VERSION ""

NS_ :

BS_:

BU_: VCM TBIOM RCIOM FCIOM CCIOM BPMU

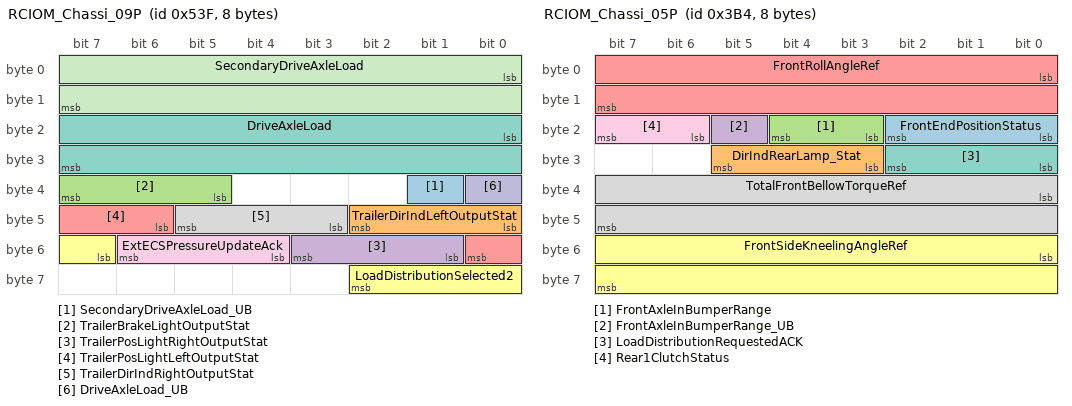
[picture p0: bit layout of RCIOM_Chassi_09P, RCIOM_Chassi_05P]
BO_ 1343 RCIOM_Chassi_09P: 8 RCIOM
 SG_ SecondaryDriveAxleLoad_UB : 33|1@1+ (1,0) [0|0] ""  VCM
 SG_ TrailerDirIndLeftOutputStat : 40|3@1+ (1,0) [0|0] ""  VCM
 SG_ TrailerBrakeLightOutputStat : 37|3@1+ (1,0) [0|0] ""  VCM
 SG_ TrailerPosLightRightOutputStat : 49|3@1+ (1,0) [0|0] ""  VCM
 SG_ TrailerPosLightLeftOutputStat : 46|3@1+ (1,0) [0|0] ""  VCM
 SG_ LoadDistributionSelected2 : 55|4@1+ (1,0) [0|0] ""  VCM
 SG_ DriveAxleLoad : 16|16@1+ (0.5,0) [0|32767.5] "kg"  VCM
 SG_ TrailerDirIndRightOutputStat : 43|3@1+ (1,0) [0|0] ""  VCM
 SG_ ExtECSPressureUpdateAck : 52|3@1+ (1,0) [0|0] ""  VCM
 SG_ DriveAxleLoad_UB : 32|1@1+ (1,0) [0|0] ""  VCM
 SG_ SecondaryDriveAxleLoad : 0|16@1+ (0.5,0) [0|32767.5] "kg"  VCM

BO_ 825 RCIOM_Chassi_08P: 8 RCIOM
 SG_ RevLightLamp_stat : 43|3@1+ (1,0) [0|0] ""  VCM
 SG_ BrakeLightConvoy_rqst_UB : 62|1@1+ (1,0) [0|0] ""  VCM
 SG_ FirstAxleLowerPrioSelected : 27|3@1+ (1,0) [0|0] ""  VCM
 SG_ FrontParkBrakeOverrideInd : 46|2@1+ (1,0) [0|0] ""  VCM
 SG_ ECSLimpHomeNotification : 19|3@1+ (1,0) [0|0] ""  VCM
 SG_ ECSValveActivationAllowed : 30|2@1+ (1,0) [0|0] ""  VCM,CCIOM
 SG_ UnevenLoadWarning : 38|2@1+ (1,0) [0|0] ""  VCM
 SG_ RampLevelRequestACK : 4|2@1+ (1,0) [0|0] ""  VCM
 SG_ LoadDistributionSelected : 12|4@1+ (1,0) [0|0] ""  VCM
 SG_ TrailerABSStatus : 2|2@1+ (1,0) [0|0] ""  VCM
 SG_ RevLight_cmd : 6|2@1+ (1,0) [0|0] ""  VCM,CCIOM
 SG_ LoadDistributionALDChangeACK : 32|3@1+ (1,0) [0|0] ""  VCM
 SG_ FogLightRearLamp_stat : 48|3@1+ (1,0) [0|0] ""  VCM
 SG_ PositionLightRearLamp_stat : 40|3@1+ (1,0) [0|0] ""  VCM
 SG_ FerryFunctionSwitchChangeACK : 0|2@1+ (1,0) [0|0] ""  VCM
 SG_ BrakeLight_rqst : 16|3@1+ (1,0) [0|0] ""  VCM
 SG_ BrakeLight_rqst_UB : 55|1@1+ (1,0) [0|0] ""  VCM
 SG_ BrakeLightConvoy_rqst : 22|2@1+ (1,0) [0|0] ""  VCM
 SG_ LiftAxle1AutoLiftSelected : 8|2@1+ (1,0) [0|0] ""  VCM
 SG_ BrakeLightLamp_stat : 35|3@1+ (1,0) [0|0] ""  VCM
 SG_ LiftAxle2AutoLiftSelected : 10|2@1+ (1,0) [0|0] ""  VCM
 SG_ StartupProhibitStatus : 53|2@1+ (1,0) [0|0] ""  VCM
 SG_ LiftAxle1LowerACK : 24|3@1+ (1,0) [0|0] ""  VCM
 SG_ TrailerDirInd_status : 56|3@1+ (1,0) [0|0] ""  VCM
 SG_ DriveLevelPosUserInteraction : 59|3@1+ (1,0) [0|0] ""  VCM

BO_ 948 RCIOM_Chassi_05P: 8 RCIOM
 SG_ FrontEndPositionStatus : 16|3@1+ (1,0) [0|0] ""  VCM
 SG_ DirIndRearLamp_Stat : 27|3@1+ (1,0) [0|0] ""  VCM
 SG_ FrontAxleInBumperRange : 19|2@1+ (1,0) [0|0] ""  VCM
 SG_ FrontAxleInBumperRange_UB : 21|1@1+ (1,0) [0|0] ""  VCM
 SG_ FrontRollAngleRef : 0|16@1+ (0.001,-30) [-30|35.535] "deg"  VCM,CCIOM
 SG_ FrontSideKneelingAngleRef : 48|16@1+ (0.001,-30) [-30|35.535] "deg"  CCIOM,VCM
 SG_ LoadDistributionRequestedACK : 24|3@1+ (1,0) [0|0] ""  VCM
 SG_ TotalFrontBellowTorqueRef : 32|16@1+ (1000,-10000000) [-10000000|55535000] "Nm"  VCM,CCIOM
 SG_ Rear1ClutchStatus : 22|2@1+ (1,0) [0|0] ""  VCM

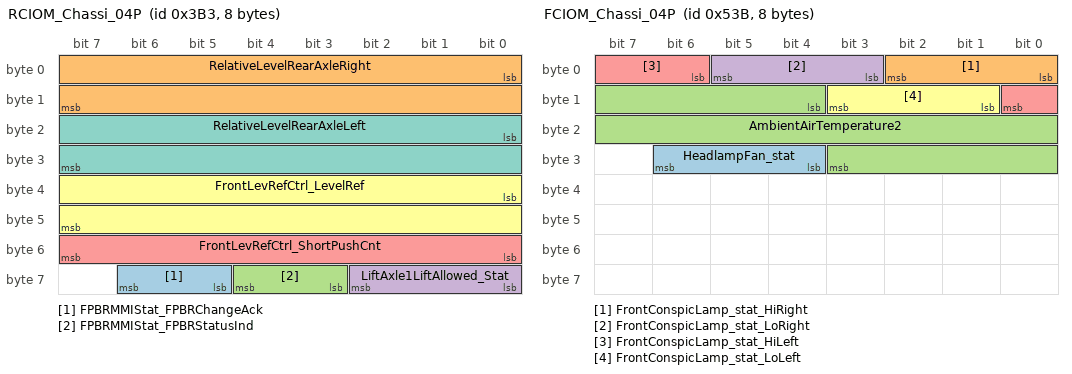
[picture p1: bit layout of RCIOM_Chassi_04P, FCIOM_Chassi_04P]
BO_ 947 RCIOM_Chassi_04P: 8 RCIOM
 SG_ FPBRMMIStat_FPBRChangeAck : 61|2@1+ (1,0) [0|0] ""  VCM
 SG_ RelativeLevelRearAxleRight : 0|16@1+ (0.1,-3200) [-3200|3353.5] "mm"  VCM
 SG_ FPBRMMIStat_FPBRStatusInd : 59|2@1+ (1,0) [0|0] ""  VCM
 SG_ LiftAxle1LiftAllowed_Stat : 56|3@1+ (1,0) [0|0] ""  VCM
 SG_ FrontLevRefCtrl_ShortPushCnt : 48|8@1+ (1,0) [0|255] "Count"  VCM,CCIOM
 SG_ FrontLevRefCtrl_LevelRef : 32|16@1+ (0.1,-3200) [-3200|3353.5] "mm"  CCIOM,VCM
 SG_ RelativeLevelRearAxleLeft : 16|16@1+ (0.1,-3200) [-3200|3353.5] "mm"  VCM

BO_ 530 RCIOM_Chassi_03P: 8 RCIOM
 SG_ AirDumpStatus : 60|3@1+ (1,0) [0|0] ""  VCM
 SG_ RearAxle2DiffLock_stat : 46|2@1+ (1,0) [0|0] ""  VCM
 SG_ SWBrakeSwitch_UB : 51|1@1+ (1,0) [0|0] ""  VCM
 SG_ SWBrakeSwitch : 49|2@1+ (1,0) [0|0] ""  VCM
 SG_ RearAxle1DiffLock_stat : 43|2@1+ (1,0) [0|0] ""  VCM
 SG_ SupplyPressure : 0|8@1+ (8,0) [0|2040] "kPa"  VCM,CCIOM
 SG_ RearAxle2DiffLock_stat_UB : 48|1@1+ (1,0) [0|0] ""  VCM
 SG_ BackToDriveReqACK : 58|2@1+ (1,0) [0|0] ""  VCM
 SG_ PitchAngleRef : 24|16@1+ (0.001,-30) [-30|35.535] "deg"  VCM,CCIOM
 SG_ TrailerConnected_UB : 54|1@1+ (1,0) [0|0] ""  VCM,CCIOM
 SG_ CentralRearDiffLock_stat_UB : 42|1@1+ (1,0) [0|0] ""  VCM
 SG_ PitchAngle : 8|16@1+ (0.001,-30) [-30|35.535] "deg"  VCM,CCIOM
 SG_ TrailerWithoutABS : 56|2@1+ (1,0) [0|0] ""  VCM
 SG_ TrailerWithoutABS_UB : 55|1@1+ (1,0) [0|0] ""  VCM
 SG_ TrailerConnected : 52|2@1+ (1,0) [0|0] ""  VCM,CCIOM
 SG_ CentralRearDiffLock_stat : 40|2@1+ (1,0) [0|0] ""  VCM
 SG_ RearAxle1DiffLock_stat_UB : 45|1@1+ (1,0) [0|0] ""  VCM

BO_ 528 RCIOM_Chassi_02P: 8 RCIOM
 SG_ RollEndPositionStatus : 3|3@1+ (1,0) [0|0] ""  VCM
 SG_ FrontFerryFunctionCmd : 59|3@1+ (1,0) [0|0] ""  VCM,CCIOM
 SG_ RideHeightFunctionStatus : 36|4@1+ (1,0) [0|0] ""  VCM
 SG_ HeightControlMode : 32|4@1+ (1,0) [0|0] ""  CCIOM,VCM
 SG_ ECSShutdownCmd : 43|2@1+ (1,0) [0|0] ""  VCM,CCIOM
 SG_ FerryFunctionStatus : 56|3@1+ (1,0) [0|0] ""  VCM
 SG_ LevelControlInformation : 16|4@1+ (1,0) [0|0] ""  VCM
 SG_ ChangeKneelACK : 45|2@1+ (1,0) [0|0] ""  VCM
 SG_ RearEndPositionStatus : 48|3@1+ (1,0) [0|0] ""  VCM
 SG_ RampHeightOutsideTargetRange : 51|3@1+ (1,0) [0|0] ""  VCM
 SG_ LoadDistributionFuncSelected : 28|4@1+ (1,0) [0|0] ""  VCM
 SG_ HeightAdjustmentAllowed : 54|2@1+ (1,0) [0|0] ""  VCM
 SG_ LevelControlInformation_UB : 40|1@1+ (1,0) [0|0] ""  VCM
 SG_ KneelingInformation : 24|4@1+ (1,0) [0|0] ""  VCM
 SG_ KneelingStatusHMI : 41|2@1+ (1,0) [0|0] ""  VCM
 SG_ LiftAxle1PositionStatus : 8|3@1+ (1,0) [0|0] ""  CCIOM,VCM
 SG_ VehicleDynamicSuspProhibitStat : 62|2@1+ (1,0) [0|0] ""  CCIOM,VCM
 SG_ LiftAxle2PositionStatus : 11|3@1+ (1,0) [0|0] ""  VCM
 SG_ RideHeightStatus : 20|4@1+ (1,0) [0|0] ""  VCM
 SG_ DirInd_Rear_Status : 0|3@1+ (1,0) [0|0] ""  VCM

BO_ 517 RCIOM_Chassi_01P: 8 RCIOM
 SG_ FrontProhibitControlRequest : 4|2@1+ (1,0) [0|0] ""  CCIOM,VCM
 SG_ RampLevelStorageAck : 24|2@1+ (1,0) [0|0] ""  VCM
 SG_ BrakePressureSensorDemand_UB : 1|1@1+ (1,0) [0|0] ""  VCM
 SG_ FrontLimpHomeCmd : 50|3@1+ (1,0) [0|0] ""  VCM,CCIOM
 SG_ LiftingControlModeRearAxle : 18|2@1+ (1,0) [0|0] ""  VCM
 SG_ LoadDistributionChangeACK : 56|3@1+ (1,0) [0|0] ""  VCM
 SG_ ECSStandbyAllowed : 32|2@1+ (1,0) [0|0] ""  VCM
 SG_ LiftAxle2LiftFuncSelected : 59|3@1+ (1,0) [0|0] ""  VCM
 SG_ LiftAxle2UpRequestACK : 34|3@1+ (1,0) [0|0] ""  VCM
 SG_ ProhibitControlStatus : 62|2@1+ (1,0) [0|0] ""  VCM
 SG_ RampLevelStatus : 46|4@1+ (1,0) [0|0] ""  VCM
 SG_ StopLevelChangeAck : 16|2@1+ (1,0) [0|0] ""  VCM
 SG_ LiftAxle2LowerACK : 37|3@1+ (1,0) [0|0] ""  VCM
 SG_ RideHeightStorageAck : 6|2@1+ (1,0) [0|0] ""  VCM
 SG_ FrontParkBrakeOverrideCommand : 22|2@1+ (1,0) [0|0] ""  VCM
 SG_ RideHeightOutsideTargetRange : 43|3@1+ (1,0) [0|0] ""  VCM
 SG_ DisableMechFaultDctnFr_rqst : 26|2@1+ (1,0) [0|0] ""  VCM,CCIOM
 SG_ RearAxleInBumperRange_UB : 0|1@1+ (1,0) [0|0] ""  VCM
 SG_ BrakePressureSensorDemand : 8|8@1+ (1,0) [0|255] "Percent"  VCM
 SG_ FogLamp_Rear_Status : 20|2@1+ (1,0) [0|0] ""  VCM
 SG_ LiftingControlModeFrontAxle : 2|2@1+ (1,0) [0|0] ""  VCM
 SG_ LiftAxle1UpRequestACK : 40|3@1+ (1,0) [0|0] ""  VCM
 SG_ LiftAxle1LiftFuncSelected : 53|3@1+ (1,0) [0|0] ""  VCM
 SG_ RearAxleInBumperRange : 30|2@1+ (1,0) [0|0] ""  VCM

BO_ 2671833639 PhysDiagRespMsg_F2_27_C04: 8 TBIOM
 SG_ PhysDiagRespSig_F2_27 : 0|64@1+ (1,0) [0|0] ""  VCM

BO_ 2671833634 PhysDiagRespMsg_F2_22_C04: 8 RCIOM
 SG_ PhysDiagRespSig_F2_22 : 0|64@1+ (1,0) [0|0] ""  VCM

BO_ 2671833633 PhysDiagRespMsg_F2_21_C04: 8 FCIOM
 SG_ PhysDiagRespSig_F2_21 : 0|64@1+ (1,0) [0|0] ""  VCM

BO_ 2671833632 PhysDiagRespMsg_F2_20_C04: 8 CCIOM
 SG_ PhysDiagRespSig_F2_20 : 0|64@1+ (1,0) [0|0] ""  VCM

BO_ 2671833626 PhysDiagRespMsg_F2_1A_C04: 8 BPMU
 SG_ PhysDiagRespSig_F2_1A : 0|64@1+ (1,0) [0|0] ""  VCM

BO_ 2671781874 PhysDiagReqMsg_27_F2_C04: 8 VCM
 SG_ PhysDiagReqSig_27_F2 : 0|64@1+ (1,0) [0|0] ""  TBIOM

BO_ 2671780594 PhysDiagReqMsg_22_F2_C04: 8 VCM
 SG_ PhysDiagReqSig_22_F2 : 0|64@1+ (1,0) [0|0] ""  RCIOM

BO_ 2671780338 PhysDiagReqMsg_21_F2_C04: 8 VCM
 SG_ PhysDiagReqSig_21_F2 : 0|64@1+ (1,0) [0|0] ""  FCIOM

BO_ 2671780082 PhysDiagReqMsg_20_F2_C04: 8 VCM
 SG_ PhysDiagReqSig_20_F2 : 0|64@1+ (1,0) [0|0] ""  CCIOM

BO_ 2671778546 PhysDiagReqMsg_1A_F2_C04: 8 VCM
 SG_ PhysDiagReqSig_1A_F2 : 0|64@1+ (1,0) [0|0] ""  BPMU

BO_ 2633990180 NmAsr_VCM_C04: 1 VCM

BO_ 2633990183 NmAsr_TBIOM_C04: 1 TBIOM

BO_ 2633990178 NmAsr_RCIOM_C04: 1 RCIOM

BO_ 2633990177 NmAsr_FCIOM_C04: 1 FCIOM

BO_ 2633990176 NmAsr_CCIOM_C04: 1 CCIOM

BO_ 2633990170 NmAsr_BPMU_C04: 1 BPMU

BO_ 1339 FCIOM_Chassi_04P: 8 FCIOM
 SG_ HeadlampFan_stat : 28|3@1+ (1,0) [0|0] ""  VCM
 SG_ FrontConspicLamp_stat_HiRight : 0|3@1+ (1,0) [0|0] ""  VCM
 SG_ AmbientAirTemperature2 : 12|16@1+ (0.03125,-273) [-273|1774.96875] "DegreeC"  VCM
 SG_ FrontConspicLamp_stat_LoRight : 3|3@1+ (1,0) [0|0] ""  VCM
 SG_ FrontConspicLamp_stat_HiLeft : 6|3@1+ (1,0) [0|0] ""  VCM
 SG_ FrontConspicLamp_stat_LoLeft : 9|3@1+ (1,0) [0|0] ""  VCM

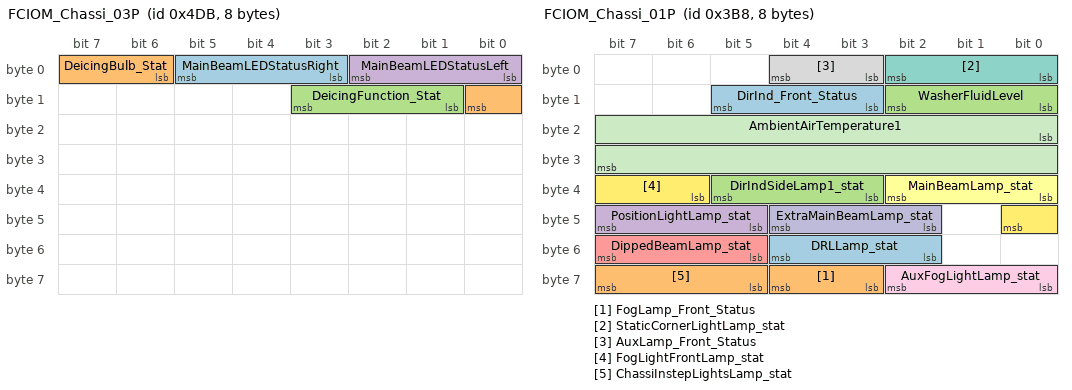
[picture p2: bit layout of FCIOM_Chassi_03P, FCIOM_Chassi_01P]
BO_ 1243 FCIOM_Chassi_03P: 8 FCIOM
 SG_ MainBeamLEDStatusRight : 3|3@1+ (1,0) [0|0] ""  VCM
 SG_ DeicingBulb_Stat : 6|3@1+ (1,0) [0|0] ""  VCM
 SG_ DeicingFunction_Stat : 9|3@1+ (1,0) [0|0] ""  VCM
 SG_ MainBeamLEDStatusLeft : 0|3@1+ (1,0) [0|0] ""  VCM

BO_ 952 FCIOM_Chassi_01P: 8 FCIOM
 SG_ DRLLamp_stat : 50|3@1+ (1,0) [0|0] ""  VCM
 SG_ FogLamp_Front_Status : 59|2@1+ (1,0) [0|0] ""  VCM
 SG_ DirIndSideLamp1_stat : 35|3@1+ (1,0) [0|0] ""  VCM
 SG_ PositionLightLamp_stat : 45|3@1+ (1,0) [0|0] ""  VCM
 SG_ DippedBeamLamp_stat : 53|3@1+ (1,0) [0|0] ""  VCM
 SG_ MainBeamLamp_stat : 32|3@1+ (1,0) [0|0] ""  VCM
 SG_ StaticCornerLightLamp_stat : 0|3@1+ (1,0) [0|0] ""  VCM
 SG_ AuxLamp_Front_Status : 3|2@1+ (1,0) [0|0] ""  VCM
 SG_ AuxFogLightLamp_stat : 56|3@1+ (1,0) [0|0] ""  VCM
 SG_ ExtraMainBeamLamp_stat : 42|3@1+ (1,0) [0|0] ""  VCM
 SG_ AmbientAirTemperature1 : 16|16@1+ (0.03125,-273) [-273|1774.96875] "DegreeC"  VCM
 SG_ FogLightFrontLamp_stat : 38|3@1+ (1,0) [0|0] ""  VCM
 SG_ DirInd_Front_Status : 11|3@1+ (1,0) [0|0] ""  VCM
 SG_ ChassiInstepLightsLamp_stat : 61|3@1+ (1,0) [0|0] ""  VCM
 SG_ WasherFluidLevel : 8|3@1+ (1,0) [0|0] ""  VCM

BO_ 1232 EBS_Chassi_13P: 8 VCM
 SG_ TrailerCommunicationType : 26|3@1+ (1,0) [0|0] ""  RCIOM

BO_ 396 EBS_Chassi_08P: 8 VCM
 SG_ ThrdRrDriveAxLeftWheelSpeed : 32|16@1+ (0.00390625,0) [0|255.99609375] "Km_per_h"  RCIOM
 SG_ ThrdRrDriveAxRightWheelSpeed : 48|16@1+ (0.00390625,0) [0|255.99609375] "Km_per_h"  RCIOM

BO_ 395 EBS_Chassi_07P: 8 VCM
 SG_ SteeringWheelAngle : 0|16@1+ (0.0009765625,-31.374) [-31.374|32.6250234375] "rad"  RCIOM
 SG_ SteeringWheelAngle_UB : 48|1@1+ (1,0) [0|0] ""  RCIOM

BO_ 394 EBS_Chassi_06P: 8 VCM
 SG_ ScndRrDriveAxleLeftWheelSpeed : 48|16@1+ (0.00390625,0) [0|255.99609375] "Km_per_h"  CCIOM,RCIOM
 SG_ ScndRrDriveAxleRightWheelSpeed : 0|16@1+ (0.00390625,0) [0|255.99609375] "Km_per_h"  RCIOM,CCIOM

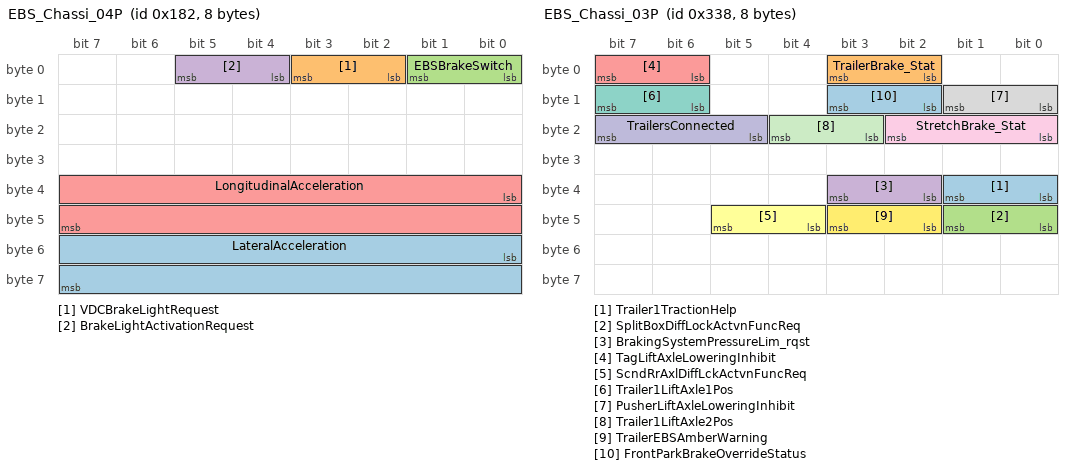
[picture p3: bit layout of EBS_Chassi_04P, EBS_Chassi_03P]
BO_ 386 EBS_Chassi_04P: 8 VCM
 SG_ LateralAcceleration : 48|16@1+ (0.00048828125,-15.687) [-15.687|16.31251171875] "m_per_s_squared"  RCIOM
 SG_ VDCBrakeLightRequest : 2|2@1+ (1,0) [0|0] ""  RCIOM
 SG_ EBSBrakeSwitch : 0|2@1+ (1,0) [0|0] ""  RCIOM
 SG_ BrakeLightActivationRequest : 4|2@1+ (1,0) [0|0] ""  RCIOM
 SG_ LongitudinalAcceleration : 32|16@1+ (0.00048828125,-15.687) [-15.687|16.31251171875] "m_per_s_squared"  RCIOM

BO_ 824 EBS_Chassi_03P: 8 VCM
 SG_ Trailer1TractionHelp : 32|2@1+ (1,0) [0|0] ""  RCIOM
 SG_ TrailerBrake_Stat : 2|2@1+ (1,0) [0|0] ""  RCIOM
 SG_ SplitBoxDiffLockActvnFuncReq : 40|2@1+ (1,0) [0|0] ""  CCIOM
 SG_ BrakingSystemPressureLim_rqst : 34|2@1+ (1,0) [0|0] ""  CCIOM
 SG_ TagLiftAxleLoweringInhibit : 6|2@1+ (1,0) [0|0] ""  RCIOM
 SG_ ScndRrAxlDiffLckActvnFuncReq : 44|2@1+ (1,0) [0|0] ""  RCIOM
 SG_ Trailer1LiftAxle1Pos : 14|2@1+ (1,0) [0|0] ""  RCIOM
 SG_ PusherLiftAxleLoweringInhibit : 8|2@1+ (1,0) [0|0] ""  RCIOM
 SG_ StretchBrake_Stat : 16|3@1+ (1,0) [0|0] ""  RCIOM
 SG_ TrailersConnected : 21|3@1+ (1,0) [0|7] "Count"  RCIOM
 SG_ Trailer1LiftAxle2Pos : 19|2@1+ (1,0) [0|0] ""  RCIOM
 SG_ TrailerEBSAmberWarning : 42|2@1+ (1,0) [0|0] ""  RCIOM
 SG_ FrontParkBrakeOverrideStatus : 10|2@1+ (1,0) [0|0] ""  RCIOM

BO_ 516 EAS_Chassi_01P: 8 VCM
 SG_ EASPusherLiftAxleLoweringInhib : 32|2@1+ (1,0) [0|0] ""  RCIOM

BO_ 1110 DummyFrame_VCM_C_C04: 8 VCM
 SG_ DummyApplicationSignal : 0|8@1+ (1,0) [0|255] ""  CCIOM,BPMU,FCIOM,RCIOM,TBIOM

BO_ 2671964711 DiagUUDTRespMsg1_F2_27_C04: 8 TBIOM
 SG_ DiagUUDTRespSig_F2_27 : 0|64@1+ (1,0) [0|0] ""  VCM

BO_ 2671964706 DiagUUDTRespMsg1_F2_22_C04: 8 RCIOM
 SG_ DiagUUDTRespSig_F2_22 : 0|64@1+ (1,0) [0|0] ""  VCM

BO_ 2671964705 DiagUUDTRespMsg1_F2_21_C04: 8 FCIOM
 SG_ DiagUUDTRespSig_F2_21 : 0|64@1+ (1,0) [0|0] ""  VCM

BO_ 2671964704 DiagUUDTRespMsg1_F2_20_C04: 8 CCIOM
 SG_ DiagUUDTRespSig_F2_20 : 0|64@1+ (1,0) [0|0] ""  VCM

BO_ 2671964698 DiagUUDTRespMsg1_F2_1A_C04: 8 BPMU
 SG_ DiagUUDTRespSig_F2_1A : 0|64@1+ (1,0) [0|0] ""  VCM

BO_ 2671834151 DiagRespMsgForIntTest_F4_27_C04: 8 TBIOM
 SG_ InternalTesterDiagSig_F4_27 : 0|64@1+ (1,0) [0|0] ""  VCM

BO_ 2671834146 DiagRespMsgForIntTest_F4_22_C04: 8 RCIOM
 SG_ InternalTesterDiagSig_F4_22 : 0|64@1+ (1,0) [0|0] ""  VCM

BO_ 2671834145 DiagRespMsgForIntTest_F4_21_C04: 8 FCIOM
 SG_ InternalTesterDiagSig_F4_21 : 0|64@1+ (1,0) [0|0] ""  VCM

BO_ 2671834144 DiagRespMsgForIntTest_F4_20_C04: 8 CCIOM
 SG_ InternalTesterDiagSig_F4_20 : 0|64@1+ (1,0) [0|0] ""  VCM

BO_ 2671834138 DiagRespMsgForIntTest_F4_1A_C04: 8 BPMU
 SG_ InternalTesterDiagSig_F4_1A : 0|64@1+ (1,0) [0|0] ""  VCM

BO_ 2671781876 DiagReqMsgOfIntTest_27_F4_C04: 8 VCM
 SG_ InternalTesterDiagSig_27_F4 : 0|64@1+ (1,0) [0|0] ""  TBIOM

BO_ 2671780596 DiagReqMsgOfIntTest_22_F4_C04: 8 VCM
 SG_ InternalTesterDiagSig_22_F4 : 0|64@1+ (1,0) [0|0] ""  RCIOM

BO_ 2671780340 DiagReqMsgOfIntTest_21_F4_C04: 8 VCM
 SG_ InternalTesterDiagSig_21_F4 : 0|64@1+ (1,0) [0|0] ""  FCIOM

BO_ 2671780084 DiagReqMsgOfIntTest_20_F4_C04: 8 VCM
 SG_ InternalTesterDiagSig_20_F4 : 0|64@1+ (1,0) [0|0] ""  CCIOM

BO_ 2671778548 DiagReqMsgOfIntTest_1A_F4_C04: 8 VCM
 SG_ InternalTesterDiagSig_1A_F4 : 0|64@1+ (1,0) [0|0] ""  BPMU

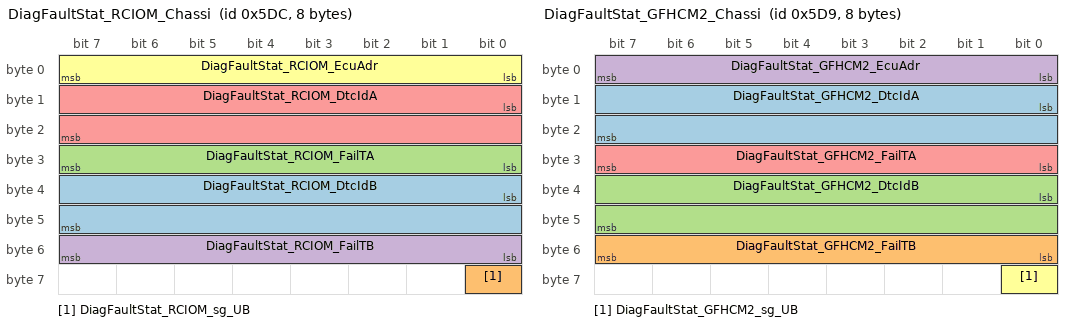
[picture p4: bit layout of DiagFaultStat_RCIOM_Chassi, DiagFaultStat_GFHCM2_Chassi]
BO_ 1500 DiagFaultStat_RCIOM_Chassi: 8 RCIOM
 SG_ DiagFaultStat_RCIOM_DtcIdB : 32|16@1+ (1,0) [0|65535] ""  VCM
 SG_ DiagFaultStat_RCIOM_sg_UB : 56|1@1+ (1,0) [0|0] ""  VCM
 SG_ DiagFaultStat_RCIOM_FailTA : 24|8@1+ (1,0) [0|255] ""  VCM
 SG_ DiagFaultStat_RCIOM_FailTB : 48|8@1+ (1,0) [0|255] ""  VCM
 SG_ DiagFaultStat_RCIOM_DtcIdA : 8|16@1+ (1,0) [0|65535] ""  VCM
 SG_ DiagFaultStat_RCIOM_EcuAdr : 0|8@1+ (1,0) [0|255] ""  VCM

BO_ 1497 DiagFaultStat_GFHCM2_Chassi: 8 FCIOM
 SG_ DiagFaultStat_GFHCM2_DtcIdA : 8|16@1+ (1,0) [0|65535] ""  VCM
 SG_ DiagFaultStat_GFHCM2_FailTB : 48|8@1+ (1,0) [0|255] ""  VCM
 SG_ DiagFaultStat_GFHCM2_DtcIdB : 32|16@1+ (1,0) [0|65535] ""  VCM
 SG_ DiagFaultStat_GFHCM2_EcuAdr : 0|8@1+ (1,0) [0|255] ""  VCM
 SG_ DiagFaultStat_GFHCM2_FailTA : 24|8@1+ (1,0) [0|255] ""  VCM
 SG_ DiagFaultStat_GFHCM2_sg_UB : 56|1@1+ (1,0) [0|0] ""  VCM

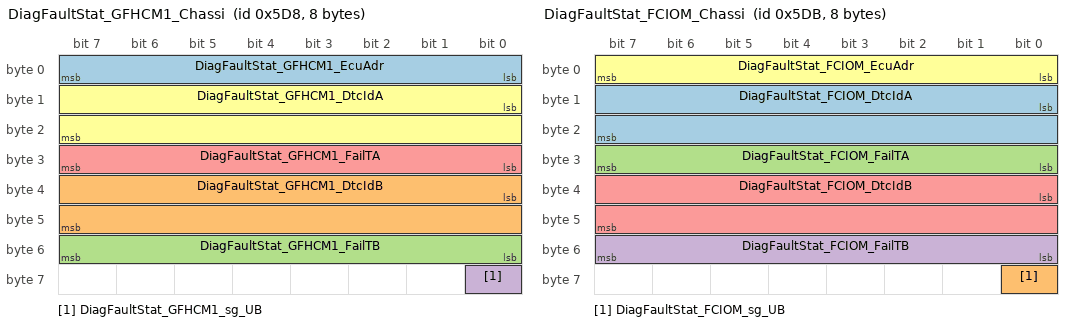
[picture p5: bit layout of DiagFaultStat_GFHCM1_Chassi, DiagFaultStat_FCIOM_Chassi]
BO_ 1496 DiagFaultStat_GFHCM1_Chassi: 8 FCIOM
 SG_ DiagFaultStat_GFHCM1_EcuAdr : 0|8@1+ (1,0) [0|255] ""  VCM
 SG_ DiagFaultStat_GFHCM1_DtcIdB : 32|16@1+ (1,0) [0|65535] ""  VCM
 SG_ DiagFaultStat_GFHCM1_FailTB : 48|8@1+ (1,0) [0|255] ""  VCM
 SG_ DiagFaultStat_GFHCM1_sg_UB : 56|1@1+ (1,0) [0|0] ""  VCM
 SG_ DiagFaultStat_GFHCM1_FailTA : 24|8@1+ (1,0) [0|255] ""  VCM
 SG_ DiagFaultStat_GFHCM1_DtcIdA : 8|16@1+ (1,0) [0|65535] ""  VCM

BO_ 1499 DiagFaultStat_FCIOM_Chassi: 8 FCIOM
 SG_ DiagFaultStat_FCIOM_DtcIdA : 8|16@1+ (1,0) [0|65535] ""  VCM
 SG_ DiagFaultStat_FCIOM_sg_UB : 56|1@1+ (1,0) [0|0] ""  VCM
 SG_ DiagFaultStat_FCIOM_FailTA : 24|8@1+ (1,0) [0|255] ""  VCM
 SG_ DiagFaultStat_FCIOM_FailTB : 48|8@1+ (1,0) [0|255] ""  VCM
 SG_ DiagFaultStat_FCIOM_DtcIdB : 32|16@1+ (1,0) [0|65535] ""  VCM
 SG_ DiagFaultStat_FCIOM_EcuAdr : 0|8@1+ (1,0) [0|255] ""  VCM

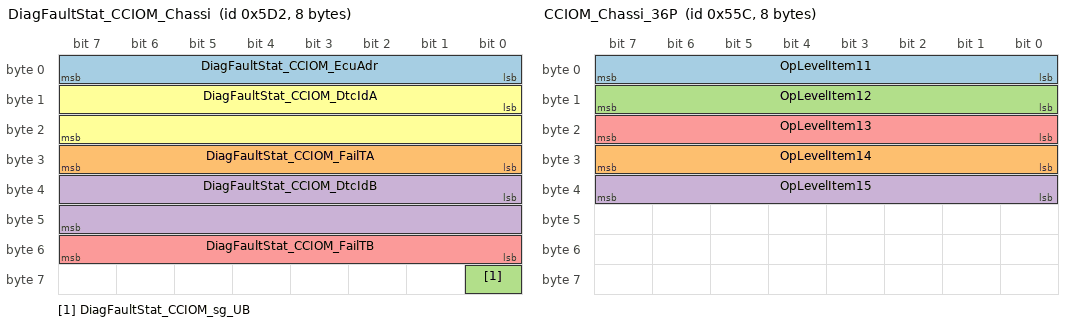
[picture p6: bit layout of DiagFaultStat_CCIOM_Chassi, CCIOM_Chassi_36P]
BO_ 1490 DiagFaultStat_CCIOM_Chassi: 8 CCIOM
 SG_ DiagFaultStat_CCIOM_EcuAdr : 0|8@1+ (1,0) [0|255] ""  VCM
 SG_ DiagFaultStat_CCIOM_FailTA : 24|8@1+ (1,0) [0|255] ""  VCM
 SG_ DiagFaultStat_CCIOM_sg_UB : 56|1@1+ (1,0) [0|0] ""  VCM
 SG_ DiagFaultStat_CCIOM_DtcIdB : 32|16@1+ (1,0) [0|65535] ""  VCM
 SG_ DiagFaultStat_CCIOM_FailTB : 48|8@1+ (1,0) [0|255] ""  VCM
 SG_ DiagFaultStat_CCIOM_DtcIdA : 8|16@1+ (1,0) [0|65535] ""  VCM

BO_ 1372 CCIOM_Chassi_36P: 8 CCIOM
 SG_ OpLevelItem11 : 0|8@1+ (0.5,0) [0|127.5] "Percent"  VCM
 SG_ OpLevelItem14 : 24|8@1+ (0.5,0) [0|127.5] "Percent"  VCM
 SG_ OpLevelItem12 : 8|8@1+ (0.5,0) [0|127.5] "Percent"  VCM
 SG_ OpLevelItem15 : 32|8@1+ (0.5,0) [0|127.5] "Percent"  VCM
 SG_ OpLevelItem13 : 16|8@1+ (0.5,0) [0|127.5] "Percent"  VCM

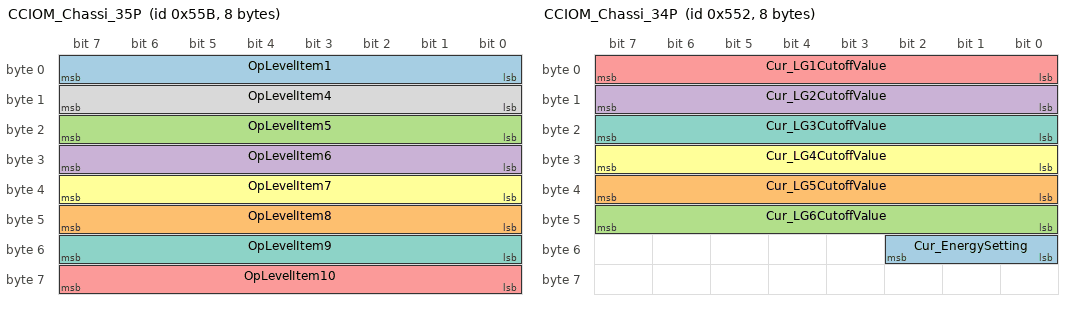
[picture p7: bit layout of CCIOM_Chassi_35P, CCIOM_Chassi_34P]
BO_ 1371 CCIOM_Chassi_35P: 8 CCIOM
 SG_ OpLevelItem1 : 0|8@1+ (0.5,0) [0|127.5] "Percent"  VCM
 SG_ OpLevelItem8 : 40|8@1+ (0.5,0) [0|127.5] "Percent"  VCM
 SG_ OpLevelItem5 : 16|8@1+ (0.5,0) [0|127.5] "Percent"  VCM
 SG_ OpLevelItem6 : 24|8@1+ (0.5,0) [0|127.5] "Percent"  VCM
 SG_ OpLevelItem10 : 56|8@1+ (0.5,0) [0|127.5] "Percent"  VCM
 SG_ OpLevelItem7 : 32|8@1+ (0.5,0) [0|127.5] "Percent"  VCM
 SG_ OpLevelItem9 : 48|8@1+ (0.5,0) [0|127.5] "Percent"  VCM
 SG_ OpLevelItem4 : 8|8@1+ (0.5,0) [0|127.5] "Percent"  VCM

BO_ 1362 CCIOM_Chassi_34P: 8 CCIOM
 SG_ Cur_EnergySetting : 48|3@1+ (1,0) [0|0] ""  VCM
 SG_ Cur_LG5CutoffValue : 32|8@1+ (1,0) [0|255] "Percent"  VCM
 SG_ Cur_LG6CutoffValue : 40|8@1+ (1,0) [0|255] "Percent"  VCM
 SG_ Cur_LG2CutoffValue : 8|8@1+ (1,0) [0|255] "Percent"  VCM
 SG_ Cur_LG1CutoffValue : 0|8@1+ (1,0) [0|255] "Percent"  VCM
 SG_ Cur_LG4CutoffValue : 24|8@1+ (1,0) [0|255] "Percent"  VCM
 SG_ Cur_LG3CutoffValue : 16|8@1+ (1,0) [0|255] "Percent"  VCM

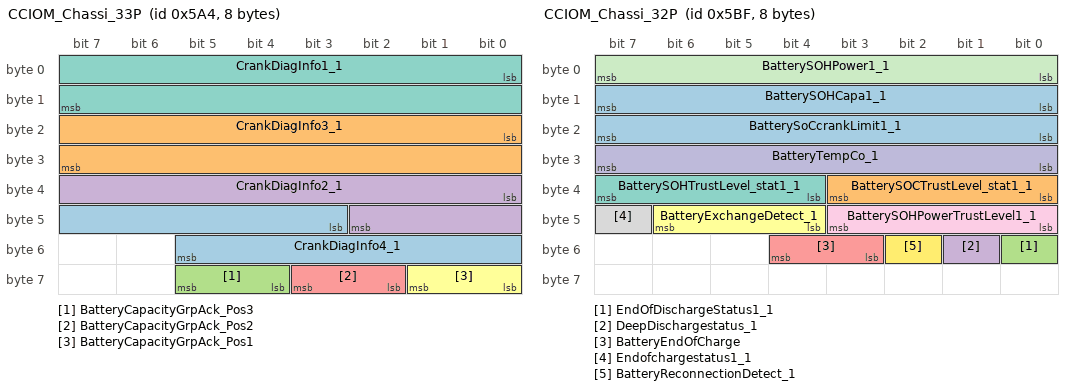
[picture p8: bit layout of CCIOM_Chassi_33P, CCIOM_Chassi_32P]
BO_ 1444 CCIOM_Chassi_33P: 8 CCIOM
 SG_ CrankDiagInfo4_1 : 43|11@1+ (0.025,0) [0|51.175] "V"  VCM
 SG_ CrankDiagInfo3_1 : 16|16@1+ (0.05,-2000) [-2000|1276.75] "A"  VCM
 SG_ BatteryCapacityGrpAck_Pos3 : 60|2@1+ (1,0) [0|0] ""  VCM
 SG_ CrankDiagInfo2_1 : 32|11@1+ (0.025,0) [0|51.175] "V"  VCM
 SG_ BatteryCapacityGrpAck_Pos2 : 58|2@1+ (1,0) [0|0] ""  VCM
 SG_ BatteryCapacityGrpAck_Pos1 : 56|2@1+ (1,0) [0|0] ""  VCM
 SG_ CrankDiagInfo1_1 : 0|16@1+ (0.05,-2000) [-2000|1276.75] "A"  VCM

BO_ 1471 CCIOM_Chassi_32P: 8 CCIOM
 SG_ BatterySOHCapa1_1 : 8|8@1+ (0.5,0) [0|127.5] "Percent"  VCM
 SG_ BatterySOCTrustLevel_stat1_1 : 32|4@1+ (1,0) [0|0] ""  VCM
 SG_ EndOfDischargeStatus1_1 : 48|1@1+ (1,0) [0|0] ""  VCM
 SG_ DeepDischargestatus_1 : 49|1@1+ (1,0) [0|0] ""  VCM
 SG_ BatteryEndOfCharge : 51|2@1+ (1,0) [0|0] ""  VCM
 SG_ BatteryExchangeDetect_1 : 44|3@1+ (1,0) [0|0] ""  VCM
 SG_ BatterySOHTrustLevel_stat1_1 : 36|4@1+ (1,0) [0|0] ""  VCM
 SG_ Endofchargestatus1_1 : 47|1@1+ (1,0) [0|0] ""  VCM
 SG_ BatterySOHPowerTrustLevel1_1 : 40|4@1+ (1,0) [0|0] ""  VCM
 SG_ BatteryTempCo_1 : 24|8@1+ (1,0) [0|255] "Percent"  VCM
 SG_ BatterySOHPower1_1 : 0|8@1+ (0.1,0) [0|25.5] "V"  VCM
 SG_ BatteryReconnectionDetect_1 : 50|1@1+ (1,0) [0|0] ""  VCM
 SG_ BatterySoCcrankLimit1_1 : 16|8@1+ (1,0) [0|255] "Percent"  VCM

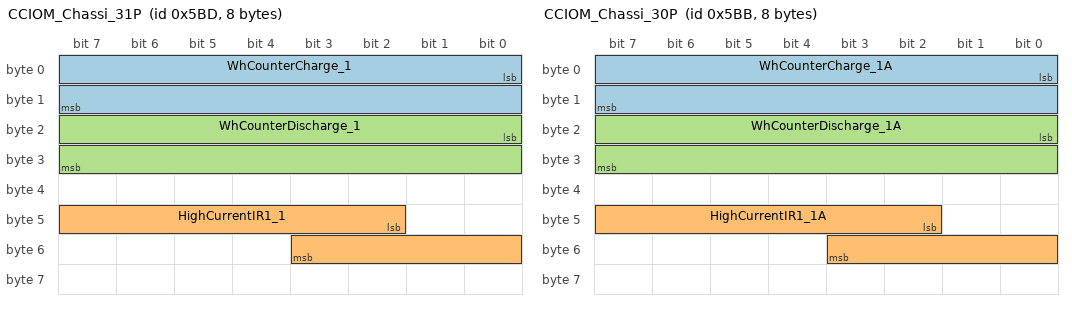
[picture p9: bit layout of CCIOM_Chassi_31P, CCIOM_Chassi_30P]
BO_ 1469 CCIOM_Chassi_31P: 8 CCIOM
 SG_ WhCounterCharge_1 : 0|16@1+ (50,0) [0|3276750] "Wh"  VCM
 SG_ HighCurrentIR1_1 : 42|10@1+ (1E-005,0) [0|0.01023] "Ohm"  VCM
 SG_ WhCounterDischarge_1 : 16|16@1+ (50,0) [0|3276750] "Wh"  VCM

BO_ 1467 CCIOM_Chassi_30P: 8 CCIOM
 SG_ WhCounterCharge_1A : 0|16@1+ (50,0) [0|3276750] "Wh"  VCM
 SG_ HighCurrentIR1_1A : 42|10@1+ (1E-005,0) [0|0.01023] "Ohm"  VCM
 SG_ WhCounterDischarge_1A : 16|16@1+ (50,0) [0|3276750] "Wh"  VCM

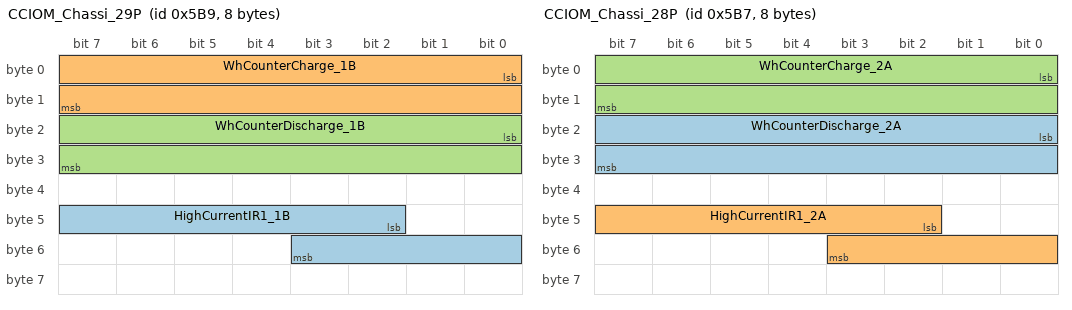
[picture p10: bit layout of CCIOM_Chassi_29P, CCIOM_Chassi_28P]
BO_ 1465 CCIOM_Chassi_29P: 8 CCIOM
 SG_ HighCurrentIR1_1B : 42|10@1+ (1E-005,0) [0|0.01023] "Ohm"  VCM
 SG_ WhCounterCharge_1B : 0|16@1+ (50,0) [0|3276750] "Wh"  VCM
 SG_ WhCounterDischarge_1B : 16|16@1+ (50,0) [0|3276750] "Wh"  VCM

BO_ 1463 CCIOM_Chassi_28P: 8 CCIOM
 SG_ WhCounterDischarge_2A : 16|16@1+ (50,0) [0|3276750] "Wh"  VCM
 SG_ HighCurrentIR1_2A : 42|10@1+ (1E-005,0) [0|0.01023] "Ohm"  VCM
 SG_ WhCounterCharge_2A : 0|16@1+ (50,0) [0|3276750] "Wh"  VCM

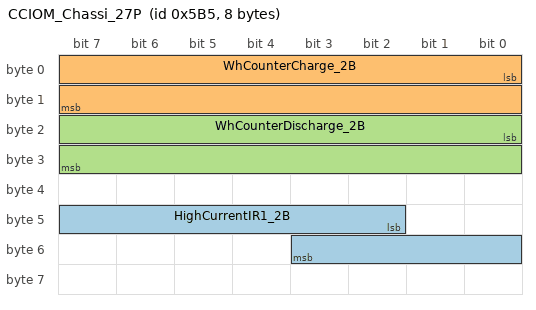
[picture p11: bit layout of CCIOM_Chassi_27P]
BO_ 1461 CCIOM_Chassi_27P: 8 CCIOM
 SG_ HighCurrentIR1_2B : 42|10@1+ (1E-005,0) [0|0.01023] "Ohm"  VCM
 SG_ WhCounterCharge_2B : 0|16@1+ (50,0) [0|3276750] "Wh"  VCM
 SG_ WhCounterDischarge_2B : 16|16@1+ (50,0) [0|3276750] "Wh"  VCM

BA_DEF_ BO_  "GenMsgStartDelayTime" INT 0 0;
BA_DEF_ BO_  "GenMsgDelayTime" INT 0 0;
BA_DEF_ BO_  "GenMsgCycleTime" INT 0 0;
BA_DEF_ BO_  "GenMsgSendType" ENUM  "Cyclic","NotUsed","NotUsed","NotUsed","NotUsed","NotUsed","NotUsed","IfActive","NoMsgSendType","NotUsed";
BA_DEF_ SG_  "GenSigStartValue" INT 0 0;
BA_DEF_ SG_  "GenSigInactiveValue" INT 0 0;
BA_DEF_ SG_  "GenSigCycleTimeActive" INT 0 0;
BA_DEF_ SG_  "GenSigCycleTime" INT 0 0;
BA_DEF_ SG_  "GenSigSendType" ENUM  "Cyclic","OnWrite","OnWriteWithRepetition","OnChange","OnChangeWithRepetition","IfActive","IfActiveWithRepetition","NoSigSendType","NotUsed","NotUsed","NotUsed","NotUsed","NotUsed";
BA_DEF_ BO_  "VFrameFormat" ENUM  "StandardCAN","ExtendedCAN","reserved","J1939PG","reserved","reserved","reserved","reserved","reserved","reserved","reserved","reserved","reserved","reserved","StandardCAN_FD","ExtendedCAN_FD";
BA_DEF_ SG_  "SigType" ENUM  "Default","Range","RangeSigned","ASCII","Discrete","Control","ReferencePGN","DTC","StringDelimiter","StringLength","StringLengthControl";
BA_DEF_ SG_  "Platform_Vivis2_Sig" ENUM  "No","Yes";
BA_DEF_ SG_  "Platform_VMCU1_Sig" ENUM  "No","Yes";
BA_DEF_ BO_  "NmAsrMessage" ENUM  "No","Yes";
BA_DEF_ SG_  "NeedsUpdateBit" ENUM  "No","Yes";
BA_DEF_ SG_  "MmAnSignal" ENUM  "No","Yes";
BA_DEF_ SG_  "GenSigMaxLatency" INT 0 65535;
BA_DEF_ SG_  "GenSigILSupport" ENUM  "Yes","No";
BA_DEF_ BO_  "GenMsgILSupport" ENUM  "No","Yes";
BA_DEF_ SG_  "E2EProfile" STRING ;
BA_DEF_ SG_  "E2EDataLength" INT 0 65535;
BA_DEF_ SG_  "E2EDataId" INT 0 65535;
BA_DEF_ BO_  "DiagUUDTResponse" ENUM  "No","Yes";
BA_DEF_ BO_  "DiagState" ENUM  "No","Yes";
BA_DEF_ BO_  "DiagResponse" ENUM  "No","Yes";
BA_DEF_ BO_  "DiagRequest" ENUM  "No","Yes";
BA_DEF_ BO_  "DiagConnection" HEX 0 65535;
BA_DEF_ BO_  "CanTpFcFrameId" HEX 0 2147483647;
BA_DEF_ BO_  "CanTpBs" INT 0 255;
BA_DEF_ SG_  "SystemSignalLongSymbol" STRING ;
BA_DEF_REL_ BU_SG_REL_  "GenSigTimeoutTime" INT 0 65535;
BA_DEF_REL_ BU_SG_REL_  "GenSigFirstTimeoutTime" INT 0 65535;
BA_DEF_DEF_  "GenMsgStartDelayTime" 0;
BA_DEF_DEF_  "GenMsgDelayTime" 0;
BA_DEF_DEF_  "GenMsgCycleTime" 0;
BA_DEF_DEF_  "GenMsgSendType" "Cyclic";
BA_DEF_DEF_  "GenSigStartValue" 0;
BA_DEF_DEF_  "GenSigInactiveValue" 0;
BA_DEF_DEF_  "GenSigCycleTimeActive" 0;
BA_DEF_DEF_  "GenSigCycleTime" 0;
BA_DEF_DEF_  "GenSigSendType" "Cyclic";
BA_DEF_DEF_  "VFrameFormat" "ExtendedCAN";
BA_DEF_DEF_  "SigType" "Default";
BA_DEF_DEF_  "Platform_Vivis2_Sig" "No";
BA_DEF_DEF_  "Platform_VMCU1_Sig" "No";
BA_DEF_DEF_  "NmAsrMessage" "No";
BA_DEF_DEF_  "NeedsUpdateBit" "No";
BA_DEF_DEF_  "MmAnSignal" "No";
BA_DEF_DEF_  "GenSigMaxLatency" 0;
BA_DEF_DEF_  "GenSigILSupport" "Yes";
BA_DEF_DEF_  "GenMsgILSupport" "Yes";
BA_DEF_DEF_  "E2EProfile" "none";
BA_DEF_DEF_  "E2EDataLength" 0;
BA_DEF_DEF_  "E2EDataId" 0;
BA_DEF_DEF_  "DiagUUDTResponse" "No";
BA_DEF_DEF_  "DiagState" "No";
BA_DEF_DEF_  "DiagResponse" "No";
BA_DEF_DEF_  "DiagRequest" "No";
BA_DEF_DEF_  "DiagConnection" 0;
BA_DEF_DEF_  "CanTpFcFrameId" 2147483647;
BA_DEF_DEF_  "CanTpBs" 255;
BA_DEF_DEF_REL_ "GenSigTimeoutTime" 0;
BA_DEF_DEF_REL_ "GenSigFirstTimeoutTime" 0;
BA_DEF_DEF_  "SystemSignalLongSymbol" "";
BA_ "VFrameFormat" BO_ 1343 0;
BA_ "GenMsgCycleTime" BO_ 1343 250;
BA_ "GenMsgStartDelayTime" BO_ 1343 50;
BA_ "VFrameFormat" BO_ 825 0;
BA_ "GenMsgCycleTime" BO_ 825 30;
BA_ "GenMsgStartDelayTime" BO_ 825 5;
BA_ "VFrameFormat" BO_ 948 0;
BA_ "GenMsgCycleTime" BO_ 948 50;
BA_ "GenMsgStartDelayTime" BO_ 948 30;
BA_ "VFrameFormat" BO_ 947 0;
BA_ "GenMsgCycleTime" BO_ 947 50;
BA_ "GenMsgStartDelayTime" BO_ 947 10;
BA_ "VFrameFormat" BO_ 530 0;
BA_ "GenMsgCycleTime" BO_ 530 20;
BA_ "GenMsgStartDelayTime" BO_ 530 10;
BA_ "VFrameFormat" BO_ 528 0;
BA_ "GenMsgCycleTime" BO_ 528 20;
BA_ "GenMsgStartDelayTime" BO_ 528 5;
BA_ "VFrameFormat" BO_ 517 0;
BA_ "GenMsgCycleTime" BO_ 517 20;
BA_ "GenMsgStartDelayTime" BO_ 517 5;
BA_ "DiagConnection" BO_ 2671833639 61991;
BA_ "DiagResponse" BO_ 2671833639 1;
BA_ "GenMsgILSupport" BO_ 2671833639 0;
BA_ "GenMsgSendType" BO_ 2671833639 8;
BA_ "DiagConnection" BO_ 2671833634 61986;
BA_ "DiagResponse" BO_ 2671833634 1;
BA_ "GenMsgILSupport" BO_ 2671833634 0;
BA_ "GenMsgSendType" BO_ 2671833634 8;
BA_ "DiagConnection" BO_ 2671833633 61985;
BA_ "DiagResponse" BO_ 2671833633 1;
BA_ "GenMsgILSupport" BO_ 2671833633 0;
BA_ "GenMsgSendType" BO_ 2671833633 8;
BA_ "DiagConnection" BO_ 2671833632 61984;
BA_ "DiagResponse" BO_ 2671833632 1;
BA_ "GenMsgILSupport" BO_ 2671833632 0;
BA_ "GenMsgSendType" BO_ 2671833632 8;
BA_ "DiagConnection" BO_ 2671833626 61978;
BA_ "DiagResponse" BO_ 2671833626 1;
BA_ "GenMsgILSupport" BO_ 2671833626 0;
BA_ "GenMsgSendType" BO_ 2671833626 8;
BA_ "DiagConnection" BO_ 2671781874 61991;
BA_ "DiagRequest" BO_ 2671781874 1;
BA_ "GenMsgILSupport" BO_ 2671781874 0;
BA_ "GenMsgSendType" BO_ 2671781874 8;
BA_ "DiagConnection" BO_ 2671780594 61986;
BA_ "DiagRequest" BO_ 2671780594 1;
BA_ "GenMsgILSupport" BO_ 2671780594 0;
BA_ "GenMsgSendType" BO_ 2671780594 8;
BA_ "DiagConnection" BO_ 2671780338 61985;
BA_ "DiagRequest" BO_ 2671780338 1;
BA_ "GenMsgILSupport" BO_ 2671780338 0;
BA_ "GenMsgSendType" BO_ 2671780338 8;
BA_ "DiagConnection" BO_ 2671780082 61984;
BA_ "DiagRequest" BO_ 2671780082 1;
BA_ "GenMsgILSupport" BO_ 2671780082 0;
BA_ "GenMsgSendType" BO_ 2671780082 8;
BA_ "DiagConnection" BO_ 2671778546 61978;
BA_ "DiagRequest" BO_ 2671778546 1;
BA_ "GenMsgILSupport" BO_ 2671778546 0;
BA_ "GenMsgSendType" BO_ 2671778546 8;
BA_ "GenMsgILSupport" BO_ 2633990180 0;
BA_ "NmAsrMessage" BO_ 2633990180 1;
BA_ "GenMsgSendType" BO_ 2633990180 8;
BA_ "GenMsgILSupport" BO_ 2633990183 0;
BA_ "NmAsrMessage" BO_ 2633990183 1;
BA_ "GenMsgSendType" BO_ 2633990183 8;
BA_ "GenMsgILSupport" BO_ 2633990178 0;
BA_ "NmAsrMessage" BO_ 2633990178 1;
BA_ "GenMsgSendType" BO_ 2633990178 8;
BA_ "GenMsgILSupport" BO_ 2633990177 0;
BA_ "NmAsrMessage" BO_ 2633990177 1;
BA_ "GenMsgSendType" BO_ 2633990177 8;
BA_ "GenMsgILSupport" BO_ 2633990176 0;
BA_ "NmAsrMessage" BO_ 2633990176 1;
BA_ "GenMsgCycleTime" BO_ 2633990176 100;
BA_ "GenMsgILSupport" BO_ 2633990170 0;
BA_ "NmAsrMessage" BO_ 2633990170 1;
BA_ "GenMsgSendType" BO_ 2633990170 8;
BA_ "VFrameFormat" BO_ 1339 0;
BA_ "GenMsgCycleTime" BO_ 1339 250;
BA_ "GenMsgStartDelayTime" BO_ 1339 50;
BA_ "VFrameFormat" BO_ 1243 0;
BA_ "GenMsgCycleTime" BO_ 1243 100;
BA_ "GenMsgStartDelayTime" BO_ 1243 25;
BA_ "VFrameFormat" BO_ 952 0;
BA_ "GenMsgCycleTime" BO_ 952 50;
BA_ "GenMsgStartDelayTime" BO_ 952 10;
BA_ "VFrameFormat" BO_ 1232 0;
BA_ "GenMsgCycleTime" BO_ 1232 100;
BA_ "GenMsgStartDelayTime" BO_ 1232 10;
BA_ "VFrameFormat" BO_ 396 0;
BA_ "GenMsgCycleTime" BO_ 396 100;
BA_ "GenMsgStartDelayTime" BO_ 396 10;
BA_ "VFrameFormat" BO_ 395 0;
BA_ "GenMsgCycleTime" BO_ 395 100;
BA_ "GenMsgStartDelayTime" BO_ 395 10;
BA_ "VFrameFormat" BO_ 394 0;
BA_ "GenMsgCycleTime" BO_ 394 100;
BA_ "GenMsgStartDelayTime" BO_ 394 10;
BA_ "VFrameFormat" BO_ 386 0;
BA_ "GenMsgCycleTime" BO_ 386 100;
BA_ "GenMsgStartDelayTime" BO_ 386 10;
BA_ "VFrameFormat" BO_ 824 0;
BA_ "GenMsgCycleTime" BO_ 824 100;
BA_ "GenMsgStartDelayTime" BO_ 824 10;
BA_ "VFrameFormat" BO_ 516 0;
BA_ "GenMsgCycleTime" BO_ 516 100;
BA_ "GenMsgStartDelayTime" BO_ 516 10;
BA_ "VFrameFormat" BO_ 1110 0;
BA_ "GenMsgCycleTime" BO_ 1110 100;
BA_ "GenMsgStartDelayTime" BO_ 1110 50;
BA_ "DiagConnection" BO_ 2671964711 61991;
BA_ "DiagUUDTResponse" BO_ 2671964711 1;
BA_ "GenMsgILSupport" BO_ 2671964711 0;
BA_ "GenMsgSendType" BO_ 2671964711 8;
BA_ "DiagConnection" BO_ 2671964706 61986;
BA_ "DiagUUDTResponse" BO_ 2671964706 1;
BA_ "GenMsgILSupport" BO_ 2671964706 0;
BA_ "GenMsgSendType" BO_ 2671964706 8;
BA_ "DiagConnection" BO_ 2671964705 61985;
BA_ "DiagUUDTResponse" BO_ 2671964705 1;
BA_ "GenMsgILSupport" BO_ 2671964705 0;
BA_ "GenMsgSendType" BO_ 2671964705 8;
BA_ "DiagConnection" BO_ 2671964704 61984;
BA_ "DiagUUDTResponse" BO_ 2671964704 1;
BA_ "GenMsgILSupport" BO_ 2671964704 0;
BA_ "GenMsgSendType" BO_ 2671964704 8;
BA_ "DiagConnection" BO_ 2671964698 61978;
BA_ "DiagUUDTResponse" BO_ 2671964698 1;
BA_ "GenMsgILSupport" BO_ 2671964698 0;
BA_ "GenMsgSendType" BO_ 2671964698 8;
BA_ "DiagConnection" BO_ 2671834151 62503;
BA_ "DiagResponse" BO_ 2671834151 1;
BA_ "GenMsgILSupport" BO_ 2671834151 0;
BA_ "GenMsgSendType" BO_ 2671834151 8;
BA_ "DiagConnection" BO_ 2671834146 62498;
BA_ "DiagResponse" BO_ 2671834146 1;
BA_ "GenMsgILSupport" BO_ 2671834146 0;
BA_ "GenMsgSendType" BO_ 2671834146 8;
BA_ "DiagConnection" BO_ 2671834145 62497;
BA_ "DiagResponse" BO_ 2671834145 1;
BA_ "GenMsgILSupport" BO_ 2671834145 0;
BA_ "GenMsgSendType" BO_ 2671834145 8;
BA_ "DiagConnection" BO_ 2671834144 62496;
BA_ "DiagResponse" BO_ 2671834144 1;
BA_ "GenMsgILSupport" BO_ 2671834144 0;
BA_ "GenMsgSendType" BO_ 2671834144 8;
BA_ "DiagConnection" BO_ 2671834138 62490;
BA_ "DiagResponse" BO_ 2671834138 1;
BA_ "GenMsgILSupport" BO_ 2671834138 0;
BA_ "GenMsgSendType" BO_ 2671834138 8;
BA_ "DiagConnection" BO_ 2671781876 62503;
BA_ "DiagRequest" BO_ 2671781876 1;
BA_ "GenMsgILSupport" BO_ 2671781876 0;
BA_ "GenMsgSendType" BO_ 2671781876 8;
BA_ "DiagConnection" BO_ 2671780596 62498;
BA_ "DiagRequest" BO_ 2671780596 1;
BA_ "GenMsgILSupport" BO_ 2671780596 0;
BA_ "GenMsgSendType" BO_ 2671780596 8;
BA_ "DiagConnection" BO_ 2671780340 62497;
BA_ "DiagRequest" BO_ 2671780340 1;
BA_ "GenMsgILSupport" BO_ 2671780340 0;
BA_ "GenMsgSendType" BO_ 2671780340 8;
BA_ "DiagConnection" BO_ 2671780084 62496;
BA_ "DiagRequest" BO_ 2671780084 1;
BA_ "GenMsgILSupport" BO_ 2671780084 0;
BA_ "GenMsgSendType" BO_ 2671780084 8;
BA_ "DiagConnection" BO_ 2671778548 62490;
BA_ "DiagRequest" BO_ 2671778548 1;
BA_ "GenMsgILSupport" BO_ 2671778548 0;
BA_ "GenMsgSendType" BO_ 2671778548 8;
BA_ "VFrameFormat" BO_ 1500 0;
BA_ "GenMsgCycleTime" BO_ 1500 1000;
BA_ "GenMsgDelayTime" BO_ 1500 90;
BA_ "GenMsgStartDelayTime" BO_ 1500 5;
BA_ "VFrameFormat" BO_ 1497 0;
BA_ "GenMsgSendType" BO_ 1497 8;
BA_ "GenMsgDelayTime" BO_ 1497 80;
BA_ "VFrameFormat" BO_ 1496 0;
BA_ "GenMsgSendType" BO_ 1496 8;
BA_ "GenMsgDelayTime" BO_ 1496 80;
BA_ "VFrameFormat" BO_ 1499 0;
BA_ "GenMsgCycleTime" BO_ 1499 1000;
BA_ "GenMsgDelayTime" BO_ 1499 90;
BA_ "GenMsgStartDelayTime" BO_ 1499 20;
BA_ "VFrameFormat" BO_ 1490 0;
BA_ "GenMsgCycleTime" BO_ 1490 1000;
BA_ "GenMsgDelayTime" BO_ 1490 95;
BA_ "GenMsgStartDelayTime" BO_ 1490 20;
BA_ "VFrameFormat" BO_ 1372 0;
BA_ "GenMsgCycleTime" BO_ 1372 500;
BA_ "GenMsgStartDelayTime" BO_ 1372 80;
BA_ "VFrameFormat" BO_ 1371 0;
BA_ "GenMsgCycleTime" BO_ 1371 500;
BA_ "GenMsgStartDelayTime" BO_ 1371 65;
BA_ "VFrameFormat" BO_ 1362 0;
BA_ "GenMsgCycleTime" BO_ 1362 500;
BA_ "GenMsgStartDelayTime" BO_ 1362 40;
BA_ "VFrameFormat" BO_ 1444 0;
BA_ "GenMsgCycleTime" BO_ 1444 1000;
BA_ "GenMsgStartDelayTime" BO_ 1444 50;
BA_ "VFrameFormat" BO_ 1471 0;
BA_ "GenMsgCycleTime" BO_ 1471 1000;
BA_ "GenMsgStartDelayTime" BO_ 1471 270;
BA_ "VFrameFormat" BO_ 1469 0;
BA_ "GenMsgCycleTime" BO_ 1469 1000;
BA_ "GenMsgStartDelayTime" BO_ 1469 255;
BA_ "VFrameFormat" BO_ 1467 0;
BA_ "GenMsgCycleTime" BO_ 1467 1000;
BA_ "GenMsgStartDelayTime" BO_ 1467 240;
BA_ "VFrameFormat" BO_ 1465 0;
BA_ "GenMsgCycleTime" BO_ 1465 1000;
BA_ "GenMsgStartDelayTime" BO_ 1465 225;
BA_ "VFrameFormat" BO_ 1463 0;
BA_ "GenMsgCycleTime" BO_ 1463 1000;
BA_ "GenMsgStartDelayTime" BO_ 1463 210;
BA_ "VFrameFormat" BO_ 1461 0;
BA_ "GenMsgCycleTime" BO_ 1461 1000;
BA_ "GenMsgStartDelayTime" BO_ 1461 195;
BA_ "GenSigSendType" SG_ 1343 SecondaryDriveAxleLoad_UB 7;
BA_ "Platform_VMCU1_Sig" SG_ 1343 SecondaryDriveAxleLoad_UB 1;
BA_ "Platform_Vivis2_Sig" SG_ 1343 SecondaryDriveAxleLoad_UB 1;
BA_ "GenSigCycleTime" SG_ 1343 TrailerDirIndLeftOutputStat 100;
BA_ "GenSigCycleTimeActive" SG_ 1343 TrailerDirIndLeftOutputStat 100;
BA_ "GenSigStartValue" SG_ 1343 TrailerDirIndLeftOutputStat 7;
BA_ "Platform_Vivis2_Sig" SG_ 1343 TrailerDirIndLeftOutputStat 1;
BA_ "GenSigCycleTime" SG_ 1343 TrailerBrakeLightOutputStat 100;
BA_ "GenSigCycleTimeActive" SG_ 1343 TrailerBrakeLightOutputStat 100;
BA_ "GenSigStartValue" SG_ 1343 TrailerBrakeLightOutputStat 7;
BA_ "Platform_Vivis2_Sig" SG_ 1343 TrailerBrakeLightOutputStat 1;
BA_ "GenSigCycleTime" SG_ 1343 TrailerPosLightRightOutputStat 100;
BA_ "GenSigCycleTimeActive" SG_ 1343 TrailerPosLightRightOutputStat 100;
BA_ "GenSigStartValue" SG_ 1343 TrailerPosLightRightOutputStat 7;
BA_ "Platform_Vivis2_Sig" SG_ 1343 TrailerPosLightRightOutputStat 1;
BA_ "GenSigCycleTime" SG_ 1343 TrailerPosLightLeftOutputStat 100;
BA_ "GenSigCycleTimeActive" SG_ 1343 TrailerPosLightLeftOutputStat 100;
BA_ "GenSigStartValue" SG_ 1343 TrailerPosLightLeftOutputStat 7;
BA_ "Platform_Vivis2_Sig" SG_ 1343 TrailerPosLightLeftOutputStat 1;
BA_ "GenSigCycleTime" SG_ 1343 LoadDistributionSelected2 100;
BA_ "GenSigCycleTimeActive" SG_ 1343 LoadDistributionSelected2 100;
BA_ "GenSigStartValue" SG_ 1343 LoadDistributionSelected2 15;
BA_ "Platform_Vivis2_Sig" SG_ 1343 LoadDistributionSelected2 1;
BA_ "GenSigCycleTime" SG_ 1343 DriveAxleLoad 100;
BA_ "GenSigCycleTimeActive" SG_ 1343 DriveAxleLoad 100;
BA_ "GenSigStartValue" SG_ 1343 DriveAxleLoad 65535;
BA_ "GenSigMaxLatency" SG_ 1343 DriveAxleLoad 255;
BA_ "NeedsUpdateBit" SG_ 1343 DriveAxleLoad 1;
BA_ "Platform_VMCU1_Sig" SG_ 1343 DriveAxleLoad 1;
BA_ "Platform_Vivis2_Sig" SG_ 1343 DriveAxleLoad 1;
BA_ "GenSigCycleTime" SG_ 1343 TrailerDirIndRightOutputStat 100;
BA_ "GenSigCycleTimeActive" SG_ 1343 TrailerDirIndRightOutputStat 100;
BA_ "GenSigStartValue" SG_ 1343 TrailerDirIndRightOutputStat 7;
BA_ "Platform_Vivis2_Sig" SG_ 1343 TrailerDirIndRightOutputStat 1;
BA_ "GenSigCycleTime" SG_ 1343 ExtECSPressureUpdateAck 100;
BA_ "GenSigCycleTimeActive" SG_ 1343 ExtECSPressureUpdateAck 100;
BA_ "GenSigStartValue" SG_ 1343 ExtECSPressureUpdateAck 7;
BA_ "Platform_Vivis2_Sig" SG_ 1343 ExtECSPressureUpdateAck 1;
BA_ "GenSigSendType" SG_ 1343 DriveAxleLoad_UB 7;
BA_ "Platform_VMCU1_Sig" SG_ 1343 DriveAxleLoad_UB 1;
BA_ "Platform_Vivis2_Sig" SG_ 1343 DriveAxleLoad_UB 1;
BA_ "GenSigCycleTime" SG_ 1343 SecondaryDriveAxleLoad 100;
BA_ "GenSigCycleTimeActive" SG_ 1343 SecondaryDriveAxleLoad 100;
BA_ "GenSigStartValue" SG_ 1343 SecondaryDriveAxleLoad 65535;
BA_ "GenSigMaxLatency" SG_ 1343 SecondaryDriveAxleLoad 255;
BA_ "NeedsUpdateBit" SG_ 1343 SecondaryDriveAxleLoad 1;
BA_ "Platform_VMCU1_Sig" SG_ 1343 SecondaryDriveAxleLoad 1;
BA_ "Platform_Vivis2_Sig" SG_ 1343 SecondaryDriveAxleLoad 1;
BA_ "GenSigCycleTime" SG_ 825 RevLightLamp_stat 100;
BA_ "GenSigCycleTimeActive" SG_ 825 RevLightLamp_stat 100;
BA_ "GenSigInactiveValue" SG_ 825 RevLightLamp_stat 7;
BA_ "GenSigStartValue" SG_ 825 RevLightLamp_stat 7;
BA_ "GenSigMaxLatency" SG_ 825 RevLightLamp_stat 35;
BA_ "Platform_VMCU1_Sig" SG_ 825 RevLightLamp_stat 1;
BA_ "Platform_Vivis2_Sig" SG_ 825 RevLightLamp_stat 1;
BA_ "GenSigSendType" SG_ 825 BrakeLightConvoy_rqst_UB 7;
BA_ "Platform_VMCU1_Sig" SG_ 825 BrakeLightConvoy_rqst_UB 1;
BA_ "Platform_Vivis2_Sig" SG_ 825 BrakeLightConvoy_rqst_UB 1;
BA_ "GenSigCycleTime" SG_ 825 FirstAxleLowerPrioSelected 100;
BA_ "GenSigCycleTimeActive" SG_ 825 FirstAxleLowerPrioSelected 100;
BA_ "GenSigStartValue" SG_ 825 FirstAxleLowerPrioSelected 7;
BA_ "Platform_Vivis2_Sig" SG_ 825 FirstAxleLowerPrioSelected 1;
BA_ "GenSigCycleTime" SG_ 825 FrontParkBrakeOverrideInd 100;
BA_ "GenSigCycleTimeActive" SG_ 825 FrontParkBrakeOverrideInd 100;
BA_ "GenSigStartValue" SG_ 825 FrontParkBrakeOverrideInd 3;
BA_ "Platform_Vivis2_Sig" SG_ 825 FrontParkBrakeOverrideInd 1;
BA_ "GenSigCycleTime" SG_ 825 ECSLimpHomeNotification 100;
BA_ "GenSigCycleTimeActive" SG_ 825 ECSLimpHomeNotification 100;
BA_ "GenSigStartValue" SG_ 825 ECSLimpHomeNotification 7;
BA_ "GenSigMaxLatency" SG_ 825 ECSLimpHomeNotification 35;
BA_ "Platform_VMCU1_Sig" SG_ 825 ECSLimpHomeNotification 1;
BA_ "Platform_Vivis2_Sig" SG_ 825 ECSLimpHomeNotification 1;
BA_ "GenSigCycleTime" SG_ 825 ECSValveActivationAllowed 100;
BA_ "GenSigCycleTimeActive" SG_ 825 ECSValveActivationAllowed 100;
BA_ "GenSigStartValue" SG_ 825 ECSValveActivationAllowed 3;
BA_ "GenSigMaxLatency" SG_ 825 ECSValveActivationAllowed 35;
BA_ "Platform_VMCU1_Sig" SG_ 825 ECSValveActivationAllowed 1;
BA_ "Platform_Vivis2_Sig" SG_ 825 ECSValveActivationAllowed 1;
BA_ "GenSigCycleTime" SG_ 825 UnevenLoadWarning 100;
BA_ "GenSigCycleTimeActive" SG_ 825 UnevenLoadWarning 100;
BA_ "GenSigStartValue" SG_ 825 UnevenLoadWarning 3;
BA_ "GenSigMaxLatency" SG_ 825 UnevenLoadWarning 35;
BA_ "Platform_VMCU1_Sig" SG_ 825 UnevenLoadWarning 1;
BA_ "Platform_Vivis2_Sig" SG_ 825 UnevenLoadWarning 1;
BA_ "GenSigCycleTime" SG_ 825 RampLevelRequestACK 100;
BA_ "GenSigCycleTimeActive" SG_ 825 RampLevelRequestACK 100;
BA_ "GenSigStartValue" SG_ 825 RampLevelRequestACK 3;
BA_ "Platform_VMCU1_Sig" SG_ 825 RampLevelRequestACK 1;
BA_ "Platform_Vivis2_Sig" SG_ 825 RampLevelRequestACK 1;
BA_ "GenSigCycleTime" SG_ 825 LoadDistributionSelected 100;
BA_ "GenSigCycleTimeActive" SG_ 825 LoadDistributionSelected 100;
BA_ "GenSigStartValue" SG_ 825 LoadDistributionSelected 15;
BA_ "GenSigMaxLatency" SG_ 825 LoadDistributionSelected 35;
BA_ "Platform_VMCU1_Sig" SG_ 825 LoadDistributionSelected 1;
BA_ "Platform_Vivis2_Sig" SG_ 825 LoadDistributionSelected 1;
BA_ "GenSigCycleTime" SG_ 825 TrailerABSStatus 100;
BA_ "GenSigCycleTimeActive" SG_ 825 TrailerABSStatus 100;
BA_ "GenSigStartValue" SG_ 825 TrailerABSStatus 3;
BA_ "GenSigMaxLatency" SG_ 825 TrailerABSStatus 35;
BA_ "Platform_VMCU1_Sig" SG_ 825 TrailerABSStatus 1;
BA_ "Platform_Vivis2_Sig" SG_ 825 TrailerABSStatus 1;
BA_ "GenSigCycleTime" SG_ 825 RevLight_cmd 100;
BA_ "GenSigCycleTimeActive" SG_ 825 RevLight_cmd 100;
BA_ "GenSigStartValue" SG_ 825 RevLight_cmd 3;
BA_ "GenSigMaxLatency" SG_ 825 RevLight_cmd 35;
BA_ "Platform_VMCU1_Sig" SG_ 825 RevLight_cmd 1;
BA_ "Platform_Vivis2_Sig" SG_ 825 RevLight_cmd 1;
BA_ "GenSigCycleTime" SG_ 825 LoadDistributionALDChangeACK 100;
BA_ "GenSigCycleTimeActive" SG_ 825 LoadDistributionALDChangeACK 100;
BA_ "GenSigStartValue" SG_ 825 LoadDistributionALDChangeACK 7;
BA_ "GenSigMaxLatency" SG_ 825 LoadDistributionALDChangeACK 35;
BA_ "Platform_VMCU1_Sig" SG_ 825 LoadDistributionALDChangeACK 1;
BA_ "Platform_Vivis2_Sig" SG_ 825 LoadDistributionALDChangeACK 1;
BA_ "GenSigCycleTime" SG_ 825 FogLightRearLamp_stat 100;
BA_ "GenSigCycleTimeActive" SG_ 825 FogLightRearLamp_stat 100;
BA_ "GenSigInactiveValue" SG_ 825 FogLightRearLamp_stat 7;
BA_ "GenSigStartValue" SG_ 825 FogLightRearLamp_stat 7;
BA_ "GenSigMaxLatency" SG_ 825 FogLightRearLamp_stat 35;
BA_ "Platform_VMCU1_Sig" SG_ 825 FogLightRearLamp_stat 1;
BA_ "Platform_Vivis2_Sig" SG_ 825 FogLightRearLamp_stat 1;
BA_ "GenSigCycleTime" SG_ 825 PositionLightRearLamp_stat 100;
BA_ "GenSigCycleTimeActive" SG_ 825 PositionLightRearLamp_stat 100;
BA_ "GenSigInactiveValue" SG_ 825 PositionLightRearLamp_stat 7;
BA_ "GenSigStartValue" SG_ 825 PositionLightRearLamp_stat 7;
BA_ "GenSigMaxLatency" SG_ 825 PositionLightRearLamp_stat 35;
BA_ "Platform_VMCU1_Sig" SG_ 825 PositionLightRearLamp_stat 1;
BA_ "Platform_Vivis2_Sig" SG_ 825 PositionLightRearLamp_stat 1;
BA_ "GenSigCycleTime" SG_ 825 FerryFunctionSwitchChangeACK 100;
BA_ "GenSigCycleTimeActive" SG_ 825 FerryFunctionSwitchChangeACK 100;
BA_ "GenSigStartValue" SG_ 825 FerryFunctionSwitchChangeACK 3;
BA_ "Platform_VMCU1_Sig" SG_ 825 FerryFunctionSwitchChangeACK 1;
BA_ "Platform_Vivis2_Sig" SG_ 825 FerryFunctionSwitchChangeACK 1;
BA_ "GenSigCycleTime" SG_ 825 BrakeLight_rqst 100;
BA_ "GenSigCycleTimeActive" SG_ 825 BrakeLight_rqst 100;
BA_ "GenSigStartValue" SG_ 825 BrakeLight_rqst 7;
BA_ "GenSigMaxLatency" SG_ 825 BrakeLight_rqst 35;
BA_ "NeedsUpdateBit" SG_ 825 BrakeLight_rqst 1;
BA_ "Platform_VMCU1_Sig" SG_ 825 BrakeLight_rqst 1;
BA_ "Platform_Vivis2_Sig" SG_ 825 BrakeLight_rqst 1;
BA_ "GenSigSendType" SG_ 825 BrakeLight_rqst_UB 7;
BA_ "Platform_VMCU1_Sig" SG_ 825 BrakeLight_rqst_UB 1;
BA_ "Platform_Vivis2_Sig" SG_ 825 BrakeLight_rqst_UB 1;
BA_ "GenSigCycleTime" SG_ 825 BrakeLightConvoy_rqst 100;
BA_ "GenSigCycleTimeActive" SG_ 825 BrakeLightConvoy_rqst 100;
BA_ "GenSigStartValue" SG_ 825 BrakeLightConvoy_rqst 3;
BA_ "GenSigMaxLatency" SG_ 825 BrakeLightConvoy_rqst 35;
BA_ "NeedsUpdateBit" SG_ 825 BrakeLightConvoy_rqst 1;
BA_ "Platform_VMCU1_Sig" SG_ 825 BrakeLightConvoy_rqst 1;
BA_ "Platform_Vivis2_Sig" SG_ 825 BrakeLightConvoy_rqst 1;
BA_ "GenSigCycleTime" SG_ 825 LiftAxle1AutoLiftSelected 100;
BA_ "GenSigCycleTimeActive" SG_ 825 LiftAxle1AutoLiftSelected 100;
BA_ "GenSigStartValue" SG_ 825 LiftAxle1AutoLiftSelected 3;
BA_ "Platform_Vivis2_Sig" SG_ 825 LiftAxle1AutoLiftSelected 1;
BA_ "GenSigCycleTime" SG_ 825 BrakeLightLamp_stat 100;
BA_ "GenSigCycleTimeActive" SG_ 825 BrakeLightLamp_stat 100;
BA_ "GenSigInactiveValue" SG_ 825 BrakeLightLamp_stat 7;
BA_ "GenSigStartValue" SG_ 825 BrakeLightLamp_stat 7;
BA_ "GenSigMaxLatency" SG_ 825 BrakeLightLamp_stat 35;
BA_ "Platform_VMCU1_Sig" SG_ 825 BrakeLightLamp_stat 1;
BA_ "Platform_Vivis2_Sig" SG_ 825 BrakeLightLamp_stat 1;
BA_ "GenSigCycleTime" SG_ 825 LiftAxle2AutoLiftSelected 100;
BA_ "GenSigCycleTimeActive" SG_ 825 LiftAxle2AutoLiftSelected 100;
BA_ "GenSigStartValue" SG_ 825 LiftAxle2AutoLiftSelected 3;
BA_ "Platform_Vivis2_Sig" SG_ 825 LiftAxle2AutoLiftSelected 1;
BA_ "GenSigCycleTime" SG_ 825 StartupProhibitStatus 100;
BA_ "GenSigCycleTimeActive" SG_ 825 StartupProhibitStatus 100;
BA_ "GenSigStartValue" SG_ 825 StartupProhibitStatus 3;
BA_ "Platform_VMCU1_Sig" SG_ 825 StartupProhibitStatus 1;
BA_ "Platform_Vivis2_Sig" SG_ 825 StartupProhibitStatus 1;
BA_ "GenSigCycleTime" SG_ 825 LiftAxle1LowerACK 100;
BA_ "GenSigCycleTimeActive" SG_ 825 LiftAxle1LowerACK 100;
BA_ "GenSigStartValue" SG_ 825 LiftAxle1LowerACK 7;
BA_ "Platform_Vivis2_Sig" SG_ 825 LiftAxle1LowerACK 1;
BA_ "GenSigCycleTime" SG_ 825 TrailerDirInd_status 100;
BA_ "GenSigCycleTimeActive" SG_ 825 TrailerDirInd_status 100;
BA_ "GenSigStartValue" SG_ 825 TrailerDirInd_status 7;
BA_ "GenSigMaxLatency" SG_ 825 TrailerDirInd_status 23;
BA_ "Platform_VMCU1_Sig" SG_ 825 TrailerDirInd_status 1;
BA_ "Platform_Vivis2_Sig" SG_ 825 TrailerDirInd_status 1;
BA_ "GenSigCycleTime" SG_ 825 DriveLevelPosUserInteraction 100;
BA_ "GenSigCycleTimeActive" SG_ 825 DriveLevelPosUserInteraction 100;
BA_ "GenSigStartValue" SG_ 825 DriveLevelPosUserInteraction 7;
BA_ "Platform_VMCU1_Sig" SG_ 825 DriveLevelPosUserInteraction 1;
BA_ "Platform_Vivis2_Sig" SG_ 825 DriveLevelPosUserInteraction 1;
BA_ "GenSigCycleTime" SG_ 948 FrontEndPositionStatus 100;
BA_ "GenSigCycleTimeActive" SG_ 948 FrontEndPositionStatus 100;
BA_ "GenSigInactiveValue" SG_ 948 FrontEndPositionStatus 7;
BA_ "GenSigStartValue" SG_ 948 FrontEndPositionStatus 7;
BA_ "GenSigMaxLatency" SG_ 948 FrontEndPositionStatus 35;
BA_ "Platform_VMCU1_Sig" SG_ 948 FrontEndPositionStatus 1;
BA_ "Platform_Vivis2_Sig" SG_ 948 FrontEndPositionStatus 1;
BA_ "GenSigCycleTime" SG_ 948 DirIndRearLamp_Stat 100;
BA_ "GenSigCycleTimeActive" SG_ 948 DirIndRearLamp_Stat 100;
BA_ "GenSigStartValue" SG_ 948 DirIndRearLamp_Stat 7;
BA_ "Platform_VMCU1_Sig" SG_ 948 DirIndRearLamp_Stat 1;
BA_ "Platform_Vivis2_Sig" SG_ 948 DirIndRearLamp_Stat 1;
BA_ "GenSigCycleTime" SG_ 948 FrontAxleInBumperRange 100;
BA_ "GenSigCycleTimeActive" SG_ 948 FrontAxleInBumperRange 100;
BA_ "GenSigStartValue" SG_ 948 FrontAxleInBumperRange 3;
BA_ "GenSigMaxLatency" SG_ 948 FrontAxleInBumperRange 27;
BA_ "NeedsUpdateBit" SG_ 948 FrontAxleInBumperRange 1;
BA_ "Platform_VMCU1_Sig" SG_ 948 FrontAxleInBumperRange 1;
BA_ "Platform_Vivis2_Sig" SG_ 948 FrontAxleInBumperRange 1;
BA_ "GenSigSendType" SG_ 948 FrontAxleInBumperRange_UB 7;
BA_ "Platform_VMCU1_Sig" SG_ 948 FrontAxleInBumperRange_UB 1;
BA_ "Platform_Vivis2_Sig" SG_ 948 FrontAxleInBumperRange_UB 1;
BA_ "GenSigCycleTime" SG_ 948 FrontRollAngleRef 100;
BA_ "GenSigCycleTimeActive" SG_ 948 FrontRollAngleRef 100;
BA_ "GenSigStartValue" SG_ 948 FrontRollAngleRef 65535;
BA_ "GenSigMaxLatency" SG_ 948 FrontRollAngleRef 57;
BA_ "Platform_VMCU1_Sig" SG_ 948 FrontRollAngleRef 1;
BA_ "Platform_Vivis2_Sig" SG_ 948 FrontRollAngleRef 1;
BA_ "GenSigCycleTime" SG_ 948 FrontSideKneelingAngleRef 100;
BA_ "GenSigCycleTimeActive" SG_ 948 FrontSideKneelingAngleRef 100;
BA_ "GenSigStartValue" SG_ 948 FrontSideKneelingAngleRef 65535;
BA_ "Platform_VMCU1_Sig" SG_ 948 FrontSideKneelingAngleRef 1;
BA_ "Platform_Vivis2_Sig" SG_ 948 FrontSideKneelingAngleRef 1;
BA_ "GenSigCycleTime" SG_ 948 LoadDistributionRequestedACK 100;
BA_ "GenSigCycleTimeActive" SG_ 948 LoadDistributionRequestedACK 100;
BA_ "GenSigStartValue" SG_ 948 LoadDistributionRequestedACK 7;
BA_ "Platform_VMCU1_Sig" SG_ 948 LoadDistributionRequestedACK 1;
BA_ "Platform_Vivis2_Sig" SG_ 948 LoadDistributionRequestedACK 1;
BA_ "GenSigCycleTime" SG_ 948 TotalFrontBellowTorqueRef 100;
BA_ "GenSigCycleTimeActive" SG_ 948 TotalFrontBellowTorqueRef 100;
BA_ "GenSigStartValue" SG_ 948 TotalFrontBellowTorqueRef 65535;
BA_ "GenSigMaxLatency" SG_ 948 TotalFrontBellowTorqueRef 57;
BA_ "Platform_VMCU1_Sig" SG_ 948 TotalFrontBellowTorqueRef 1;
BA_ "Platform_Vivis2_Sig" SG_ 948 TotalFrontBellowTorqueRef 1;
BA_ "GenSigCycleTime" SG_ 948 Rear1ClutchStatus 100;
BA_ "GenSigCycleTimeActive" SG_ 948 Rear1ClutchStatus 100;
BA_ "GenSigStartValue" SG_ 948 Rear1ClutchStatus 3;
BA_ "Platform_VMCU1_Sig" SG_ 948 Rear1ClutchStatus 1;
BA_ "Platform_Vivis2_Sig" SG_ 948 Rear1ClutchStatus 1;
BA_ "GenSigCycleTime" SG_ 947 FPBRMMIStat_FPBRChangeAck 100;
BA_ "GenSigCycleTimeActive" SG_ 947 FPBRMMIStat_FPBRChangeAck 100;
BA_ "GenSigStartValue" SG_ 947 FPBRMMIStat_FPBRChangeAck 3;
BA_ "Platform_VMCU1_Sig" SG_ 947 FPBRMMIStat_FPBRChangeAck 1;
BA_ "Platform_Vivis2_Sig" SG_ 947 FPBRMMIStat_FPBRChangeAck 1;
BA_ "GenSigCycleTime" SG_ 947 RelativeLevelRearAxleRight 100;
BA_ "GenSigCycleTimeActive" SG_ 947 RelativeLevelRearAxleRight 100;
BA_ "GenSigStartValue" SG_ 947 RelativeLevelRearAxleRight 65535;
BA_ "GenSigMaxLatency" SG_ 947 RelativeLevelRearAxleRight 56;
BA_ "Platform_VMCU1_Sig" SG_ 947 RelativeLevelRearAxleRight 1;
BA_ "Platform_Vivis2_Sig" SG_ 947 RelativeLevelRearAxleRight 1;
BA_ "GenSigCycleTime" SG_ 947 FPBRMMIStat_FPBRStatusInd 100;
BA_ "GenSigCycleTimeActive" SG_ 947 FPBRMMIStat_FPBRStatusInd 100;
BA_ "GenSigStartValue" SG_ 947 FPBRMMIStat_FPBRStatusInd 3;
BA_ "Platform_VMCU1_Sig" SG_ 947 FPBRMMIStat_FPBRStatusInd 1;
BA_ "Platform_Vivis2_Sig" SG_ 947 FPBRMMIStat_FPBRStatusInd 1;
BA_ "GenSigCycleTime" SG_ 947 LiftAxle1LiftAllowed_Stat 100;
BA_ "GenSigCycleTimeActive" SG_ 947 LiftAxle1LiftAllowed_Stat 100;
BA_ "GenSigStartValue" SG_ 947 LiftAxle1LiftAllowed_Stat 7;
BA_ "Platform_VMCU1_Sig" SG_ 947 LiftAxle1LiftAllowed_Stat 1;
BA_ "Platform_Vivis2_Sig" SG_ 947 LiftAxle1LiftAllowed_Stat 1;
BA_ "GenSigCycleTime" SG_ 947 FrontLevRefCtrl_ShortPushCnt 100;
BA_ "GenSigCycleTimeActive" SG_ 947 FrontLevRefCtrl_ShortPushCnt 100;
BA_ "GenSigStartValue" SG_ 947 FrontLevRefCtrl_ShortPushCnt 255;
BA_ "Platform_VMCU1_Sig" SG_ 947 FrontLevRefCtrl_ShortPushCnt 1;
BA_ "Platform_Vivis2_Sig" SG_ 947 FrontLevRefCtrl_ShortPushCnt 1;
BA_ "GenSigCycleTime" SG_ 947 FrontLevRefCtrl_LevelRef 100;
BA_ "GenSigCycleTimeActive" SG_ 947 FrontLevRefCtrl_LevelRef 100;
BA_ "GenSigStartValue" SG_ 947 FrontLevRefCtrl_LevelRef 65535;
BA_ "Platform_VMCU1_Sig" SG_ 947 FrontLevRefCtrl_LevelRef 1;
BA_ "Platform_Vivis2_Sig" SG_ 947 FrontLevRefCtrl_LevelRef 1;
BA_ "GenSigCycleTime" SG_ 947 RelativeLevelRearAxleLeft 100;
BA_ "GenSigCycleTimeActive" SG_ 947 RelativeLevelRearAxleLeft 100;
BA_ "GenSigStartValue" SG_ 947 RelativeLevelRearAxleLeft 65535;
BA_ "GenSigMaxLatency" SG_ 947 RelativeLevelRearAxleLeft 56;
BA_ "Platform_VMCU1_Sig" SG_ 947 RelativeLevelRearAxleLeft 1;
BA_ "Platform_Vivis2_Sig" SG_ 947 RelativeLevelRearAxleLeft 1;
BA_ "GenSigCycleTime" SG_ 530 AirDumpStatus 100;
BA_ "GenSigCycleTimeActive" SG_ 530 AirDumpStatus 100;
BA_ "GenSigStartValue" SG_ 530 AirDumpStatus 7;
BA_ "Platform_Vivis2_Sig" SG_ 530 AirDumpStatus 1;
BA_ "GenSigCycleTime" SG_ 530 RearAxle2DiffLock_stat 100;
BA_ "GenSigCycleTimeActive" SG_ 530 RearAxle2DiffLock_stat 100;
BA_ "GenSigStartValue" SG_ 530 RearAxle2DiffLock_stat 3;
BA_ "GenSigMaxLatency" SG_ 530 RearAxle2DiffLock_stat 23;
BA_ "NeedsUpdateBit" SG_ 530 RearAxle2DiffLock_stat 1;
BA_ "Platform_VMCU1_Sig" SG_ 530 RearAxle2DiffLock_stat 1;
BA_ "Platform_Vivis2_Sig" SG_ 530 RearAxle2DiffLock_stat 1;
BA_ "GenSigSendType" SG_ 530 SWBrakeSwitch_UB 7;
BA_ "Platform_VMCU1_Sig" SG_ 530 SWBrakeSwitch_UB 1;
BA_ "Platform_Vivis2_Sig" SG_ 530 SWBrakeSwitch_UB 1;
BA_ "GenSigCycleTime" SG_ 530 SWBrakeSwitch 100;
BA_ "GenSigCycleTimeActive" SG_ 530 SWBrakeSwitch 100;
BA_ "GenSigStartValue" SG_ 530 SWBrakeSwitch 3;
BA_ "GenSigMaxLatency" SG_ 530 SWBrakeSwitch 23;
BA_ "NeedsUpdateBit" SG_ 530 SWBrakeSwitch 1;
BA_ "Platform_VMCU1_Sig" SG_ 530 SWBrakeSwitch 1;
BA_ "Platform_Vivis2_Sig" SG_ 530 SWBrakeSwitch 1;
BA_ "GenSigCycleTime" SG_ 530 RearAxle1DiffLock_stat 100;
BA_ "GenSigCycleTimeActive" SG_ 530 RearAxle1DiffLock_stat 100;
BA_ "GenSigStartValue" SG_ 530 RearAxle1DiffLock_stat 3;
BA_ "GenSigMaxLatency" SG_ 530 RearAxle1DiffLock_stat 23;
BA_ "NeedsUpdateBit" SG_ 530 RearAxle1DiffLock_stat 1;
BA_ "Platform_VMCU1_Sig" SG_ 530 RearAxle1DiffLock_stat 1;
BA_ "Platform_Vivis2_Sig" SG_ 530 RearAxle1DiffLock_stat 1;
BA_ "GenSigCycleTime" SG_ 530 SupplyPressure 100;
BA_ "GenSigCycleTimeActive" SG_ 530 SupplyPressure 100;
BA_ "GenSigStartValue" SG_ 530 SupplyPressure 255;
BA_ "GenSigMaxLatency" SG_ 530 SupplyPressure 55;
BA_ "Platform_VMCU1_Sig" SG_ 530 SupplyPressure 1;
BA_ "Platform_Vivis2_Sig" SG_ 530 SupplyPressure 1;
BA_ "GenSigSendType" SG_ 530 RearAxle2DiffLock_stat_UB 7;
BA_ "Platform_VMCU1_Sig" SG_ 530 RearAxle2DiffLock_stat_UB 1;
BA_ "Platform_Vivis2_Sig" SG_ 530 RearAxle2DiffLock_stat_UB 1;
BA_ "GenSigCycleTime" SG_ 530 BackToDriveReqACK 100;
BA_ "GenSigCycleTimeActive" SG_ 530 BackToDriveReqACK 100;
BA_ "GenSigStartValue" SG_ 530 BackToDriveReqACK 3;
BA_ "Platform_VMCU1_Sig" SG_ 530 BackToDriveReqACK 1;
BA_ "Platform_Vivis2_Sig" SG_ 530 BackToDriveReqACK 1;
BA_ "GenSigCycleTime" SG_ 530 PitchAngleRef 100;
BA_ "GenSigCycleTimeActive" SG_ 530 PitchAngleRef 100;
BA_ "GenSigStartValue" SG_ 530 PitchAngleRef 65535;
BA_ "GenSigMaxLatency" SG_ 530 PitchAngleRef 55;
BA_ "Platform_VMCU1_Sig" SG_ 530 PitchAngleRef 1;
BA_ "Platform_Vivis2_Sig" SG_ 530 PitchAngleRef 1;
BA_ "GenSigSendType" SG_ 530 TrailerConnected_UB 7;
BA_ "Platform_VMCU1_Sig" SG_ 530 TrailerConnected_UB 1;
BA_ "Platform_Vivis2_Sig" SG_ 530 TrailerConnected_UB 1;
BA_ "GenSigSendType" SG_ 530 CentralRearDiffLock_stat_UB 7;
BA_ "Platform_VMCU1_Sig" SG_ 530 CentralRearDiffLock_stat_UB 1;
BA_ "Platform_Vivis2_Sig" SG_ 530 CentralRearDiffLock_stat_UB 1;
BA_ "GenSigCycleTime" SG_ 530 PitchAngle 100;
BA_ "GenSigCycleTimeActive" SG_ 530 PitchAngle 100;
BA_ "GenSigStartValue" SG_ 530 PitchAngle 65535;
BA_ "GenSigMaxLatency" SG_ 530 PitchAngle 55;
BA_ "Platform_VMCU1_Sig" SG_ 530 PitchAngle 1;
BA_ "Platform_Vivis2_Sig" SG_ 530 PitchAngle 1;
BA_ "GenSigCycleTime" SG_ 530 TrailerWithoutABS 100;
BA_ "GenSigCycleTimeActive" SG_ 530 TrailerWithoutABS 100;
BA_ "GenSigStartValue" SG_ 530 TrailerWithoutABS 3;
BA_ "GenSigMaxLatency" SG_ 530 TrailerWithoutABS 35;
BA_ "NeedsUpdateBit" SG_ 530 TrailerWithoutABS 1;
BA_ "Platform_VMCU1_Sig" SG_ 530 TrailerWithoutABS 1;
BA_ "Platform_Vivis2_Sig" SG_ 530 TrailerWithoutABS 1;
BA_ "GenSigSendType" SG_ 530 TrailerWithoutABS_UB 7;
BA_ "Platform_VMCU1_Sig" SG_ 530 TrailerWithoutABS_UB 1;
BA_ "Platform_Vivis2_Sig" SG_ 530 TrailerWithoutABS_UB 1;
BA_ "GenSigCycleTime" SG_ 530 TrailerConnected 100;
BA_ "GenSigCycleTimeActive" SG_ 530 TrailerConnected 100;
BA_ "GenSigStartValue" SG_ 530 TrailerConnected 3;
BA_ "GenSigMaxLatency" SG_ 530 TrailerConnected 35;
BA_ "NeedsUpdateBit" SG_ 530 TrailerConnected 1;
BA_ "Platform_VMCU1_Sig" SG_ 530 TrailerConnected 1;
BA_ "Platform_Vivis2_Sig" SG_ 530 TrailerConnected 1;
BA_ "GenSigCycleTime" SG_ 530 CentralRearDiffLock_stat 100;
BA_ "GenSigCycleTimeActive" SG_ 530 CentralRearDiffLock_stat 100;
BA_ "GenSigStartValue" SG_ 530 CentralRearDiffLock_stat 3;
BA_ "GenSigMaxLatency" SG_ 530 CentralRearDiffLock_stat 23;
BA_ "NeedsUpdateBit" SG_ 530 CentralRearDiffLock_stat 1;
BA_ "Platform_VMCU1_Sig" SG_ 530 CentralRearDiffLock_stat 1;
BA_ "Platform_Vivis2_Sig" SG_ 530 CentralRearDiffLock_stat 1;
BA_ "GenSigSendType" SG_ 530 RearAxle1DiffLock_stat_UB 7;
BA_ "Platform_VMCU1_Sig" SG_ 530 RearAxle1DiffLock_stat_UB 1;
BA_ "Platform_Vivis2_Sig" SG_ 530 RearAxle1DiffLock_stat_UB 1;
BA_ "GenSigCycleTime" SG_ 528 RollEndPositionStatus 100;
BA_ "GenSigCycleTimeActive" SG_ 528 RollEndPositionStatus 100;
BA_ "GenSigInactiveValue" SG_ 528 RollEndPositionStatus 7;
BA_ "GenSigStartValue" SG_ 528 RollEndPositionStatus 7;
BA_ "Platform_VMCU1_Sig" SG_ 528 RollEndPositionStatus 1;
BA_ "Platform_Vivis2_Sig" SG_ 528 RollEndPositionStatus 1;
BA_ "GenSigCycleTime" SG_ 528 FrontFerryFunctionCmd 100;
BA_ "GenSigCycleTimeActive" SG_ 528 FrontFerryFunctionCmd 100;
BA_ "GenSigStartValue" SG_ 528 FrontFerryFunctionCmd 7;
BA_ "GenSigMaxLatency" SG_ 528 FrontFerryFunctionCmd 23;
BA_ "Platform_VMCU1_Sig" SG_ 528 FrontFerryFunctionCmd 1;
BA_ "Platform_Vivis2_Sig" SG_ 528 FrontFerryFunctionCmd 1;
BA_ "GenSigCycleTime" SG_ 528 RideHeightFunctionStatus 100;
BA_ "GenSigCycleTimeActive" SG_ 528 RideHeightFunctionStatus 100;
BA_ "GenSigStartValue" SG_ 528 RideHeightFunctionStatus 15;
BA_ "GenSigMaxLatency" SG_ 528 RideHeightFunctionStatus 23;
BA_ "Platform_VMCU1_Sig" SG_ 528 RideHeightFunctionStatus 1;
BA_ "Platform_Vivis2_Sig" SG_ 528 RideHeightFunctionStatus 1;
BA_ "GenSigCycleTime" SG_ 528 HeightControlMode 100;
BA_ "GenSigCycleTimeActive" SG_ 528 HeightControlMode 100;
BA_ "GenSigStartValue" SG_ 528 HeightControlMode 15;
BA_ "GenSigMaxLatency" SG_ 528 HeightControlMode 23;
BA_ "Platform_VMCU1_Sig" SG_ 528 HeightControlMode 1;
BA_ "Platform_Vivis2_Sig" SG_ 528 HeightControlMode 1;
BA_ "GenSigCycleTime" SG_ 528 ECSShutdownCmd 100;
BA_ "GenSigCycleTimeActive" SG_ 528 ECSShutdownCmd 100;
BA_ "GenSigStartValue" SG_ 528 ECSShutdownCmd 3;
BA_ "Platform_VMCU1_Sig" SG_ 528 ECSShutdownCmd 1;
BA_ "Platform_Vivis2_Sig" SG_ 528 ECSShutdownCmd 1;
BA_ "GenSigCycleTime" SG_ 528 FerryFunctionStatus 100;
BA_ "GenSigCycleTimeActive" SG_ 528 FerryFunctionStatus 100;
BA_ "GenSigStartValue" SG_ 528 FerryFunctionStatus 7;
BA_ "GenSigMaxLatency" SG_ 528 FerryFunctionStatus 35;
BA_ "Platform_VMCU1_Sig" SG_ 528 FerryFunctionStatus 1;
BA_ "Platform_Vivis2_Sig" SG_ 528 FerryFunctionStatus 1;
BA_ "GenSigCycleTime" SG_ 528 LevelControlInformation 100;
BA_ "GenSigCycleTimeActive" SG_ 528 LevelControlInformation 100;
BA_ "GenSigStartValue" SG_ 528 LevelControlInformation 15;
BA_ "GenSigMaxLatency" SG_ 528 LevelControlInformation 23;
BA_ "NeedsUpdateBit" SG_ 528 LevelControlInformation 1;
BA_ "Platform_VMCU1_Sig" SG_ 528 LevelControlInformation 1;
BA_ "Platform_Vivis2_Sig" SG_ 528 LevelControlInformation 1;
BA_ "GenSigCycleTime" SG_ 528 ChangeKneelACK 100;
BA_ "GenSigCycleTimeActive" SG_ 528 ChangeKneelACK 100;
BA_ "GenSigStartValue" SG_ 528 ChangeKneelACK 3;
BA_ "Platform_VMCU1_Sig" SG_ 528 ChangeKneelACK 1;
BA_ "Platform_Vivis2_Sig" SG_ 528 ChangeKneelACK 1;
BA_ "GenSigCycleTime" SG_ 528 RearEndPositionStatus 100;
BA_ "GenSigCycleTimeActive" SG_ 528 RearEndPositionStatus 100;
BA_ "GenSigInactiveValue" SG_ 528 RearEndPositionStatus 7;
BA_ "GenSigStartValue" SG_ 528 RearEndPositionStatus 7;
BA_ "Platform_VMCU1_Sig" SG_ 528 RearEndPositionStatus 1;
BA_ "Platform_Vivis2_Sig" SG_ 528 RearEndPositionStatus 1;
BA_ "GenSigCycleTime" SG_ 528 RampHeightOutsideTargetRange 100;
BA_ "GenSigCycleTimeActive" SG_ 528 RampHeightOutsideTargetRange 100;
BA_ "GenSigInactiveValue" SG_ 528 RampHeightOutsideTargetRange 7;
BA_ "GenSigStartValue" SG_ 528 RampHeightOutsideTargetRange 7;
BA_ "Platform_VMCU1_Sig" SG_ 528 RampHeightOutsideTargetRange 1;
BA_ "Platform_Vivis2_Sig" SG_ 528 RampHeightOutsideTargetRange 1;
BA_ "GenSigCycleTime" SG_ 528 LoadDistributionFuncSelected 100;
BA_ "GenSigCycleTimeActive" SG_ 528 LoadDistributionFuncSelected 100;
BA_ "GenSigStartValue" SG_ 528 LoadDistributionFuncSelected 15;
BA_ "GenSigMaxLatency" SG_ 528 LoadDistributionFuncSelected 23;
BA_ "Platform_VMCU1_Sig" SG_ 528 LoadDistributionFuncSelected 1;
BA_ "Platform_Vivis2_Sig" SG_ 528 LoadDistributionFuncSelected 1;
BA_ "GenSigCycleTime" SG_ 528 HeightAdjustmentAllowed 100;
BA_ "GenSigCycleTimeActive" SG_ 528 HeightAdjustmentAllowed 100;
BA_ "GenSigStartValue" SG_ 528 HeightAdjustmentAllowed 3;
BA_ "Platform_VMCU1_Sig" SG_ 528 HeightAdjustmentAllowed 1;
BA_ "Platform_Vivis2_Sig" SG_ 528 HeightAdjustmentAllowed 1;
BA_ "GenSigSendType" SG_ 528 LevelControlInformation_UB 7;
BA_ "Platform_VMCU1_Sig" SG_ 528 LevelControlInformation_UB 1;
BA_ "Platform_Vivis2_Sig" SG_ 528 LevelControlInformation_UB 1;
BA_ "GenSigCycleTime" SG_ 528 KneelingInformation 100;
BA_ "GenSigCycleTimeActive" SG_ 528 KneelingInformation 100;
BA_ "GenSigStartValue" SG_ 528 KneelingInformation 15;
BA_ "Platform_VMCU1_Sig" SG_ 528 KneelingInformation 1;
BA_ "Platform_Vivis2_Sig" SG_ 528 KneelingInformation 1;
BA_ "GenSigCycleTime" SG_ 528 KneelingStatusHMI 100;
BA_ "GenSigCycleTimeActive" SG_ 528 KneelingStatusHMI 100;
BA_ "GenSigStartValue" SG_ 528 KneelingStatusHMI 3;
BA_ "Platform_VMCU1_Sig" SG_ 528 KneelingStatusHMI 1;
BA_ "Platform_Vivis2_Sig" SG_ 528 KneelingStatusHMI 1;
BA_ "GenSigCycleTime" SG_ 528 LiftAxle1PositionStatus 100;
BA_ "GenSigCycleTimeActive" SG_ 528 LiftAxle1PositionStatus 100;
BA_ "GenSigStartValue" SG_ 528 LiftAxle1PositionStatus 7;
BA_ "GenSigMaxLatency" SG_ 528 LiftAxle1PositionStatus 23;
BA_ "Platform_VMCU1_Sig" SG_ 528 LiftAxle1PositionStatus 1;
BA_ "Platform_Vivis2_Sig" SG_ 528 LiftAxle1PositionStatus 1;
BA_ "GenSigCycleTime" SG_ 528 VehicleDynamicSuspProhibitStat 100;
BA_ "GenSigCycleTimeActive" SG_ 528 VehicleDynamicSuspProhibitStat 100;
BA_ "GenSigStartValue" SG_ 528 VehicleDynamicSuspProhibitStat 3;
BA_ "Platform_VMCU1_Sig" SG_ 528 VehicleDynamicSuspProhibitStat 1;
BA_ "Platform_Vivis2_Sig" SG_ 528 VehicleDynamicSuspProhibitStat 1;
BA_ "GenSigCycleTime" SG_ 528 LiftAxle2PositionStatus 100;
BA_ "GenSigCycleTimeActive" SG_ 528 LiftAxle2PositionStatus 100;
BA_ "GenSigStartValue" SG_ 528 LiftAxle2PositionStatus 7;
BA_ "GenSigMaxLatency" SG_ 528 LiftAxle2PositionStatus 23;
BA_ "Platform_VMCU1_Sig" SG_ 528 LiftAxle2PositionStatus 1;
BA_ "Platform_Vivis2_Sig" SG_ 528 LiftAxle2PositionStatus 1;
BA_ "GenSigCycleTime" SG_ 528 RideHeightStatus 100;
BA_ "GenSigCycleTimeActive" SG_ 528 RideHeightStatus 100;
BA_ "GenSigStartValue" SG_ 528 RideHeightStatus 15;
BA_ "GenSigMaxLatency" SG_ 528 RideHeightStatus 23;
BA_ "Platform_VMCU1_Sig" SG_ 528 RideHeightStatus 1;
BA_ "Platform_Vivis2_Sig" SG_ 528 RideHeightStatus 1;
BA_ "GenSigCycleTime" SG_ 528 DirInd_Rear_Status 100;
BA_ "GenSigCycleTimeActive" SG_ 528 DirInd_Rear_Status 100;
BA_ "GenSigStartValue" SG_ 528 DirInd_Rear_Status 7;
BA_ "GenSigMaxLatency" SG_ 528 DirInd_Rear_Status 23;
BA_ "Platform_VMCU1_Sig" SG_ 528 DirInd_Rear_Status 1;
BA_ "Platform_Vivis2_Sig" SG_ 528 DirInd_Rear_Status 1;
BA_ "GenSigCycleTime" SG_ 517 FrontProhibitControlRequest 100;
BA_ "GenSigCycleTimeActive" SG_ 517 FrontProhibitControlRequest 100;
BA_ "GenSigStartValue" SG_ 517 FrontProhibitControlRequest 3;
BA_ "GenSigMaxLatency" SG_ 517 FrontProhibitControlRequest 23;
BA_ "Platform_VMCU1_Sig" SG_ 517 FrontProhibitControlRequest 1;
BA_ "Platform_Vivis2_Sig" SG_ 517 FrontProhibitControlRequest 1;
BA_ "GenSigCycleTime" SG_ 517 RampLevelStorageAck 100;
BA_ "GenSigCycleTimeActive" SG_ 517 RampLevelStorageAck 100;
BA_ "GenSigStartValue" SG_ 517 RampLevelStorageAck 3;
BA_ "GenSigMaxLatency" SG_ 517 RampLevelStorageAck 23;
BA_ "Platform_VMCU1_Sig" SG_ 517 RampLevelStorageAck 1;
BA_ "Platform_Vivis2_Sig" SG_ 517 RampLevelStorageAck 1;
BA_ "GenSigSendType" SG_ 517 BrakePressureSensorDemand_UB 7;
BA_ "Platform_VMCU1_Sig" SG_ 517 BrakePressureSensorDemand_UB 1;
BA_ "Platform_Vivis2_Sig" SG_ 517 BrakePressureSensorDemand_UB 1;
BA_ "GenSigCycleTime" SG_ 517 FrontLimpHomeCmd 100;
BA_ "GenSigCycleTimeActive" SG_ 517 FrontLimpHomeCmd 100;
BA_ "GenSigStartValue" SG_ 517 FrontLimpHomeCmd 7;
BA_ "GenSigMaxLatency" SG_ 517 FrontLimpHomeCmd 23;
BA_ "Platform_VMCU1_Sig" SG_ 517 FrontLimpHomeCmd 1;
BA_ "Platform_Vivis2_Sig" SG_ 517 FrontLimpHomeCmd 1;
BA_ "GenSigCycleTime" SG_ 517 LiftingControlModeRearAxle 100;
BA_ "GenSigCycleTimeActive" SG_ 517 LiftingControlModeRearAxle 100;
BA_ "GenSigStartValue" SG_ 517 LiftingControlModeRearAxle 3;
BA_ "GenSigMaxLatency" SG_ 517 LiftingControlModeRearAxle 23;
BA_ "Platform_VMCU1_Sig" SG_ 517 LiftingControlModeRearAxle 1;
BA_ "Platform_Vivis2_Sig" SG_ 517 LiftingControlModeRearAxle 1;
BA_ "GenSigCycleTime" SG_ 517 LoadDistributionChangeACK 100;
BA_ "GenSigCycleTimeActive" SG_ 517 LoadDistributionChangeACK 100;
BA_ "GenSigStartValue" SG_ 517 LoadDistributionChangeACK 7;
BA_ "GenSigMaxLatency" SG_ 517 LoadDistributionChangeACK 23;
BA_ "Platform_VMCU1_Sig" SG_ 517 LoadDistributionChangeACK 1;
BA_ "Platform_Vivis2_Sig" SG_ 517 LoadDistributionChangeACK 1;
BA_ "GenSigCycleTime" SG_ 517 ECSStandbyAllowed 100;
BA_ "GenSigCycleTimeActive" SG_ 517 ECSStandbyAllowed 100;
BA_ "GenSigStartValue" SG_ 517 ECSStandbyAllowed 3;
BA_ "Platform_VMCU1_Sig" SG_ 517 ECSStandbyAllowed 1;
BA_ "Platform_Vivis2_Sig" SG_ 517 ECSStandbyAllowed 1;
BA_ "GenSigCycleTime" SG_ 517 LiftAxle2LiftFuncSelected 100;
BA_ "GenSigCycleTimeActive" SG_ 517 LiftAxle2LiftFuncSelected 100;
BA_ "GenSigStartValue" SG_ 517 LiftAxle2LiftFuncSelected 7;
BA_ "Platform_Vivis2_Sig" SG_ 517 LiftAxle2LiftFuncSelected 1;
BA_ "GenSigCycleTime" SG_ 517 LiftAxle2UpRequestACK 100;
BA_ "GenSigCycleTimeActive" SG_ 517 LiftAxle2UpRequestACK 100;
BA_ "GenSigStartValue" SG_ 517 LiftAxle2UpRequestACK 7;
BA_ "GenSigMaxLatency" SG_ 517 LiftAxle2UpRequestACK 23;
BA_ "Platform_VMCU1_Sig" SG_ 517 LiftAxle2UpRequestACK 1;
BA_ "Platform_Vivis2_Sig" SG_ 517 LiftAxle2UpRequestACK 1;
BA_ "GenSigCycleTime" SG_ 517 ProhibitControlStatus 100;
BA_ "GenSigCycleTimeActive" SG_ 517 ProhibitControlStatus 100;
BA_ "GenSigStartValue" SG_ 517 ProhibitControlStatus 3;
BA_ "GenSigMaxLatency" SG_ 517 ProhibitControlStatus 23;
BA_ "Platform_VMCU1_Sig" SG_ 517 ProhibitControlStatus 1;
BA_ "Platform_Vivis2_Sig" SG_ 517 ProhibitControlStatus 1;
BA_ "GenSigCycleTime" SG_ 517 RampLevelStatus 100;
BA_ "GenSigCycleTimeActive" SG_ 517 RampLevelStatus 100;
BA_ "GenSigStartValue" SG_ 517 RampLevelStatus 15;
BA_ "GenSigMaxLatency" SG_ 517 RampLevelStatus 23;
BA_ "Platform_VMCU1_Sig" SG_ 517 RampLevelStatus 1;
BA_ "Platform_Vivis2_Sig" SG_ 517 RampLevelStatus 1;
BA_ "GenSigCycleTime" SG_ 517 StopLevelChangeAck 100;
BA_ "GenSigCycleTimeActive" SG_ 517 StopLevelChangeAck 100;
BA_ "GenSigStartValue" SG_ 517 StopLevelChangeAck 3;
BA_ "GenSigMaxLatency" SG_ 517 StopLevelChangeAck 23;
BA_ "Platform_VMCU1_Sig" SG_ 517 StopLevelChangeAck 1;
BA_ "Platform_Vivis2_Sig" SG_ 517 StopLevelChangeAck 1;
BA_ "GenSigCycleTime" SG_ 517 LiftAxle2LowerACK 100;
BA_ "GenSigCycleTimeActive" SG_ 517 LiftAxle2LowerACK 100;
BA_ "GenSigStartValue" SG_ 517 LiftAxle2LowerACK 7;
BA_ "Platform_Vivis2_Sig" SG_ 517 LiftAxle2LowerACK 1;
BA_ "GenSigCycleTime" SG_ 517 RideHeightStorageAck 100;
BA_ "GenSigCycleTimeActive" SG_ 517 RideHeightStorageAck 100;
BA_ "GenSigStartValue" SG_ 517 RideHeightStorageAck 3;
BA_ "GenSigMaxLatency" SG_ 517 RideHeightStorageAck 23;
BA_ "Platform_VMCU1_Sig" SG_ 517 RideHeightStorageAck 1;
BA_ "Platform_Vivis2_Sig" SG_ 517 RideHeightStorageAck 1;
BA_ "GenSigCycleTime" SG_ 517 FrontParkBrakeOverrideCommand 100;
BA_ "GenSigCycleTimeActive" SG_ 517 FrontParkBrakeOverrideCommand 100;
BA_ "GenSigStartValue" SG_ 517 FrontParkBrakeOverrideCommand 3;
BA_ "Platform_VMCU1_Sig" SG_ 517 FrontParkBrakeOverrideCommand 1;
BA_ "Platform_Vivis2_Sig" SG_ 517 FrontParkBrakeOverrideCommand 1;
BA_ "GenSigCycleTime" SG_ 517 RideHeightOutsideTargetRange 100;
BA_ "GenSigCycleTimeActive" SG_ 517 RideHeightOutsideTargetRange 100;
BA_ "GenSigStartValue" SG_ 517 RideHeightOutsideTargetRange 7;
BA_ "GenSigMaxLatency" SG_ 517 RideHeightOutsideTargetRange 23;
BA_ "Platform_VMCU1_Sig" SG_ 517 RideHeightOutsideTargetRange 1;
BA_ "Platform_Vivis2_Sig" SG_ 517 RideHeightOutsideTargetRange 1;
BA_ "GenSigCycleTime" SG_ 517 DisableMechFaultDctnFr_rqst 100;
BA_ "GenSigCycleTimeActive" SG_ 517 DisableMechFaultDctnFr_rqst 100;
BA_ "GenSigStartValue" SG_ 517 DisableMechFaultDctnFr_rqst 3;
BA_ "GenSigMaxLatency" SG_ 517 DisableMechFaultDctnFr_rqst 23;
BA_ "Platform_VMCU1_Sig" SG_ 517 DisableMechFaultDctnFr_rqst 1;
BA_ "Platform_Vivis2_Sig" SG_ 517 DisableMechFaultDctnFr_rqst 1;
BA_ "GenSigSendType" SG_ 517 RearAxleInBumperRange_UB 7;
BA_ "Platform_VMCU1_Sig" SG_ 517 RearAxleInBumperRange_UB 1;
BA_ "Platform_Vivis2_Sig" SG_ 517 RearAxleInBumperRange_UB 1;
BA_ "GenSigCycleTime" SG_ 517 BrakePressureSensorDemand 100;
BA_ "GenSigCycleTimeActive" SG_ 517 BrakePressureSensorDemand 100;
BA_ "GenSigStartValue" SG_ 517 BrakePressureSensorDemand 255;
BA_ "GenSigMaxLatency" SG_ 517 BrakePressureSensorDemand 23;
BA_ "NeedsUpdateBit" SG_ 517 BrakePressureSensorDemand 1;
BA_ "Platform_VMCU1_Sig" SG_ 517 BrakePressureSensorDemand 1;
BA_ "Platform_Vivis2_Sig" SG_ 517 BrakePressureSensorDemand 1;
BA_ "GenSigCycleTime" SG_ 517 FogLamp_Rear_Status 100;
BA_ "GenSigCycleTimeActive" SG_ 517 FogLamp_Rear_Status 100;
BA_ "GenSigStartValue" SG_ 517 FogLamp_Rear_Status 3;
BA_ "GenSigMaxLatency" SG_ 517 FogLamp_Rear_Status 23;
BA_ "Platform_VMCU1_Sig" SG_ 517 FogLamp_Rear_Status 1;
BA_ "Platform_Vivis2_Sig" SG_ 517 FogLamp_Rear_Status 1;
BA_ "GenSigCycleTime" SG_ 517 LiftingControlModeFrontAxle 100;
BA_ "GenSigCycleTimeActive" SG_ 517 LiftingControlModeFrontAxle 100;
BA_ "GenSigStartValue" SG_ 517 LiftingControlModeFrontAxle 3;
BA_ "GenSigMaxLatency" SG_ 517 LiftingControlModeFrontAxle 27;
BA_ "Platform_VMCU1_Sig" SG_ 517 LiftingControlModeFrontAxle 1;
BA_ "Platform_Vivis2_Sig" SG_ 517 LiftingControlModeFrontAxle 1;
BA_ "GenSigCycleTime" SG_ 517 LiftAxle1UpRequestACK 100;
BA_ "GenSigCycleTimeActive" SG_ 517 LiftAxle1UpRequestACK 100;
BA_ "GenSigStartValue" SG_ 517 LiftAxle1UpRequestACK 7;
BA_ "GenSigMaxLatency" SG_ 517 LiftAxle1UpRequestACK 23;
BA_ "Platform_VMCU1_Sig" SG_ 517 LiftAxle1UpRequestACK 1;
BA_ "Platform_Vivis2_Sig" SG_ 517 LiftAxle1UpRequestACK 1;
BA_ "GenSigCycleTime" SG_ 517 LiftAxle1LiftFuncSelected 100;
BA_ "GenSigCycleTimeActive" SG_ 517 LiftAxle1LiftFuncSelected 100;
BA_ "GenSigStartValue" SG_ 517 LiftAxle1LiftFuncSelected 7;
BA_ "Platform_Vivis2_Sig" SG_ 517 LiftAxle1LiftFuncSelected 1;
BA_ "GenSigCycleTime" SG_ 517 RearAxleInBumperRange 100;
BA_ "GenSigCycleTimeActive" SG_ 517 RearAxleInBumperRange 100;
BA_ "GenSigStartValue" SG_ 517 RearAxleInBumperRange 3;
BA_ "GenSigMaxLatency" SG_ 517 RearAxleInBumperRange 23;
BA_ "NeedsUpdateBit" SG_ 517 RearAxleInBumperRange 1;
BA_ "Platform_VMCU1_Sig" SG_ 517 RearAxleInBumperRange 1;
BA_ "Platform_Vivis2_Sig" SG_ 517 RearAxleInBumperRange 1;
BA_ "GenSigSendType" SG_ 2671833639 PhysDiagRespSig_F2_27 7;
BA_ "GenSigSendType" SG_ 2671833634 PhysDiagRespSig_F2_22 7;
BA_ "GenSigSendType" SG_ 2671833633 PhysDiagRespSig_F2_21 7;
BA_ "GenSigSendType" SG_ 2671833632 PhysDiagRespSig_F2_20 7;
BA_ "GenSigSendType" SG_ 2671833626 PhysDiagRespSig_F2_1A 7;
BA_ "GenSigSendType" SG_ 2671781874 PhysDiagReqSig_27_F2 7;
BA_ "GenSigSendType" SG_ 2671780594 PhysDiagReqSig_22_F2 7;
BA_ "GenSigSendType" SG_ 2671780338 PhysDiagReqSig_21_F2 7;
BA_ "GenSigSendType" SG_ 2671780082 PhysDiagReqSig_20_F2 7;
BA_ "GenSigSendType" SG_ 2671778546 PhysDiagReqSig_1A_F2 7;
BA_ "GenSigCycleTime" SG_ 1339 HeadlampFan_stat 100;
BA_ "GenSigCycleTimeActive" SG_ 1339 HeadlampFan_stat 100;
BA_ "GenSigStartValue" SG_ 1339 HeadlampFan_stat 7;
BA_ "Platform_Vivis2_Sig" SG_ 1339 HeadlampFan_stat 1;
BA_ "GenSigCycleTime" SG_ 1339 FrontConspicLamp_stat_HiRight 100;
BA_ "GenSigCycleTimeActive" SG_ 1339 FrontConspicLamp_stat_HiRight 100;
BA_ "GenSigStartValue" SG_ 1339 FrontConspicLamp_stat_HiRight 7;
BA_ "GenSigMaxLatency" SG_ 1339 FrontConspicLamp_stat_HiRight 250;
BA_ "Platform_Vivis2_Sig" SG_ 1339 FrontConspicLamp_stat_HiRight 1;
BA_ "GenSigCycleTime" SG_ 1339 AmbientAirTemperature2 100;
BA_ "GenSigCycleTimeActive" SG_ 1339 AmbientAirTemperature2 100;
BA_ "GenSigStartValue" SG_ 1339 AmbientAirTemperature2 65535;
BA_ "Platform_Vivis2_Sig" SG_ 1339 AmbientAirTemperature2 1;
BA_ "GenSigCycleTime" SG_ 1339 FrontConspicLamp_stat_LoRight 100;
BA_ "GenSigCycleTimeActive" SG_ 1339 FrontConspicLamp_stat_LoRight 100;
BA_ "GenSigStartValue" SG_ 1339 FrontConspicLamp_stat_LoRight 7;
BA_ "GenSigMaxLatency" SG_ 1339 FrontConspicLamp_stat_LoRight 250;
BA_ "Platform_Vivis2_Sig" SG_ 1339 FrontConspicLamp_stat_LoRight 1;
BA_ "GenSigCycleTime" SG_ 1339 FrontConspicLamp_stat_HiLeft 100;
BA_ "GenSigCycleTimeActive" SG_ 1339 FrontConspicLamp_stat_HiLeft 100;
BA_ "GenSigStartValue" SG_ 1339 FrontConspicLamp_stat_HiLeft 7;
BA_ "GenSigMaxLatency" SG_ 1339 FrontConspicLamp_stat_HiLeft 250;
BA_ "Platform_Vivis2_Sig" SG_ 1339 FrontConspicLamp_stat_HiLeft 1;
BA_ "GenSigCycleTime" SG_ 1339 FrontConspicLamp_stat_LoLeft 100;
BA_ "GenSigCycleTimeActive" SG_ 1339 FrontConspicLamp_stat_LoLeft 100;
BA_ "GenSigStartValue" SG_ 1339 FrontConspicLamp_stat_LoLeft 7;
BA_ "GenSigMaxLatency" SG_ 1339 FrontConspicLamp_stat_LoLeft 250;
BA_ "Platform_Vivis2_Sig" SG_ 1339 FrontConspicLamp_stat_LoLeft 1;
BA_ "GenSigCycleTime" SG_ 1243 MainBeamLEDStatusRight 100;
BA_ "GenSigCycleTimeActive" SG_ 1243 MainBeamLEDStatusRight 100;
BA_ "GenSigStartValue" SG_ 1243 MainBeamLEDStatusRight 7;
BA_ "Platform_VMCU1_Sig" SG_ 1243 MainBeamLEDStatusRight 1;
BA_ "Platform_Vivis2_Sig" SG_ 1243 MainBeamLEDStatusRight 1;
BA_ "GenSigCycleTime" SG_ 1243 DeicingBulb_Stat 100;
BA_ "GenSigCycleTimeActive" SG_ 1243 DeicingBulb_Stat 100;
BA_ "GenSigStartValue" SG_ 1243 DeicingBulb_Stat 7;
BA_ "Platform_Vivis2_Sig" SG_ 1243 DeicingBulb_Stat 1;
BA_ "GenSigCycleTime" SG_ 1243 DeicingFunction_Stat 100;
BA_ "GenSigCycleTimeActive" SG_ 1243 DeicingFunction_Stat 100;
BA_ "GenSigStartValue" SG_ 1243 DeicingFunction_Stat 7;
BA_ "Platform_Vivis2_Sig" SG_ 1243 DeicingFunction_Stat 1;
BA_ "GenSigCycleTime" SG_ 1243 MainBeamLEDStatusLeft 100;
BA_ "GenSigCycleTimeActive" SG_ 1243 MainBeamLEDStatusLeft 100;
BA_ "GenSigStartValue" SG_ 1243 MainBeamLEDStatusLeft 7;
BA_ "Platform_VMCU1_Sig" SG_ 1243 MainBeamLEDStatusLeft 1;
BA_ "Platform_Vivis2_Sig" SG_ 1243 MainBeamLEDStatusLeft 1;
BA_ "GenSigCycleTime" SG_ 952 DRLLamp_stat 100;
BA_ "GenSigCycleTimeActive" SG_ 952 DRLLamp_stat 100;
BA_ "GenSigInactiveValue" SG_ 952 DRLLamp_stat 7;
BA_ "GenSigStartValue" SG_ 952 DRLLamp_stat 7;
BA_ "GenSigMaxLatency" SG_ 952 DRLLamp_stat 59;
BA_ "Platform_VMCU1_Sig" SG_ 952 DRLLamp_stat 1;
BA_ "Platform_Vivis2_Sig" SG_ 952 DRLLamp_stat 1;
BA_ "GenSigCycleTime" SG_ 952 FogLamp_Front_Status 100;
BA_ "GenSigCycleTimeActive" SG_ 952 FogLamp_Front_Status 100;
BA_ "GenSigStartValue" SG_ 952 FogLamp_Front_Status 3;
BA_ "GenSigMaxLatency" SG_ 952 FogLamp_Front_Status 59;
BA_ "Platform_VMCU1_Sig" SG_ 952 FogLamp_Front_Status 1;
BA_ "Platform_Vivis2_Sig" SG_ 952 FogLamp_Front_Status 1;
BA_ "GenSigCycleTime" SG_ 952 DirIndSideLamp1_stat 100;
BA_ "GenSigCycleTimeActive" SG_ 952 DirIndSideLamp1_stat 100;
BA_ "GenSigStartValue" SG_ 952 DirIndSideLamp1_stat 7;
BA_ "Platform_VMCU1_Sig" SG_ 952 DirIndSideLamp1_stat 1;
BA_ "Platform_Vivis2_Sig" SG_ 952 DirIndSideLamp1_stat 1;
BA_ "GenSigCycleTime" SG_ 952 PositionLightLamp_stat 100;
BA_ "GenSigCycleTimeActive" SG_ 952 PositionLightLamp_stat 100;
BA_ "GenSigInactiveValue" SG_ 952 PositionLightLamp_stat 7;
BA_ "GenSigStartValue" SG_ 952 PositionLightLamp_stat 7;
BA_ "GenSigMaxLatency" SG_ 952 PositionLightLamp_stat 59;
BA_ "Platform_VMCU1_Sig" SG_ 952 PositionLightLamp_stat 1;
BA_ "Platform_Vivis2_Sig" SG_ 952 PositionLightLamp_stat 1;
BA_ "GenSigCycleTime" SG_ 952 DippedBeamLamp_stat 100;
BA_ "GenSigCycleTimeActive" SG_ 952 DippedBeamLamp_stat 100;
BA_ "GenSigInactiveValue" SG_ 952 DippedBeamLamp_stat 7;
BA_ "GenSigStartValue" SG_ 952 DippedBeamLamp_stat 7;
BA_ "GenSigMaxLatency" SG_ 952 DippedBeamLamp_stat 59;
BA_ "Platform_VMCU1_Sig" SG_ 952 DippedBeamLamp_stat 1;
BA_ "Platform_Vivis2_Sig" SG_ 952 DippedBeamLamp_stat 1;
BA_ "GenSigCycleTime" SG_ 952 MainBeamLamp_stat 100;
BA_ "GenSigCycleTimeActive" SG_ 952 MainBeamLamp_stat 100;
BA_ "GenSigStartValue" SG_ 952 MainBeamLamp_stat 7;
BA_ "Platform_Vivis2_Sig" SG_ 952 MainBeamLamp_stat 1;
BA_ "GenSigCycleTime" SG_ 952 StaticCornerLightLamp_stat 100;
BA_ "GenSigCycleTimeActive" SG_ 952 StaticCornerLightLamp_stat 100;
BA_ "GenSigInactiveValue" SG_ 952 StaticCornerLightLamp_stat 7;
BA_ "GenSigStartValue" SG_ 952 StaticCornerLightLamp_stat 7;
BA_ "GenSigMaxLatency" SG_ 952 StaticCornerLightLamp_stat 59;
BA_ "Platform_VMCU1_Sig" SG_ 952 StaticCornerLightLamp_stat 1;
BA_ "Platform_Vivis2_Sig" SG_ 952 StaticCornerLightLamp_stat 1;
BA_ "GenSigCycleTime" SG_ 952 AuxLamp_Front_Status 100;
BA_ "GenSigCycleTimeActive" SG_ 952 AuxLamp_Front_Status 100;
BA_ "GenSigStartValue" SG_ 952 AuxLamp_Front_Status 3;
BA_ "GenSigMaxLatency" SG_ 952 AuxLamp_Front_Status 59;
BA_ "Platform_VMCU1_Sig" SG_ 952 AuxLamp_Front_Status 1;
BA_ "Platform_Vivis2_Sig" SG_ 952 AuxLamp_Front_Status 1;
BA_ "GenSigCycleTime" SG_ 952 AuxFogLightLamp_stat 100;
BA_ "GenSigCycleTimeActive" SG_ 952 AuxFogLightLamp_stat 100;
BA_ "GenSigInactiveValue" SG_ 952 AuxFogLightLamp_stat 7;
BA_ "GenSigStartValue" SG_ 952 AuxFogLightLamp_stat 7;
BA_ "GenSigMaxLatency" SG_ 952 AuxFogLightLamp_stat 59;
BA_ "Platform_VMCU1_Sig" SG_ 952 AuxFogLightLamp_stat 1;
BA_ "Platform_Vivis2_Sig" SG_ 952 AuxFogLightLamp_stat 1;
BA_ "GenSigCycleTime" SG_ 952 ExtraMainBeamLamp_stat 100;
BA_ "GenSigCycleTimeActive" SG_ 952 ExtraMainBeamLamp_stat 100;
BA_ "GenSigInactiveValue" SG_ 952 ExtraMainBeamLamp_stat 7;
BA_ "GenSigStartValue" SG_ 952 ExtraMainBeamLamp_stat 7;
BA_ "GenSigMaxLatency" SG_ 952 ExtraMainBeamLamp_stat 59;
BA_ "Platform_VMCU1_Sig" SG_ 952 ExtraMainBeamLamp_stat 1;
BA_ "Platform_Vivis2_Sig" SG_ 952 ExtraMainBeamLamp_stat 1;
BA_ "GenSigCycleTime" SG_ 952 AmbientAirTemperature1 100;
BA_ "GenSigCycleTimeActive" SG_ 952 AmbientAirTemperature1 100;
BA_ "GenSigStartValue" SG_ 952 AmbientAirTemperature1 65535;
BA_ "Platform_Vivis2_Sig" SG_ 952 AmbientAirTemperature1 1;
BA_ "GenSigCycleTime" SG_ 952 FogLightFrontLamp_stat 100;
BA_ "GenSigCycleTimeActive" SG_ 952 FogLightFrontLamp_stat 100;
BA_ "GenSigInactiveValue" SG_ 952 FogLightFrontLamp_stat 7;
BA_ "GenSigStartValue" SG_ 952 FogLightFrontLamp_stat 7;
BA_ "GenSigMaxLatency" SG_ 952 FogLightFrontLamp_stat 59;
BA_ "Platform_VMCU1_Sig" SG_ 952 FogLightFrontLamp_stat 1;
BA_ "Platform_Vivis2_Sig" SG_ 952 FogLightFrontLamp_stat 1;
BA_ "GenSigCycleTime" SG_ 952 DirInd_Front_Status 100;
BA_ "GenSigCycleTimeActive" SG_ 952 DirInd_Front_Status 100;
BA_ "GenSigStartValue" SG_ 952 DirInd_Front_Status 7;
BA_ "GenSigMaxLatency" SG_ 952 DirInd_Front_Status 59;
BA_ "Platform_VMCU1_Sig" SG_ 952 DirInd_Front_Status 1;
BA_ "Platform_Vivis2_Sig" SG_ 952 DirInd_Front_Status 1;
BA_ "GenSigCycleTime" SG_ 952 ChassiInstepLightsLamp_stat 100;
BA_ "GenSigCycleTimeActive" SG_ 952 ChassiInstepLightsLamp_stat 100;
BA_ "GenSigInactiveValue" SG_ 952 ChassiInstepLightsLamp_stat 7;
BA_ "GenSigStartValue" SG_ 952 ChassiInstepLightsLamp_stat 7;
BA_ "GenSigMaxLatency" SG_ 952 ChassiInstepLightsLamp_stat 59;
BA_ "Platform_VMCU1_Sig" SG_ 952 ChassiInstepLightsLamp_stat 1;
BA_ "Platform_Vivis2_Sig" SG_ 952 ChassiInstepLightsLamp_stat 1;
BA_ "GenSigCycleTime" SG_ 952 WasherFluidLevel 100;
BA_ "GenSigCycleTimeActive" SG_ 952 WasherFluidLevel 100;
BA_ "GenSigStartValue" SG_ 952 WasherFluidLevel 7;
BA_ "GenSigMaxLatency" SG_ 952 WasherFluidLevel 59;
BA_ "Platform_VMCU1_Sig" SG_ 952 WasherFluidLevel 1;
BA_ "Platform_Vivis2_Sig" SG_ 952 WasherFluidLevel 1;
BA_ "GenSigCycleTime" SG_ 1232 TrailerCommunicationType 100;
BA_ "GenSigCycleTimeActive" SG_ 1232 TrailerCommunicationType 100;
BA_ "GenSigStartValue" SG_ 1232 TrailerCommunicationType 7;
BA_ "Platform_Vivis2_Sig" SG_ 1232 TrailerCommunicationType 1;
BA_ "GenSigCycleTime" SG_ 396 ThrdRrDriveAxLeftWheelSpeed 100;
BA_ "GenSigCycleTimeActive" SG_ 396 ThrdRrDriveAxLeftWheelSpeed 100;
BA_ "GenSigStartValue" SG_ 396 ThrdRrDriveAxLeftWheelSpeed 65535;
BA_ "Platform_Vivis2_Sig" SG_ 396 ThrdRrDriveAxLeftWheelSpeed 1;
BA_ "GenSigCycleTime" SG_ 396 ThrdRrDriveAxRightWheelSpeed 100;
BA_ "GenSigCycleTimeActive" SG_ 396 ThrdRrDriveAxRightWheelSpeed 100;
BA_ "GenSigStartValue" SG_ 396 ThrdRrDriveAxRightWheelSpeed 65535;
BA_ "Platform_Vivis2_Sig" SG_ 396 ThrdRrDriveAxRightWheelSpeed 1;
BA_ "GenSigCycleTime" SG_ 395 SteeringWheelAngle 100;
BA_ "GenSigCycleTimeActive" SG_ 395 SteeringWheelAngle 100;
BA_ "GenSigStartValue" SG_ 395 SteeringWheelAngle 65535;
BA_ "GenSigMaxLatency" SG_ 395 SteeringWheelAngle 23;
BA_ "NeedsUpdateBit" SG_ 395 SteeringWheelAngle 1;
BA_ "Platform_VMCU1_Sig" SG_ 395 SteeringWheelAngle 1;
BA_ "Platform_Vivis2_Sig" SG_ 395 SteeringWheelAngle 1;
BA_ "GenSigSendType" SG_ 395 SteeringWheelAngle_UB 7;
BA_ "Platform_VMCU1_Sig" SG_ 395 SteeringWheelAngle_UB 1;
BA_ "Platform_Vivis2_Sig" SG_ 395 SteeringWheelAngle_UB 1;
BA_ "GenSigCycleTime" SG_ 394 ScndRrDriveAxleLeftWheelSpeed 100;
BA_ "GenSigCycleTimeActive" SG_ 394 ScndRrDriveAxleLeftWheelSpeed 100;
BA_ "GenSigStartValue" SG_ 394 ScndRrDriveAxleLeftWheelSpeed 65535;
BA_ "GenSigMaxLatency" SG_ 394 ScndRrDriveAxleLeftWheelSpeed 22;
BA_ "Platform_VMCU1_Sig" SG_ 394 ScndRrDriveAxleLeftWheelSpeed 1;
BA_ "Platform_Vivis2_Sig" SG_ 394 ScndRrDriveAxleLeftWheelSpeed 1;
BA_ "GenSigCycleTime" SG_ 394 ScndRrDriveAxleRightWheelSpeed 100;
BA_ "GenSigCycleTimeActive" SG_ 394 ScndRrDriveAxleRightWheelSpeed 100;
BA_ "GenSigStartValue" SG_ 394 ScndRrDriveAxleRightWheelSpeed 65535;
BA_ "GenSigMaxLatency" SG_ 394 ScndRrDriveAxleRightWheelSpeed 22;
BA_ "Platform_VMCU1_Sig" SG_ 394 ScndRrDriveAxleRightWheelSpeed 1;
BA_ "Platform_Vivis2_Sig" SG_ 394 ScndRrDriveAxleRightWheelSpeed 1;
BA_ "GenSigCycleTime" SG_ 386 LateralAcceleration 100;
BA_ "GenSigCycleTimeActive" SG_ 386 LateralAcceleration 100;
BA_ "GenSigStartValue" SG_ 386 LateralAcceleration 65535;
BA_ "GenSigMaxLatency" SG_ 386 LateralAcceleration 20;
BA_ "Platform_VMCU1_Sig" SG_ 386 LateralAcceleration 1;
BA_ "Platform_Vivis2_Sig" SG_ 386 LateralAcceleration 1;
BA_ "GenSigCycleTime" SG_ 386 VDCBrakeLightRequest 100;
BA_ "GenSigCycleTimeActive" SG_ 386 VDCBrakeLightRequest 100;
BA_ "GenSigStartValue" SG_ 386 VDCBrakeLightRequest 3;
BA_ "GenSigMaxLatency" SG_ 386 VDCBrakeLightRequest 20;
BA_ "Platform_VMCU1_Sig" SG_ 386 VDCBrakeLightRequest 1;
BA_ "Platform_Vivis2_Sig" SG_ 386 VDCBrakeLightRequest 1;
BA_ "GenSigCycleTime" SG_ 386 EBSBrakeSwitch 100;
BA_ "GenSigCycleTimeActive" SG_ 386 EBSBrakeSwitch 100;
BA_ "GenSigStartValue" SG_ 386 EBSBrakeSwitch 3;
BA_ "GenSigMaxLatency" SG_ 386 EBSBrakeSwitch 20;
BA_ "Platform_VMCU1_Sig" SG_ 386 EBSBrakeSwitch 1;
BA_ "Platform_Vivis2_Sig" SG_ 386 EBSBrakeSwitch 1;
BA_ "GenSigCycleTime" SG_ 386 BrakeLightActivationRequest 100;
BA_ "GenSigCycleTimeActive" SG_ 386 BrakeLightActivationRequest 100;
BA_ "GenSigStartValue" SG_ 386 BrakeLightActivationRequest 3;
BA_ "Platform_VMCU1_Sig" SG_ 386 BrakeLightActivationRequest 1;
BA_ "Platform_Vivis2_Sig" SG_ 386 BrakeLightActivationRequest 1;
BA_ "GenSigCycleTime" SG_ 386 LongitudinalAcceleration 100;
BA_ "GenSigCycleTimeActive" SG_ 386 LongitudinalAcceleration 100;
BA_ "GenSigStartValue" SG_ 386 LongitudinalAcceleration 65535;
BA_ "GenSigMaxLatency" SG_ 386 LongitudinalAcceleration 20;
BA_ "Platform_VMCU1_Sig" SG_ 386 LongitudinalAcceleration 1;
BA_ "Platform_Vivis2_Sig" SG_ 386 LongitudinalAcceleration 1;
BA_ "GenSigCycleTime" SG_ 824 Trailer1TractionHelp 100;
BA_ "GenSigCycleTimeActive" SG_ 824 Trailer1TractionHelp 100;
BA_ "GenSigStartValue" SG_ 824 Trailer1TractionHelp 3;
BA_ "GenSigMaxLatency" SG_ 824 Trailer1TractionHelp 35;
BA_ "Platform_VMCU1_Sig" SG_ 824 Trailer1TractionHelp 1;
BA_ "Platform_Vivis2_Sig" SG_ 824 Trailer1TractionHelp 1;
BA_ "GenSigCycleTime" SG_ 824 TrailerBrake_Stat 100;
BA_ "GenSigCycleTimeActive" SG_ 824 TrailerBrake_Stat 100;
BA_ "GenSigStartValue" SG_ 824 TrailerBrake_Stat 3;
BA_ "GenSigMaxLatency" SG_ 824 TrailerBrake_Stat 35;
BA_ "Platform_VMCU1_Sig" SG_ 824 TrailerBrake_Stat 1;
BA_ "Platform_Vivis2_Sig" SG_ 824 TrailerBrake_Stat 1;
BA_ "GenSigCycleTime" SG_ 824 SplitBoxDiffLockActvnFuncReq 100;
BA_ "GenSigCycleTimeActive" SG_ 824 SplitBoxDiffLockActvnFuncReq 100;
BA_ "GenSigStartValue" SG_ 824 SplitBoxDiffLockActvnFuncReq 3;
BA_ "Platform_VMCU1_Sig" SG_ 824 SplitBoxDiffLockActvnFuncReq 1;
BA_ "Platform_Vivis2_Sig" SG_ 824 SplitBoxDiffLockActvnFuncReq 1;
BA_ "GenSigCycleTime" SG_ 824 BrakingSystemPressureLim_rqst 100;
BA_ "GenSigCycleTimeActive" SG_ 824 BrakingSystemPressureLim_rqst 100;
BA_ "GenSigStartValue" SG_ 824 BrakingSystemPressureLim_rqst 3;
BA_ "GenSigMaxLatency" SG_ 824 BrakingSystemPressureLim_rqst 107;
BA_ "Platform_VMCU1_Sig" SG_ 824 BrakingSystemPressureLim_rqst 1;
BA_ "Platform_Vivis2_Sig" SG_ 824 BrakingSystemPressureLim_rqst 1;
BA_ "GenSigCycleTime" SG_ 824 TagLiftAxleLoweringInhibit 100;
BA_ "GenSigCycleTimeActive" SG_ 824 TagLiftAxleLoweringInhibit 100;
BA_ "GenSigStartValue" SG_ 824 TagLiftAxleLoweringInhibit 3;
BA_ "GenSigMaxLatency" SG_ 824 TagLiftAxleLoweringInhibit 35;
BA_ "Platform_VMCU1_Sig" SG_ 824 TagLiftAxleLoweringInhibit 1;
BA_ "Platform_Vivis2_Sig" SG_ 824 TagLiftAxleLoweringInhibit 1;
BA_ "GenSigCycleTime" SG_ 824 ScndRrAxlDiffLckActvnFuncReq 100;
BA_ "GenSigCycleTimeActive" SG_ 824 ScndRrAxlDiffLckActvnFuncReq 100;
BA_ "GenSigStartValue" SG_ 824 ScndRrAxlDiffLckActvnFuncReq 3;
BA_ "Platform_Vivis2_Sig" SG_ 824 ScndRrAxlDiffLckActvnFuncReq 1;
BA_ "GenSigCycleTime" SG_ 824 Trailer1LiftAxle1Pos 100;
BA_ "GenSigCycleTimeActive" SG_ 824 Trailer1LiftAxle1Pos 100;
BA_ "GenSigStartValue" SG_ 824 Trailer1LiftAxle1Pos 3;
BA_ "Platform_Vivis2_Sig" SG_ 824 Trailer1LiftAxle1Pos 1;
BA_ "GenSigCycleTime" SG_ 824 PusherLiftAxleLoweringInhibit 100;
BA_ "GenSigCycleTimeActive" SG_ 824 PusherLiftAxleLoweringInhibit 100;
BA_ "GenSigStartValue" SG_ 824 PusherLiftAxleLoweringInhibit 3;
BA_ "GenSigMaxLatency" SG_ 824 PusherLiftAxleLoweringInhibit 35;
BA_ "Platform_VMCU1_Sig" SG_ 824 PusherLiftAxleLoweringInhibit 1;
BA_ "Platform_Vivis2_Sig" SG_ 824 PusherLiftAxleLoweringInhibit 1;
BA_ "GenSigCycleTime" SG_ 824 StretchBrake_Stat 100;
BA_ "GenSigCycleTimeActive" SG_ 824 StretchBrake_Stat 100;
BA_ "GenSigStartValue" SG_ 824 StretchBrake_Stat 7;
BA_ "GenSigMaxLatency" SG_ 824 StretchBrake_Stat 35;
BA_ "Platform_VMCU1_Sig" SG_ 824 StretchBrake_Stat 1;
BA_ "Platform_Vivis2_Sig" SG_ 824 StretchBrake_Stat 1;
BA_ "GenSigCycleTime" SG_ 824 TrailersConnected 100;
BA_ "GenSigCycleTimeActive" SG_ 824 TrailersConnected 100;
BA_ "GenSigInactiveValue" SG_ 824 TrailersConnected 7;
BA_ "GenSigStartValue" SG_ 824 TrailersConnected 7;
BA_ "GenSigMaxLatency" SG_ 824 TrailersConnected 35;
BA_ "Platform_VMCU1_Sig" SG_ 824 TrailersConnected 1;
BA_ "Platform_Vivis2_Sig" SG_ 824 TrailersConnected 1;
BA_ "GenSigCycleTime" SG_ 824 Trailer1LiftAxle2Pos 100;
BA_ "GenSigCycleTimeActive" SG_ 824 Trailer1LiftAxle2Pos 100;
BA_ "GenSigStartValue" SG_ 824 Trailer1LiftAxle2Pos 3;
BA_ "GenSigMaxLatency" SG_ 824 Trailer1LiftAxle2Pos 35;
BA_ "Platform_VMCU1_Sig" SG_ 824 Trailer1LiftAxle2Pos 1;
BA_ "Platform_Vivis2_Sig" SG_ 824 Trailer1LiftAxle2Pos 1;
BA_ "GenSigCycleTime" SG_ 824 TrailerEBSAmberWarning 100;
BA_ "GenSigCycleTimeActive" SG_ 824 TrailerEBSAmberWarning 100;
BA_ "GenSigStartValue" SG_ 824 TrailerEBSAmberWarning 3;
BA_ "Platform_VMCU1_Sig" SG_ 824 TrailerEBSAmberWarning 1;
BA_ "Platform_Vivis2_Sig" SG_ 824 TrailerEBSAmberWarning 1;
BA_ "GenSigCycleTime" SG_ 824 FrontParkBrakeOverrideStatus 100;
BA_ "GenSigCycleTimeActive" SG_ 824 FrontParkBrakeOverrideStatus 100;
BA_ "GenSigStartValue" SG_ 824 FrontParkBrakeOverrideStatus 3;
BA_ "GenSigMaxLatency" SG_ 824 FrontParkBrakeOverrideStatus 35;
BA_ "Platform_VMCU1_Sig" SG_ 824 FrontParkBrakeOverrideStatus 1;
BA_ "Platform_Vivis2_Sig" SG_ 824 FrontParkBrakeOverrideStatus 1;
BA_ "GenSigCycleTime" SG_ 516 EASPusherLiftAxleLoweringInhib 100;
BA_ "GenSigCycleTimeActive" SG_ 516 EASPusherLiftAxleLoweringInhib 100;
BA_ "GenSigStartValue" SG_ 516 EASPusherLiftAxleLoweringInhib 3;
BA_ "Platform_VMCU1_Sig" SG_ 516 EASPusherLiftAxleLoweringInhib 1;
BA_ "Platform_Vivis2_Sig" SG_ 516 EASPusherLiftAxleLoweringInhib 1;
BA_ "GenSigCycleTime" SG_ 1110 DummyApplicationSignal 100;
BA_ "GenSigCycleTimeActive" SG_ 1110 DummyApplicationSignal 100;
BA_ "GenSigSendType" SG_ 2671964711 DiagUUDTRespSig_F2_27 7;
BA_ "GenSigSendType" SG_ 2671964706 DiagUUDTRespSig_F2_22 7;
BA_ "GenSigSendType" SG_ 2671964705 DiagUUDTRespSig_F2_21 7;
BA_ "GenSigSendType" SG_ 2671964704 DiagUUDTRespSig_F2_20 7;
BA_ "GenSigSendType" SG_ 2671964698 DiagUUDTRespSig_F2_1A 7;
BA_ "GenSigSendType" SG_ 2671834151 InternalTesterDiagSig_F4_27 7;
BA_ "GenSigSendType" SG_ 2671834146 InternalTesterDiagSig_F4_22 7;
BA_ "GenSigSendType" SG_ 2671834145 InternalTesterDiagSig_F4_21 7;
BA_ "GenSigSendType" SG_ 2671834144 InternalTesterDiagSig_F4_20 7;
BA_ "GenSigSendType" SG_ 2671834138 InternalTesterDiagSig_F4_1A 7;
BA_ "GenSigSendType" SG_ 2671781876 InternalTesterDiagSig_27_F4 7;
BA_ "GenSigSendType" SG_ 2671780596 InternalTesterDiagSig_22_F4 7;
BA_ "GenSigSendType" SG_ 2671780340 InternalTesterDiagSig_21_F4 7;
BA_ "GenSigSendType" SG_ 2671780084 InternalTesterDiagSig_20_F4 7;
BA_ "GenSigSendType" SG_ 2671778548 InternalTesterDiagSig_1A_F4 7;
BA_ "GenSigSendType" SG_ 1500 DiagFaultStat_RCIOM_DtcIdB 3;
BA_ "GenSigStartValue" SG_ 1500 DiagFaultStat_RCIOM_DtcIdB 65535;
BA_ "NeedsUpdateBit" SG_ 1500 DiagFaultStat_RCIOM_DtcIdB 1;
BA_ "Platform_VMCU1_Sig" SG_ 1500 DiagFaultStat_RCIOM_DtcIdB 1;
BA_ "Platform_Vivis2_Sig" SG_ 1500 DiagFaultStat_RCIOM_DtcIdB 1;
BA_ "GenSigSendType" SG_ 1500 DiagFaultStat_RCIOM_sg_UB 7;
BA_ "Platform_VMCU1_Sig" SG_ 1500 DiagFaultStat_RCIOM_sg_UB 1;
BA_ "Platform_Vivis2_Sig" SG_ 1500 DiagFaultStat_RCIOM_sg_UB 1;
BA_ "GenSigSendType" SG_ 1500 DiagFaultStat_RCIOM_FailTA 3;
BA_ "GenSigStartValue" SG_ 1500 DiagFaultStat_RCIOM_FailTA 255;
BA_ "NeedsUpdateBit" SG_ 1500 DiagFaultStat_RCIOM_FailTA 1;
BA_ "Platform_VMCU1_Sig" SG_ 1500 DiagFaultStat_RCIOM_FailTA 1;
BA_ "Platform_Vivis2_Sig" SG_ 1500 DiagFaultStat_RCIOM_FailTA 1;
BA_ "GenSigSendType" SG_ 1500 DiagFaultStat_RCIOM_FailTB 3;
BA_ "GenSigStartValue" SG_ 1500 DiagFaultStat_RCIOM_FailTB 255;
BA_ "NeedsUpdateBit" SG_ 1500 DiagFaultStat_RCIOM_FailTB 1;
BA_ "Platform_VMCU1_Sig" SG_ 1500 DiagFaultStat_RCIOM_FailTB 1;
BA_ "Platform_Vivis2_Sig" SG_ 1500 DiagFaultStat_RCIOM_FailTB 1;
BA_ "GenSigSendType" SG_ 1500 DiagFaultStat_RCIOM_DtcIdA 3;
BA_ "GenSigStartValue" SG_ 1500 DiagFaultStat_RCIOM_DtcIdA 65535;
BA_ "NeedsUpdateBit" SG_ 1500 DiagFaultStat_RCIOM_DtcIdA 1;
BA_ "Platform_VMCU1_Sig" SG_ 1500 DiagFaultStat_RCIOM_DtcIdA 1;
BA_ "Platform_Vivis2_Sig" SG_ 1500 DiagFaultStat_RCIOM_DtcIdA 1;
BA_ "GenSigSendType" SG_ 1500 DiagFaultStat_RCIOM_EcuAdr 3;
BA_ "GenSigStartValue" SG_ 1500 DiagFaultStat_RCIOM_EcuAdr 255;
BA_ "NeedsUpdateBit" SG_ 1500 DiagFaultStat_RCIOM_EcuAdr 1;
BA_ "Platform_VMCU1_Sig" SG_ 1500 DiagFaultStat_RCIOM_EcuAdr 1;
BA_ "Platform_Vivis2_Sig" SG_ 1500 DiagFaultStat_RCIOM_EcuAdr 1;
BA_ "GenSigSendType" SG_ 1497 DiagFaultStat_GFHCM2_DtcIdA 1;
BA_ "NeedsUpdateBit" SG_ 1497 DiagFaultStat_GFHCM2_DtcIdA 1;
BA_ "Platform_Vivis2_Sig" SG_ 1497 DiagFaultStat_GFHCM2_DtcIdA 1;
BA_ "GenSigSendType" SG_ 1497 DiagFaultStat_GFHCM2_FailTB 1;
BA_ "NeedsUpdateBit" SG_ 1497 DiagFaultStat_GFHCM2_FailTB 1;
BA_ "Platform_Vivis2_Sig" SG_ 1497 DiagFaultStat_GFHCM2_FailTB 1;
BA_ "GenSigSendType" SG_ 1497 DiagFaultStat_GFHCM2_DtcIdB 1;
BA_ "NeedsUpdateBit" SG_ 1497 DiagFaultStat_GFHCM2_DtcIdB 1;
BA_ "Platform_Vivis2_Sig" SG_ 1497 DiagFaultStat_GFHCM2_DtcIdB 1;
BA_ "GenSigSendType" SG_ 1497 DiagFaultStat_GFHCM2_EcuAdr 1;
BA_ "GenSigStartValue" SG_ 1497 DiagFaultStat_GFHCM2_EcuAdr 255;
BA_ "NeedsUpdateBit" SG_ 1497 DiagFaultStat_GFHCM2_EcuAdr 1;
BA_ "Platform_Vivis2_Sig" SG_ 1497 DiagFaultStat_GFHCM2_EcuAdr 1;
BA_ "GenSigSendType" SG_ 1497 DiagFaultStat_GFHCM2_FailTA 1;
BA_ "NeedsUpdateBit" SG_ 1497 DiagFaultStat_GFHCM2_FailTA 1;
BA_ "Platform_Vivis2_Sig" SG_ 1497 DiagFaultStat_GFHCM2_FailTA 1;
BA_ "GenSigSendType" SG_ 1497 DiagFaultStat_GFHCM2_sg_UB 7;
BA_ "Platform_Vivis2_Sig" SG_ 1497 DiagFaultStat_GFHCM2_sg_UB 1;
BA_ "GenSigSendType" SG_ 1496 DiagFaultStat_GFHCM1_EcuAdr 1;
BA_ "GenSigStartValue" SG_ 1496 DiagFaultStat_GFHCM1_EcuAdr 255;
BA_ "NeedsUpdateBit" SG_ 1496 DiagFaultStat_GFHCM1_EcuAdr 1;
BA_ "Platform_Vivis2_Sig" SG_ 1496 DiagFaultStat_GFHCM1_EcuAdr 1;
BA_ "GenSigSendType" SG_ 1496 DiagFaultStat_GFHCM1_DtcIdB 1;
BA_ "NeedsUpdateBit" SG_ 1496 DiagFaultStat_GFHCM1_DtcIdB 1;
BA_ "Platform_Vivis2_Sig" SG_ 1496 DiagFaultStat_GFHCM1_DtcIdB 1;
BA_ "GenSigSendType" SG_ 1496 DiagFaultStat_GFHCM1_FailTB 1;
BA_ "NeedsUpdateBit" SG_ 1496 DiagFaultStat_GFHCM1_FailTB 1;
BA_ "Platform_Vivis2_Sig" SG_ 1496 DiagFaultStat_GFHCM1_FailTB 1;
BA_ "GenSigSendType" SG_ 1496 DiagFaultStat_GFHCM1_sg_UB 7;
BA_ "Platform_Vivis2_Sig" SG_ 1496 DiagFaultStat_GFHCM1_sg_UB 1;
BA_ "GenSigSendType" SG_ 1496 DiagFaultStat_GFHCM1_FailTA 1;
BA_ "NeedsUpdateBit" SG_ 1496 DiagFaultStat_GFHCM1_FailTA 1;
BA_ "Platform_Vivis2_Sig" SG_ 1496 DiagFaultStat_GFHCM1_FailTA 1;
BA_ "GenSigSendType" SG_ 1496 DiagFaultStat_GFHCM1_DtcIdA 1;
BA_ "NeedsUpdateBit" SG_ 1496 DiagFaultStat_GFHCM1_DtcIdA 1;
BA_ "Platform_Vivis2_Sig" SG_ 1496 DiagFaultStat_GFHCM1_DtcIdA 1;
BA_ "GenSigSendType" SG_ 1499 DiagFaultStat_FCIOM_DtcIdA 3;
BA_ "NeedsUpdateBit" SG_ 1499 DiagFaultStat_FCIOM_DtcIdA 1;
BA_ "Platform_VMCU1_Sig" SG_ 1499 DiagFaultStat_FCIOM_DtcIdA 1;
BA_ "Platform_Vivis2_Sig" SG_ 1499 DiagFaultStat_FCIOM_DtcIdA 1;
BA_ "GenSigSendType" SG_ 1499 DiagFaultStat_FCIOM_sg_UB 7;
BA_ "Platform_VMCU1_Sig" SG_ 1499 DiagFaultStat_FCIOM_sg_UB 1;
BA_ "Platform_Vivis2_Sig" SG_ 1499 DiagFaultStat_FCIOM_sg_UB 1;
BA_ "GenSigSendType" SG_ 1499 DiagFaultStat_FCIOM_FailTA 3;
BA_ "NeedsUpdateBit" SG_ 1499 DiagFaultStat_FCIOM_FailTA 1;
BA_ "Platform_VMCU1_Sig" SG_ 1499 DiagFaultStat_FCIOM_FailTA 1;
BA_ "Platform_Vivis2_Sig" SG_ 1499 DiagFaultStat_FCIOM_FailTA 1;
BA_ "GenSigSendType" SG_ 1499 DiagFaultStat_FCIOM_FailTB 3;
BA_ "NeedsUpdateBit" SG_ 1499 DiagFaultStat_FCIOM_FailTB 1;
BA_ "Platform_VMCU1_Sig" SG_ 1499 DiagFaultStat_FCIOM_FailTB 1;
BA_ "Platform_Vivis2_Sig" SG_ 1499 DiagFaultStat_FCIOM_FailTB 1;
BA_ "GenSigSendType" SG_ 1499 DiagFaultStat_FCIOM_DtcIdB 3;
BA_ "NeedsUpdateBit" SG_ 1499 DiagFaultStat_FCIOM_DtcIdB 1;
BA_ "Platform_VMCU1_Sig" SG_ 1499 DiagFaultStat_FCIOM_DtcIdB 1;
BA_ "Platform_Vivis2_Sig" SG_ 1499 DiagFaultStat_FCIOM_DtcIdB 1;
BA_ "GenSigSendType" SG_ 1499 DiagFaultStat_FCIOM_EcuAdr 3;
BA_ "GenSigStartValue" SG_ 1499 DiagFaultStat_FCIOM_EcuAdr 255;
BA_ "NeedsUpdateBit" SG_ 1499 DiagFaultStat_FCIOM_EcuAdr 1;
BA_ "Platform_VMCU1_Sig" SG_ 1499 DiagFaultStat_FCIOM_EcuAdr 1;
BA_ "Platform_Vivis2_Sig" SG_ 1499 DiagFaultStat_FCIOM_EcuAdr 1;
BA_ "GenSigSendType" SG_ 1490 DiagFaultStat_CCIOM_EcuAdr 3;
BA_ "GenSigStartValue" SG_ 1490 DiagFaultStat_CCIOM_EcuAdr 255;
BA_ "NeedsUpdateBit" SG_ 1490 DiagFaultStat_CCIOM_EcuAdr 1;
BA_ "Platform_VMCU1_Sig" SG_ 1490 DiagFaultStat_CCIOM_EcuAdr 1;
BA_ "Platform_Vivis2_Sig" SG_ 1490 DiagFaultStat_CCIOM_EcuAdr 1;
BA_ "GenSigSendType" SG_ 1490 DiagFaultStat_CCIOM_FailTA 3;
BA_ "NeedsUpdateBit" SG_ 1490 DiagFaultStat_CCIOM_FailTA 1;
BA_ "Platform_VMCU1_Sig" SG_ 1490 DiagFaultStat_CCIOM_FailTA 1;
BA_ "Platform_Vivis2_Sig" SG_ 1490 DiagFaultStat_CCIOM_FailTA 1;
BA_ "GenSigSendType" SG_ 1490 DiagFaultStat_CCIOM_sg_UB 7;
BA_ "Platform_VMCU1_Sig" SG_ 1490 DiagFaultStat_CCIOM_sg_UB 1;
BA_ "Platform_Vivis2_Sig" SG_ 1490 DiagFaultStat_CCIOM_sg_UB 1;
BA_ "GenSigSendType" SG_ 1490 DiagFaultStat_CCIOM_DtcIdB 3;
BA_ "NeedsUpdateBit" SG_ 1490 DiagFaultStat_CCIOM_DtcIdB 1;
BA_ "Platform_VMCU1_Sig" SG_ 1490 DiagFaultStat_CCIOM_DtcIdB 1;
BA_ "Platform_Vivis2_Sig" SG_ 1490 DiagFaultStat_CCIOM_DtcIdB 1;
BA_ "GenSigSendType" SG_ 1490 DiagFaultStat_CCIOM_FailTB 3;
BA_ "NeedsUpdateBit" SG_ 1490 DiagFaultStat_CCIOM_FailTB 1;
BA_ "Platform_VMCU1_Sig" SG_ 1490 DiagFaultStat_CCIOM_FailTB 1;
BA_ "Platform_Vivis2_Sig" SG_ 1490 DiagFaultStat_CCIOM_FailTB 1;
BA_ "GenSigSendType" SG_ 1490 DiagFaultStat_CCIOM_DtcIdA 3;
BA_ "NeedsUpdateBit" SG_ 1490 DiagFaultStat_CCIOM_DtcIdA 1;
BA_ "Platform_VMCU1_Sig" SG_ 1490 DiagFaultStat_CCIOM_DtcIdA 1;
BA_ "Platform_Vivis2_Sig" SG_ 1490 DiagFaultStat_CCIOM_DtcIdA 1;
BA_ "GenSigCycleTime" SG_ 1372 OpLevelItem11 100;
BA_ "GenSigCycleTimeActive" SG_ 1372 OpLevelItem11 100;
BA_ "GenSigStartValue" SG_ 1372 OpLevelItem11 255;
BA_ "GenSigMaxLatency" SG_ 1372 OpLevelItem11 500;
BA_ "Platform_Vivis2_Sig" SG_ 1372 OpLevelItem11 1;
BA_ "GenSigCycleTime" SG_ 1372 OpLevelItem14 100;
BA_ "GenSigCycleTimeActive" SG_ 1372 OpLevelItem14 100;
BA_ "GenSigStartValue" SG_ 1372 OpLevelItem14 255;
BA_ "GenSigMaxLatency" SG_ 1372 OpLevelItem14 500;
BA_ "Platform_Vivis2_Sig" SG_ 1372 OpLevelItem14 1;
BA_ "GenSigCycleTime" SG_ 1372 OpLevelItem12 100;
BA_ "GenSigCycleTimeActive" SG_ 1372 OpLevelItem12 100;
BA_ "GenSigStartValue" SG_ 1372 OpLevelItem12 255;
BA_ "GenSigMaxLatency" SG_ 1372 OpLevelItem12 500;
BA_ "Platform_Vivis2_Sig" SG_ 1372 OpLevelItem12 1;
BA_ "GenSigCycleTime" SG_ 1372 OpLevelItem15 100;
BA_ "GenSigCycleTimeActive" SG_ 1372 OpLevelItem15 100;
BA_ "GenSigStartValue" SG_ 1372 OpLevelItem15 255;
BA_ "GenSigMaxLatency" SG_ 1372 OpLevelItem15 500;
BA_ "Platform_Vivis2_Sig" SG_ 1372 OpLevelItem15 1;
BA_ "GenSigCycleTime" SG_ 1372 OpLevelItem13 100;
BA_ "GenSigCycleTimeActive" SG_ 1372 OpLevelItem13 100;
BA_ "GenSigStartValue" SG_ 1372 OpLevelItem13 255;
BA_ "GenSigMaxLatency" SG_ 1372 OpLevelItem13 500;
BA_ "Platform_Vivis2_Sig" SG_ 1372 OpLevelItem13 1;
BA_ "GenSigCycleTime" SG_ 1371 OpLevelItem1 100;
BA_ "GenSigCycleTimeActive" SG_ 1371 OpLevelItem1 100;
BA_ "GenSigStartValue" SG_ 1371 OpLevelItem1 255;
BA_ "GenSigMaxLatency" SG_ 1371 OpLevelItem1 500;
BA_ "Platform_Vivis2_Sig" SG_ 1371 OpLevelItem1 1;
BA_ "GenSigCycleTime" SG_ 1371 OpLevelItem8 100;
BA_ "GenSigCycleTimeActive" SG_ 1371 OpLevelItem8 100;
BA_ "GenSigStartValue" SG_ 1371 OpLevelItem8 255;
BA_ "GenSigMaxLatency" SG_ 1371 OpLevelItem8 500;
BA_ "Platform_Vivis2_Sig" SG_ 1371 OpLevelItem8 1;
BA_ "GenSigCycleTime" SG_ 1371 OpLevelItem5 100;
BA_ "GenSigCycleTimeActive" SG_ 1371 OpLevelItem5 100;
BA_ "GenSigStartValue" SG_ 1371 OpLevelItem5 255;
BA_ "GenSigMaxLatency" SG_ 1371 OpLevelItem5 500;
BA_ "Platform_Vivis2_Sig" SG_ 1371 OpLevelItem5 1;
BA_ "GenSigCycleTime" SG_ 1371 OpLevelItem6 100;
BA_ "GenSigCycleTimeActive" SG_ 1371 OpLevelItem6 100;
BA_ "GenSigStartValue" SG_ 1371 OpLevelItem6 255;
BA_ "GenSigMaxLatency" SG_ 1371 OpLevelItem6 500;
BA_ "Platform_Vivis2_Sig" SG_ 1371 OpLevelItem6 1;
BA_ "GenSigCycleTime" SG_ 1371 OpLevelItem10 100;
BA_ "GenSigCycleTimeActive" SG_ 1371 OpLevelItem10 100;
BA_ "GenSigStartValue" SG_ 1371 OpLevelItem10 255;
BA_ "GenSigMaxLatency" SG_ 1371 OpLevelItem10 500;
BA_ "Platform_Vivis2_Sig" SG_ 1371 OpLevelItem10 1;
BA_ "GenSigCycleTime" SG_ 1371 OpLevelItem7 100;
BA_ "GenSigCycleTimeActive" SG_ 1371 OpLevelItem7 100;
BA_ "GenSigStartValue" SG_ 1371 OpLevelItem7 255;
BA_ "GenSigMaxLatency" SG_ 1371 OpLevelItem7 500;
BA_ "Platform_Vivis2_Sig" SG_ 1371 OpLevelItem7 1;
BA_ "GenSigCycleTime" SG_ 1371 OpLevelItem9 100;
BA_ "GenSigCycleTimeActive" SG_ 1371 OpLevelItem9 100;
BA_ "GenSigStartValue" SG_ 1371 OpLevelItem9 255;
BA_ "GenSigMaxLatency" SG_ 1371 OpLevelItem9 500;
BA_ "Platform_Vivis2_Sig" SG_ 1371 OpLevelItem9 1;
BA_ "GenSigCycleTime" SG_ 1371 OpLevelItem4 100;
BA_ "GenSigCycleTimeActive" SG_ 1371 OpLevelItem4 100;
BA_ "GenSigStartValue" SG_ 1371 OpLevelItem4 255;
BA_ "GenSigMaxLatency" SG_ 1371 OpLevelItem4 500;
BA_ "Platform_Vivis2_Sig" SG_ 1371 OpLevelItem4 1;
BA_ "GenSigCycleTime" SG_ 1362 Cur_EnergySetting 100;
BA_ "GenSigCycleTimeActive" SG_ 1362 Cur_EnergySetting 100;
BA_ "GenSigStartValue" SG_ 1362 Cur_EnergySetting 7;
BA_ "Platform_Vivis2_Sig" SG_ 1362 Cur_EnergySetting 1;
BA_ "GenSigCycleTime" SG_ 1362 Cur_LG5CutoffValue 100;
BA_ "GenSigCycleTimeActive" SG_ 1362 Cur_LG5CutoffValue 100;
BA_ "GenSigStartValue" SG_ 1362 Cur_LG5CutoffValue 255;
BA_ "Platform_Vivis2_Sig" SG_ 1362 Cur_LG5CutoffValue 1;
BA_ "GenSigCycleTime" SG_ 1362 Cur_LG6CutoffValue 100;
BA_ "GenSigCycleTimeActive" SG_ 1362 Cur_LG6CutoffValue 100;
BA_ "GenSigStartValue" SG_ 1362 Cur_LG6CutoffValue 255;
BA_ "Platform_Vivis2_Sig" SG_ 1362 Cur_LG6CutoffValue 1;
BA_ "GenSigCycleTime" SG_ 1362 Cur_LG2CutoffValue 100;
BA_ "GenSigCycleTimeActive" SG_ 1362 Cur_LG2CutoffValue 100;
BA_ "GenSigStartValue" SG_ 1362 Cur_LG2CutoffValue 255;
BA_ "Platform_Vivis2_Sig" SG_ 1362 Cur_LG2CutoffValue 1;
BA_ "GenSigCycleTime" SG_ 1362 Cur_LG1CutoffValue 100;
BA_ "GenSigCycleTimeActive" SG_ 1362 Cur_LG1CutoffValue 100;
BA_ "GenSigStartValue" SG_ 1362 Cur_LG1CutoffValue 255;
BA_ "Platform_Vivis2_Sig" SG_ 1362 Cur_LG1CutoffValue 1;
BA_ "GenSigCycleTime" SG_ 1362 Cur_LG4CutoffValue 100;
BA_ "GenSigCycleTimeActive" SG_ 1362 Cur_LG4CutoffValue 100;
BA_ "GenSigStartValue" SG_ 1362 Cur_LG4CutoffValue 255;
BA_ "Platform_Vivis2_Sig" SG_ 1362 Cur_LG4CutoffValue 1;
BA_ "GenSigCycleTime" SG_ 1362 Cur_LG3CutoffValue 100;
BA_ "GenSigCycleTimeActive" SG_ 1362 Cur_LG3CutoffValue 100;
BA_ "GenSigStartValue" SG_ 1362 Cur_LG3CutoffValue 255;
BA_ "Platform_Vivis2_Sig" SG_ 1362 Cur_LG3CutoffValue 1;
BA_ "GenSigCycleTime" SG_ 1444 CrankDiagInfo4_1 100;
BA_ "GenSigCycleTimeActive" SG_ 1444 CrankDiagInfo4_1 100;
BA_ "GenSigStartValue" SG_ 1444 CrankDiagInfo4_1 2047;
BA_ "GenSigMaxLatency" SG_ 1444 CrankDiagInfo4_1 1010;
BA_ "Platform_Vivis2_Sig" SG_ 1444 CrankDiagInfo4_1 1;
BA_ "GenSigCycleTime" SG_ 1444 CrankDiagInfo3_1 100;
BA_ "GenSigCycleTimeActive" SG_ 1444 CrankDiagInfo3_1 100;
BA_ "GenSigStartValue" SG_ 1444 CrankDiagInfo3_1 65535;
BA_ "GenSigMaxLatency" SG_ 1444 CrankDiagInfo3_1 1010;
BA_ "Platform_Vivis2_Sig" SG_ 1444 CrankDiagInfo3_1 1;
BA_ "GenSigCycleTime" SG_ 1444 BatteryCapacityGrpAck_Pos3 100;
BA_ "GenSigCycleTimeActive" SG_ 1444 BatteryCapacityGrpAck_Pos3 100;
BA_ "GenSigStartValue" SG_ 1444 BatteryCapacityGrpAck_Pos3 3;
BA_ "Platform_Vivis2_Sig" SG_ 1444 BatteryCapacityGrpAck_Pos3 1;
BA_ "GenSigCycleTime" SG_ 1444 CrankDiagInfo2_1 100;
BA_ "GenSigCycleTimeActive" SG_ 1444 CrankDiagInfo2_1 100;
BA_ "GenSigStartValue" SG_ 1444 CrankDiagInfo2_1 2047;
BA_ "GenSigMaxLatency" SG_ 1444 CrankDiagInfo2_1 1010;
BA_ "Platform_Vivis2_Sig" SG_ 1444 CrankDiagInfo2_1 1;
BA_ "GenSigCycleTime" SG_ 1444 BatteryCapacityGrpAck_Pos2 100;
BA_ "GenSigCycleTimeActive" SG_ 1444 BatteryCapacityGrpAck_Pos2 100;
BA_ "GenSigStartValue" SG_ 1444 BatteryCapacityGrpAck_Pos2 3;
BA_ "Platform_Vivis2_Sig" SG_ 1444 BatteryCapacityGrpAck_Pos2 1;
BA_ "GenSigCycleTime" SG_ 1444 BatteryCapacityGrpAck_Pos1 100;
BA_ "GenSigCycleTimeActive" SG_ 1444 BatteryCapacityGrpAck_Pos1 100;
BA_ "GenSigStartValue" SG_ 1444 BatteryCapacityGrpAck_Pos1 3;
BA_ "Platform_Vivis2_Sig" SG_ 1444 BatteryCapacityGrpAck_Pos1 1;
BA_ "GenSigCycleTime" SG_ 1444 CrankDiagInfo1_1 100;
BA_ "GenSigCycleTimeActive" SG_ 1444 CrankDiagInfo1_1 100;
BA_ "GenSigStartValue" SG_ 1444 CrankDiagInfo1_1 65535;
BA_ "GenSigMaxLatency" SG_ 1444 CrankDiagInfo1_1 1010;
BA_ "Platform_Vivis2_Sig" SG_ 1444 CrankDiagInfo1_1 1;
BA_ "GenSigCycleTime" SG_ 1471 BatterySOHCapa1_1 100;
BA_ "GenSigCycleTimeActive" SG_ 1471 BatterySOHCapa1_1 100;
BA_ "GenSigStartValue" SG_ 1471 BatterySOHCapa1_1 255;
BA_ "GenSigMaxLatency" SG_ 1471 BatterySOHCapa1_1 1010;
BA_ "Platform_Vivis2_Sig" SG_ 1471 BatterySOHCapa1_1 1;
BA_ "GenSigCycleTime" SG_ 1471 BatterySOCTrustLevel_stat1_1 100;
BA_ "GenSigCycleTimeActive" SG_ 1471 BatterySOCTrustLevel_stat1_1 100;
BA_ "GenSigStartValue" SG_ 1471 BatterySOCTrustLevel_stat1_1 15;
BA_ "GenSigMaxLatency" SG_ 1471 BatterySOCTrustLevel_stat1_1 1010;
BA_ "Platform_Vivis2_Sig" SG_ 1471 BatterySOCTrustLevel_stat1_1 1;
BA_ "GenSigCycleTime" SG_ 1471 EndOfDischargeStatus1_1 100;
BA_ "GenSigCycleTimeActive" SG_ 1471 EndOfDischargeStatus1_1 100;
BA_ "GenSigMaxLatency" SG_ 1471 EndOfDischargeStatus1_1 1010;
BA_ "Platform_Vivis2_Sig" SG_ 1471 EndOfDischargeStatus1_1 1;
BA_ "GenSigCycleTime" SG_ 1471 DeepDischargestatus_1 100;
BA_ "GenSigCycleTimeActive" SG_ 1471 DeepDischargestatus_1 100;
BA_ "GenSigMaxLatency" SG_ 1471 DeepDischargestatus_1 1010;
BA_ "Platform_Vivis2_Sig" SG_ 1471 DeepDischargestatus_1 1;
BA_ "GenSigCycleTime" SG_ 1471 BatteryEndOfCharge 100;
BA_ "GenSigCycleTimeActive" SG_ 1471 BatteryEndOfCharge 100;
BA_ "GenSigStartValue" SG_ 1471 BatteryEndOfCharge 3;
BA_ "Platform_Vivis2_Sig" SG_ 1471 BatteryEndOfCharge 1;
BA_ "GenSigCycleTime" SG_ 1471 BatteryExchangeDetect_1 100;
BA_ "GenSigCycleTimeActive" SG_ 1471 BatteryExchangeDetect_1 100;
BA_ "GenSigStartValue" SG_ 1471 BatteryExchangeDetect_1 7;
BA_ "GenSigMaxLatency" SG_ 1471 BatteryExchangeDetect_1 1010;
BA_ "Platform_Vivis2_Sig" SG_ 1471 BatteryExchangeDetect_1 1;
BA_ "GenSigCycleTime" SG_ 1471 BatterySOHTrustLevel_stat1_1 100;
BA_ "GenSigCycleTimeActive" SG_ 1471 BatterySOHTrustLevel_stat1_1 100;
BA_ "GenSigStartValue" SG_ 1471 BatterySOHTrustLevel_stat1_1 15;
BA_ "GenSigMaxLatency" SG_ 1471 BatterySOHTrustLevel_stat1_1 1010;
BA_ "Platform_Vivis2_Sig" SG_ 1471 BatterySOHTrustLevel_stat1_1 1;
BA_ "GenSigCycleTime" SG_ 1471 Endofchargestatus1_1 100;
BA_ "GenSigCycleTimeActive" SG_ 1471 Endofchargestatus1_1 100;
BA_ "GenSigMaxLatency" SG_ 1471 Endofchargestatus1_1 1010;
BA_ "Platform_Vivis2_Sig" SG_ 1471 Endofchargestatus1_1 1;
BA_ "GenSigCycleTime" SG_ 1471 BatterySOHPowerTrustLevel1_1 100;
BA_ "GenSigCycleTimeActive" SG_ 1471 BatterySOHPowerTrustLevel1_1 100;
BA_ "GenSigStartValue" SG_ 1471 BatterySOHPowerTrustLevel1_1 15;
BA_ "GenSigMaxLatency" SG_ 1471 BatterySOHPowerTrustLevel1_1 1010;
BA_ "Platform_Vivis2_Sig" SG_ 1471 BatterySOHPowerTrustLevel1_1 1;
BA_ "GenSigCycleTime" SG_ 1471 BatteryTempCo_1 100;
BA_ "GenSigCycleTimeActive" SG_ 1471 BatteryTempCo_1 100;
BA_ "GenSigStartValue" SG_ 1471 BatteryTempCo_1 255;
BA_ "GenSigMaxLatency" SG_ 1471 BatteryTempCo_1 1010;
BA_ "Platform_Vivis2_Sig" SG_ 1471 BatteryTempCo_1 1;
BA_ "GenSigCycleTime" SG_ 1471 BatterySOHPower1_1 100;
BA_ "GenSigCycleTimeActive" SG_ 1471 BatterySOHPower1_1 100;
BA_ "GenSigStartValue" SG_ 1471 BatterySOHPower1_1 255;
BA_ "GenSigMaxLatency" SG_ 1471 BatterySOHPower1_1 1010;
BA_ "Platform_Vivis2_Sig" SG_ 1471 BatterySOHPower1_1 1;
BA_ "GenSigCycleTime" SG_ 1471 BatteryReconnectionDetect_1 100;
BA_ "GenSigCycleTimeActive" SG_ 1471 BatteryReconnectionDetect_1 100;
BA_ "GenSigMaxLatency" SG_ 1471 BatteryReconnectionDetect_1 1010;
BA_ "Platform_Vivis2_Sig" SG_ 1471 BatteryReconnectionDetect_1 1;
BA_ "GenSigCycleTime" SG_ 1471 BatterySoCcrankLimit1_1 100;
BA_ "GenSigCycleTimeActive" SG_ 1471 BatterySoCcrankLimit1_1 100;
BA_ "GenSigStartValue" SG_ 1471 BatterySoCcrankLimit1_1 255;
BA_ "GenSigMaxLatency" SG_ 1471 BatterySoCcrankLimit1_1 1010;
BA_ "Platform_Vivis2_Sig" SG_ 1471 BatterySoCcrankLimit1_1 1;
BA_ "GenSigCycleTime" SG_ 1469 WhCounterCharge_1 100;
BA_ "GenSigCycleTimeActive" SG_ 1469 WhCounterCharge_1 100;
BA_ "GenSigStartValue" SG_ 1469 WhCounterCharge_1 65535;
BA_ "GenSigMaxLatency" SG_ 1469 WhCounterCharge_1 1011;
BA_ "Platform_Vivis2_Sig" SG_ 1469 WhCounterCharge_1 1;
BA_ "GenSigCycleTime" SG_ 1469 HighCurrentIR1_1 100;
BA_ "GenSigCycleTimeActive" SG_ 1469 HighCurrentIR1_1 100;
BA_ "GenSigStartValue" SG_ 1469 HighCurrentIR1_1 1023;
BA_ "GenSigMaxLatency" SG_ 1469 HighCurrentIR1_1 1011;
BA_ "Platform_Vivis2_Sig" SG_ 1469 HighCurrentIR1_1 1;
BA_ "GenSigCycleTime" SG_ 1469 WhCounterDischarge_1 100;
BA_ "GenSigCycleTimeActive" SG_ 1469 WhCounterDischarge_1 100;
BA_ "GenSigStartValue" SG_ 1469 WhCounterDischarge_1 65535;
BA_ "GenSigMaxLatency" SG_ 1469 WhCounterDischarge_1 1011;
BA_ "Platform_Vivis2_Sig" SG_ 1469 WhCounterDischarge_1 1;
BA_ "GenSigCycleTime" SG_ 1467 WhCounterCharge_1A 100;
BA_ "GenSigCycleTimeActive" SG_ 1467 WhCounterCharge_1A 100;
BA_ "GenSigStartValue" SG_ 1467 WhCounterCharge_1A 65535;
BA_ "GenSigMaxLatency" SG_ 1467 WhCounterCharge_1A 1012;
BA_ "Platform_Vivis2_Sig" SG_ 1467 WhCounterCharge_1A 1;
BA_ "GenSigCycleTime" SG_ 1467 HighCurrentIR1_1A 100;
BA_ "GenSigCycleTimeActive" SG_ 1467 HighCurrentIR1_1A 100;
BA_ "GenSigStartValue" SG_ 1467 HighCurrentIR1_1A 1023;
BA_ "GenSigMaxLatency" SG_ 1467 HighCurrentIR1_1A 1012;
BA_ "Platform_Vivis2_Sig" SG_ 1467 HighCurrentIR1_1A 1;
BA_ "GenSigCycleTime" SG_ 1467 WhCounterDischarge_1A 100;
BA_ "GenSigCycleTimeActive" SG_ 1467 WhCounterDischarge_1A 100;
BA_ "GenSigStartValue" SG_ 1467 WhCounterDischarge_1A 65535;
BA_ "GenSigMaxLatency" SG_ 1467 WhCounterDischarge_1A 1012;
BA_ "Platform_Vivis2_Sig" SG_ 1467 WhCounterDischarge_1A 1;
BA_ "GenSigCycleTime" SG_ 1465 HighCurrentIR1_1B 100;
BA_ "GenSigCycleTimeActive" SG_ 1465 HighCurrentIR1_1B 100;
BA_ "GenSigStartValue" SG_ 1465 HighCurrentIR1_1B 1023;
BA_ "GenSigMaxLatency" SG_ 1465 HighCurrentIR1_1B 1013;
BA_ "Platform_Vivis2_Sig" SG_ 1465 HighCurrentIR1_1B 1;
BA_ "GenSigCycleTime" SG_ 1465 WhCounterCharge_1B 100;
BA_ "GenSigCycleTimeActive" SG_ 1465 WhCounterCharge_1B 100;
BA_ "GenSigStartValue" SG_ 1465 WhCounterCharge_1B 65535;
BA_ "GenSigMaxLatency" SG_ 1465 WhCounterCharge_1B 1013;
BA_ "Platform_Vivis2_Sig" SG_ 1465 WhCounterCharge_1B 1;
BA_ "GenSigCycleTime" SG_ 1465 WhCounterDischarge_1B 100;
BA_ "GenSigCycleTimeActive" SG_ 1465 WhCounterDischarge_1B 100;
BA_ "GenSigStartValue" SG_ 1465 WhCounterDischarge_1B 65535;
BA_ "GenSigMaxLatency" SG_ 1465 WhCounterDischarge_1B 1013;
BA_ "Platform_Vivis2_Sig" SG_ 1465 WhCounterDischarge_1B 1;
BA_ "GenSigCycleTime" SG_ 1463 WhCounterDischarge_2A 100;
BA_ "GenSigCycleTimeActive" SG_ 1463 WhCounterDischarge_2A 100;
BA_ "GenSigStartValue" SG_ 1463 WhCounterDischarge_2A 65535;
BA_ "GenSigMaxLatency" SG_ 1463 WhCounterDischarge_2A 1014;
BA_ "Platform_Vivis2_Sig" SG_ 1463 WhCounterDischarge_2A 1;
BA_ "GenSigCycleTime" SG_ 1463 HighCurrentIR1_2A 100;
BA_ "GenSigCycleTimeActive" SG_ 1463 HighCurrentIR1_2A 100;
BA_ "GenSigStartValue" SG_ 1463 HighCurrentIR1_2A 1023;
BA_ "GenSigMaxLatency" SG_ 1463 HighCurrentIR1_2A 1014;
BA_ "Platform_Vivis2_Sig" SG_ 1463 HighCurrentIR1_2A 1;
BA_ "GenSigCycleTime" SG_ 1463 WhCounterCharge_2A 100;
BA_ "GenSigCycleTimeActive" SG_ 1463 WhCounterCharge_2A 100;
BA_ "GenSigStartValue" SG_ 1463 WhCounterCharge_2A 65535;
BA_ "GenSigMaxLatency" SG_ 1463 WhCounterCharge_2A 1014;
BA_ "Platform_Vivis2_Sig" SG_ 1463 WhCounterCharge_2A 1;
BA_ "GenSigCycleTime" SG_ 1461 HighCurrentIR1_2B 100;
BA_ "GenSigCycleTimeActive" SG_ 1461 HighCurrentIR1_2B 100;
BA_ "GenSigStartValue" SG_ 1461 HighCurrentIR1_2B 1023;
BA_ "GenSigMaxLatency" SG_ 1461 HighCurrentIR1_2B 1015;
BA_ "Platform_Vivis2_Sig" SG_ 1461 HighCurrentIR1_2B 1;
BA_ "GenSigCycleTime" SG_ 1461 WhCounterCharge_2B 100;
BA_ "GenSigCycleTimeActive" SG_ 1461 WhCounterCharge_2B 100;
BA_ "GenSigStartValue" SG_ 1461 WhCounterCharge_2B 65535;
BA_ "GenSigMaxLatency" SG_ 1461 WhCounterCharge_2B 1015;
BA_ "Platform_Vivis2_Sig" SG_ 1461 WhCounterCharge_2B 1;
BA_ "GenSigCycleTime" SG_ 1461 WhCounterDischarge_2B 100;
BA_ "GenSigCycleTimeActive" SG_ 1461 WhCounterDischarge_2B 100;
BA_ "GenSigStartValue" SG_ 1461 WhCounterDischarge_2B 65535;
BA_ "GenSigMaxLatency" SG_ 1461 WhCounterDischarge_2B 1015;
BA_ "Platform_Vivis2_Sig" SG_ 1461 WhCounterDischarge_2B 1;
BA_REL_ "GenSigFirstTimeoutTime" BU_SG_REL_ VCM SG_ 1343 TrailerDirIndLeftOutputStat 6000;
BA_REL_ "GenSigTimeoutTime" BU_SG_REL_ VCM SG_ 1343 TrailerDirIndLeftOutputStat 1500;
BA_REL_ "GenSigFirstTimeoutTime" BU_SG_REL_ VCM SG_ 1343 TrailerBrakeLightOutputStat 6000;
BA_REL_ "GenSigTimeoutTime" BU_SG_REL_ VCM SG_ 1343 TrailerBrakeLightOutputStat 1500;
BA_REL_ "GenSigFirstTimeoutTime" BU_SG_REL_ VCM SG_ 1343 TrailerPosLightRightOutputStat 6000;
BA_REL_ "GenSigTimeoutTime" BU_SG_REL_ VCM SG_ 1343 TrailerPosLightRightOutputStat 1500;
BA_REL_ "GenSigFirstTimeoutTime" BU_SG_REL_ VCM SG_ 1343 TrailerPosLightLeftOutputStat 6000;
BA_REL_ "GenSigTimeoutTime" BU_SG_REL_ VCM SG_ 1343 TrailerPosLightLeftOutputStat 1500;
BA_REL_ "GenSigFirstTimeoutTime" BU_SG_REL_ VCM SG_ 1343 LoadDistributionSelected2 6000;
BA_REL_ "GenSigTimeoutTime" BU_SG_REL_ VCM SG_ 1343 LoadDistributionSelected2 1500;
BA_REL_ "GenSigFirstTimeoutTime" BU_SG_REL_ VCM SG_ 1343 DriveAxleLoad 6000;
BA_REL_ "GenSigTimeoutTime" BU_SG_REL_ VCM SG_ 1343 DriveAxleLoad 1500;
BA_REL_ "GenSigFirstTimeoutTime" BU_SG_REL_ VCM SG_ 1343 TrailerDirIndRightOutputStat 6000;
BA_REL_ "GenSigTimeoutTime" BU_SG_REL_ VCM SG_ 1343 TrailerDirIndRightOutputStat 1500;
BA_REL_ "GenSigFirstTimeoutTime" BU_SG_REL_ VCM SG_ 1343 ExtECSPressureUpdateAck 6000;
BA_REL_ "GenSigTimeoutTime" BU_SG_REL_ VCM SG_ 1343 ExtECSPressureUpdateAck 1500;
BA_REL_ "GenSigFirstTimeoutTime" BU_SG_REL_ VCM SG_ 1343 SecondaryDriveAxleLoad 6000;
BA_REL_ "GenSigTimeoutTime" BU_SG_REL_ VCM SG_ 1343 SecondaryDriveAxleLoad 1500;
BA_REL_ "GenSigFirstTimeoutTime" BU_SG_REL_ VCM SG_ 825 RevLightLamp_stat 3000;
BA_REL_ "GenSigTimeoutTime" BU_SG_REL_ VCM SG_ 825 RevLightLamp_stat 180;
BA_REL_ "GenSigFirstTimeoutTime" BU_SG_REL_ VCM SG_ 825 FirstAxleLowerPrioSelected 3000;
BA_REL_ "GenSigTimeoutTime" BU_SG_REL_ VCM SG_ 825 FirstAxleLowerPrioSelected 180;
BA_REL_ "GenSigFirstTimeoutTime" BU_SG_REL_ VCM SG_ 825 FrontParkBrakeOverrideInd 3000;
BA_REL_ "GenSigTimeoutTime" BU_SG_REL_ VCM SG_ 825 FrontParkBrakeOverrideInd 180;
BA_REL_ "GenSigFirstTimeoutTime" BU_SG_REL_ VCM SG_ 825 ECSLimpHomeNotification 3000;
BA_REL_ "GenSigTimeoutTime" BU_SG_REL_ VCM SG_ 825 ECSLimpHomeNotification 180;
BA_REL_ "GenSigFirstTimeoutTime" BU_SG_REL_ VCM SG_ 825 ECSValveActivationAllowed 3000;
BA_REL_ "GenSigTimeoutTime" BU_SG_REL_ VCM SG_ 825 ECSValveActivationAllowed 180;
BA_REL_ "GenSigFirstTimeoutTime" BU_SG_REL_ CCIOM SG_ 825 ECSValveActivationAllowed 3000;
BA_REL_ "GenSigTimeoutTime" BU_SG_REL_ CCIOM SG_ 825 ECSValveActivationAllowed 180;
BA_REL_ "GenSigFirstTimeoutTime" BU_SG_REL_ VCM SG_ 825 UnevenLoadWarning 3000;
BA_REL_ "GenSigTimeoutTime" BU_SG_REL_ VCM SG_ 825 UnevenLoadWarning 180;
BA_REL_ "GenSigFirstTimeoutTime" BU_SG_REL_ VCM SG_ 825 RampLevelRequestACK 3000;
BA_REL_ "GenSigTimeoutTime" BU_SG_REL_ VCM SG_ 825 RampLevelRequestACK 180;
BA_REL_ "GenSigFirstTimeoutTime" BU_SG_REL_ VCM SG_ 825 LoadDistributionSelected 3000;
BA_REL_ "GenSigTimeoutTime" BU_SG_REL_ VCM SG_ 825 LoadDistributionSelected 180;
BA_REL_ "GenSigFirstTimeoutTime" BU_SG_REL_ VCM SG_ 825 TrailerABSStatus 3000;
BA_REL_ "GenSigTimeoutTime" BU_SG_REL_ VCM SG_ 825 TrailerABSStatus 180;
BA_REL_ "GenSigFirstTimeoutTime" BU_SG_REL_ VCM SG_ 825 RevLight_cmd 3000;
BA_REL_ "GenSigTimeoutTime" BU_SG_REL_ VCM SG_ 825 RevLight_cmd 180;
BA_REL_ "GenSigFirstTimeoutTime" BU_SG_REL_ CCIOM SG_ 825 RevLight_cmd 3000;
BA_REL_ "GenSigTimeoutTime" BU_SG_REL_ CCIOM SG_ 825 RevLight_cmd 180;
BA_REL_ "GenSigFirstTimeoutTime" BU_SG_REL_ VCM SG_ 825 LoadDistributionALDChangeACK 3000;
BA_REL_ "GenSigTimeoutTime" BU_SG_REL_ VCM SG_ 825 LoadDistributionALDChangeACK 180;
BA_REL_ "GenSigFirstTimeoutTime" BU_SG_REL_ VCM SG_ 825 FogLightRearLamp_stat 3000;
BA_REL_ "GenSigTimeoutTime" BU_SG_REL_ VCM SG_ 825 FogLightRearLamp_stat 180;
BA_REL_ "GenSigFirstTimeoutTime" BU_SG_REL_ VCM SG_ 825 PositionLightRearLamp_stat 3000;
BA_REL_ "GenSigTimeoutTime" BU_SG_REL_ VCM SG_ 825 PositionLightRearLamp_stat 180;
BA_REL_ "GenSigFirstTimeoutTime" BU_SG_REL_ VCM SG_ 825 FerryFunctionSwitchChangeACK 3000;
BA_REL_ "GenSigTimeoutTime" BU_SG_REL_ VCM SG_ 825 FerryFunctionSwitchChangeACK 180;
BA_REL_ "GenSigFirstTimeoutTime" BU_SG_REL_ VCM SG_ 825 BrakeLight_rqst 3000;
BA_REL_ "GenSigTimeoutTime" BU_SG_REL_ VCM SG_ 825 BrakeLight_rqst 500;
BA_REL_ "GenSigFirstTimeoutTime" BU_SG_REL_ VCM SG_ 825 BrakeLightConvoy_rqst 3000;
BA_REL_ "GenSigTimeoutTime" BU_SG_REL_ VCM SG_ 825 BrakeLightConvoy_rqst 500;
BA_REL_ "GenSigFirstTimeoutTime" BU_SG_REL_ VCM SG_ 825 LiftAxle1AutoLiftSelected 3000;
BA_REL_ "GenSigTimeoutTime" BU_SG_REL_ VCM SG_ 825 LiftAxle1AutoLiftSelected 180;
BA_REL_ "GenSigFirstTimeoutTime" BU_SG_REL_ VCM SG_ 825 BrakeLightLamp_stat 3000;
BA_REL_ "GenSigTimeoutTime" BU_SG_REL_ VCM SG_ 825 BrakeLightLamp_stat 180;
BA_REL_ "GenSigFirstTimeoutTime" BU_SG_REL_ VCM SG_ 825 LiftAxle2AutoLiftSelected 3000;
BA_REL_ "GenSigTimeoutTime" BU_SG_REL_ VCM SG_ 825 LiftAxle2AutoLiftSelected 180;
BA_REL_ "GenSigFirstTimeoutTime" BU_SG_REL_ VCM SG_ 825 StartupProhibitStatus 3000;
BA_REL_ "GenSigTimeoutTime" BU_SG_REL_ VCM SG_ 825 StartupProhibitStatus 180;
BA_REL_ "GenSigFirstTimeoutTime" BU_SG_REL_ VCM SG_ 825 LiftAxle1LowerACK 3000;
BA_REL_ "GenSigTimeoutTime" BU_SG_REL_ VCM SG_ 825 LiftAxle1LowerACK 180;
BA_REL_ "GenSigFirstTimeoutTime" BU_SG_REL_ VCM SG_ 825 TrailerDirInd_status 3000;
BA_REL_ "GenSigTimeoutTime" BU_SG_REL_ VCM SG_ 825 TrailerDirInd_status 180;
BA_REL_ "GenSigFirstTimeoutTime" BU_SG_REL_ VCM SG_ 825 DriveLevelPosUserInteraction 3000;
BA_REL_ "GenSigTimeoutTime" BU_SG_REL_ VCM SG_ 825 DriveLevelPosUserInteraction 180;
BA_REL_ "GenSigFirstTimeoutTime" BU_SG_REL_ VCM SG_ 948 FrontEndPositionStatus 3000;
BA_REL_ "GenSigTimeoutTime" BU_SG_REL_ VCM SG_ 948 FrontEndPositionStatus 300;
BA_REL_ "GenSigFirstTimeoutTime" BU_SG_REL_ VCM SG_ 948 DirIndRearLamp_Stat 3000;
BA_REL_ "GenSigTimeoutTime" BU_SG_REL_ VCM SG_ 948 DirIndRearLamp_Stat 500;
BA_REL_ "GenSigFirstTimeoutTime" BU_SG_REL_ VCM SG_ 948 FrontAxleInBumperRange 3000;
BA_REL_ "GenSigTimeoutTime" BU_SG_REL_ VCM SG_ 948 FrontAxleInBumperRange 500;
BA_REL_ "GenSigFirstTimeoutTime" BU_SG_REL_ VCM SG_ 948 FrontRollAngleRef 3000;
BA_REL_ "GenSigTimeoutTime" BU_SG_REL_ VCM SG_ 948 FrontRollAngleRef 300;
BA_REL_ "GenSigFirstTimeoutTime" BU_SG_REL_ CCIOM SG_ 948 FrontRollAngleRef 3000;
BA_REL_ "GenSigTimeoutTime" BU_SG_REL_ CCIOM SG_ 948 FrontRollAngleRef 300;
BA_REL_ "GenSigFirstTimeoutTime" BU_SG_REL_ CCIOM SG_ 948 FrontSideKneelingAngleRef 3000;
BA_REL_ "GenSigTimeoutTime" BU_SG_REL_ CCIOM SG_ 948 FrontSideKneelingAngleRef 300;
BA_REL_ "GenSigFirstTimeoutTime" BU_SG_REL_ VCM SG_ 948 FrontSideKneelingAngleRef 3000;
BA_REL_ "GenSigTimeoutTime" BU_SG_REL_ VCM SG_ 948 FrontSideKneelingAngleRef 300;
BA_REL_ "GenSigFirstTimeoutTime" BU_SG_REL_ VCM SG_ 948 LoadDistributionRequestedACK 3000;
BA_REL_ "GenSigTimeoutTime" BU_SG_REL_ VCM SG_ 948 LoadDistributionRequestedACK 300;
BA_REL_ "GenSigFirstTimeoutTime" BU_SG_REL_ VCM SG_ 948 TotalFrontBellowTorqueRef 3000;
BA_REL_ "GenSigTimeoutTime" BU_SG_REL_ VCM SG_ 948 TotalFrontBellowTorqueRef 300;
BA_REL_ "GenSigFirstTimeoutTime" BU_SG_REL_ CCIOM SG_ 948 TotalFrontBellowTorqueRef 3000;
BA_REL_ "GenSigTimeoutTime" BU_SG_REL_ CCIOM SG_ 948 TotalFrontBellowTorqueRef 300;
BA_REL_ "GenSigFirstTimeoutTime" BU_SG_REL_ VCM SG_ 948 Rear1ClutchStatus 3000;
BA_REL_ "GenSigTimeoutTime" BU_SG_REL_ VCM SG_ 948 Rear1ClutchStatus 500;
BA_REL_ "GenSigFirstTimeoutTime" BU_SG_REL_ VCM SG_ 947 FPBRMMIStat_FPBRChangeAck 3000;
BA_REL_ "GenSigTimeoutTime" BU_SG_REL_ VCM SG_ 947 FPBRMMIStat_FPBRChangeAck 300;
BA_REL_ "GenSigFirstTimeoutTime" BU_SG_REL_ VCM SG_ 947 RelativeLevelRearAxleRight 3000;
BA_REL_ "GenSigTimeoutTime" BU_SG_REL_ VCM SG_ 947 RelativeLevelRearAxleRight 300;
BA_REL_ "GenSigFirstTimeoutTime" BU_SG_REL_ VCM SG_ 947 FPBRMMIStat_FPBRStatusInd 3000;
BA_REL_ "GenSigTimeoutTime" BU_SG_REL_ VCM SG_ 947 FPBRMMIStat_FPBRStatusInd 300;
BA_REL_ "GenSigFirstTimeoutTime" BU_SG_REL_ VCM SG_ 947 LiftAxle1LiftAllowed_Stat 3000;
BA_REL_ "GenSigTimeoutTime" BU_SG_REL_ VCM SG_ 947 LiftAxle1LiftAllowed_Stat 300;
BA_REL_ "GenSigFirstTimeoutTime" BU_SG_REL_ VCM SG_ 947 FrontLevRefCtrl_ShortPushCnt 3000;
BA_REL_ "GenSigTimeoutTime" BU_SG_REL_ VCM SG_ 947 FrontLevRefCtrl_ShortPushCnt 300;
BA_REL_ "GenSigFirstTimeoutTime" BU_SG_REL_ CCIOM SG_ 947 FrontLevRefCtrl_ShortPushCnt 3000;
BA_REL_ "GenSigTimeoutTime" BU_SG_REL_ CCIOM SG_ 947 FrontLevRefCtrl_ShortPushCnt 300;
BA_REL_ "GenSigFirstTimeoutTime" BU_SG_REL_ CCIOM SG_ 947 FrontLevRefCtrl_LevelRef 3000;
BA_REL_ "GenSigTimeoutTime" BU_SG_REL_ CCIOM SG_ 947 FrontLevRefCtrl_LevelRef 300;
BA_REL_ "GenSigFirstTimeoutTime" BU_SG_REL_ VCM SG_ 947 FrontLevRefCtrl_LevelRef 3000;
BA_REL_ "GenSigTimeoutTime" BU_SG_REL_ VCM SG_ 947 FrontLevRefCtrl_LevelRef 300;
BA_REL_ "GenSigFirstTimeoutTime" BU_SG_REL_ VCM SG_ 947 RelativeLevelRearAxleLeft 3000;
BA_REL_ "GenSigTimeoutTime" BU_SG_REL_ VCM SG_ 947 RelativeLevelRearAxleLeft 300;
BA_REL_ "GenSigFirstTimeoutTime" BU_SG_REL_ VCM SG_ 530 AirDumpStatus 3000;
BA_REL_ "GenSigTimeoutTime" BU_SG_REL_ VCM SG_ 530 AirDumpStatus 120;
BA_REL_ "GenSigFirstTimeoutTime" BU_SG_REL_ VCM SG_ 530 RearAxle2DiffLock_stat 3000;
BA_REL_ "GenSigTimeoutTime" BU_SG_REL_ VCM SG_ 530 RearAxle2DiffLock_stat 500;
BA_REL_ "GenSigFirstTimeoutTime" BU_SG_REL_ VCM SG_ 530 SWBrakeSwitch 3000;
BA_REL_ "GenSigTimeoutTime" BU_SG_REL_ VCM SG_ 530 SWBrakeSwitch 500;
BA_REL_ "GenSigFirstTimeoutTime" BU_SG_REL_ VCM SG_ 530 RearAxle1DiffLock_stat 3000;
BA_REL_ "GenSigTimeoutTime" BU_SG_REL_ VCM SG_ 530 RearAxle1DiffLock_stat 500;
BA_REL_ "GenSigFirstTimeoutTime" BU_SG_REL_ VCM SG_ 530 SupplyPressure 3000;
BA_REL_ "GenSigTimeoutTime" BU_SG_REL_ VCM SG_ 530 SupplyPressure 120;
BA_REL_ "GenSigFirstTimeoutTime" BU_SG_REL_ CCIOM SG_ 530 SupplyPressure 3000;
BA_REL_ "GenSigTimeoutTime" BU_SG_REL_ CCIOM SG_ 530 SupplyPressure 300;
BA_REL_ "GenSigFirstTimeoutTime" BU_SG_REL_ VCM SG_ 530 BackToDriveReqACK 3000;
BA_REL_ "GenSigTimeoutTime" BU_SG_REL_ VCM SG_ 530 BackToDriveReqACK 120;
BA_REL_ "GenSigFirstTimeoutTime" BU_SG_REL_ VCM SG_ 530 PitchAngleRef 3000;
BA_REL_ "GenSigTimeoutTime" BU_SG_REL_ VCM SG_ 530 PitchAngleRef 120;
BA_REL_ "GenSigFirstTimeoutTime" BU_SG_REL_ CCIOM SG_ 530 PitchAngleRef 3000;
BA_REL_ "GenSigTimeoutTime" BU_SG_REL_ CCIOM SG_ 530 PitchAngleRef 300;
BA_REL_ "GenSigFirstTimeoutTime" BU_SG_REL_ VCM SG_ 530 PitchAngle 3000;
BA_REL_ "GenSigTimeoutTime" BU_SG_REL_ VCM SG_ 530 PitchAngle 120;
BA_REL_ "GenSigFirstTimeoutTime" BU_SG_REL_ CCIOM SG_ 530 PitchAngle 3000;
BA_REL_ "GenSigTimeoutTime" BU_SG_REL_ CCIOM SG_ 530 PitchAngle 300;
BA_REL_ "GenSigFirstTimeoutTime" BU_SG_REL_ VCM SG_ 530 TrailerWithoutABS 3000;
BA_REL_ "GenSigTimeoutTime" BU_SG_REL_ VCM SG_ 530 TrailerWithoutABS 500;
BA_REL_ "GenSigFirstTimeoutTime" BU_SG_REL_ VCM SG_ 530 TrailerConnected 3000;
BA_REL_ "GenSigTimeoutTime" BU_SG_REL_ VCM SG_ 530 TrailerConnected 500;
BA_REL_ "GenSigFirstTimeoutTime" BU_SG_REL_ CCIOM SG_ 530 TrailerConnected 3000;
BA_REL_ "GenSigTimeoutTime" BU_SG_REL_ CCIOM SG_ 530 TrailerConnected 500;
BA_REL_ "GenSigFirstTimeoutTime" BU_SG_REL_ VCM SG_ 530 CentralRearDiffLock_stat 3000;
BA_REL_ "GenSigTimeoutTime" BU_SG_REL_ VCM SG_ 530 CentralRearDiffLock_stat 500;
BA_REL_ "GenSigFirstTimeoutTime" BU_SG_REL_ VCM SG_ 528 RollEndPositionStatus 3000;
BA_REL_ "GenSigTimeoutTime" BU_SG_REL_ VCM SG_ 528 RollEndPositionStatus 120;
BA_REL_ "GenSigFirstTimeoutTime" BU_SG_REL_ VCM SG_ 528 FrontFerryFunctionCmd 3000;
BA_REL_ "GenSigTimeoutTime" BU_SG_REL_ VCM SG_ 528 FrontFerryFunctionCmd 120;
BA_REL_ "GenSigFirstTimeoutTime" BU_SG_REL_ CCIOM SG_ 528 FrontFerryFunctionCmd 3000;
BA_REL_ "GenSigTimeoutTime" BU_SG_REL_ CCIOM SG_ 528 FrontFerryFunctionCmd 120;
BA_REL_ "GenSigFirstTimeoutTime" BU_SG_REL_ VCM SG_ 528 RideHeightFunctionStatus 3000;
BA_REL_ "GenSigTimeoutTime" BU_SG_REL_ VCM SG_ 528 RideHeightFunctionStatus 120;
BA_REL_ "GenSigFirstTimeoutTime" BU_SG_REL_ CCIOM SG_ 528 HeightControlMode 3000;
BA_REL_ "GenSigTimeoutTime" BU_SG_REL_ CCIOM SG_ 528 HeightControlMode 120;
BA_REL_ "GenSigFirstTimeoutTime" BU_SG_REL_ VCM SG_ 528 HeightControlMode 3000;
BA_REL_ "GenSigTimeoutTime" BU_SG_REL_ VCM SG_ 528 HeightControlMode 120;
BA_REL_ "GenSigFirstTimeoutTime" BU_SG_REL_ VCM SG_ 528 ECSShutdownCmd 3000;
BA_REL_ "GenSigTimeoutTime" BU_SG_REL_ VCM SG_ 528 ECSShutdownCmd 120;
BA_REL_ "GenSigFirstTimeoutTime" BU_SG_REL_ CCIOM SG_ 528 ECSShutdownCmd 3000;
BA_REL_ "GenSigTimeoutTime" BU_SG_REL_ CCIOM SG_ 528 ECSShutdownCmd 120;
BA_REL_ "GenSigFirstTimeoutTime" BU_SG_REL_ VCM SG_ 528 FerryFunctionStatus 3000;
BA_REL_ "GenSigTimeoutTime" BU_SG_REL_ VCM SG_ 528 FerryFunctionStatus 500;
BA_REL_ "GenSigFirstTimeoutTime" BU_SG_REL_ VCM SG_ 528 LevelControlInformation 3000;
BA_REL_ "GenSigTimeoutTime" BU_SG_REL_ VCM SG_ 528 LevelControlInformation 500;
BA_REL_ "GenSigFirstTimeoutTime" BU_SG_REL_ VCM SG_ 528 ChangeKneelACK 3000;
BA_REL_ "GenSigTimeoutTime" BU_SG_REL_ VCM SG_ 528 ChangeKneelACK 120;
BA_REL_ "GenSigFirstTimeoutTime" BU_SG_REL_ VCM SG_ 528 RearEndPositionStatus 3000;
BA_REL_ "GenSigTimeoutTime" BU_SG_REL_ VCM SG_ 528 RearEndPositionStatus 120;
BA_REL_ "GenSigFirstTimeoutTime" BU_SG_REL_ VCM SG_ 528 RampHeightOutsideTargetRange 3000;
BA_REL_ "GenSigTimeoutTime" BU_SG_REL_ VCM SG_ 528 RampHeightOutsideTargetRange 120;
BA_REL_ "GenSigFirstTimeoutTime" BU_SG_REL_ VCM SG_ 528 LoadDistributionFuncSelected 3000;
BA_REL_ "GenSigTimeoutTime" BU_SG_REL_ VCM SG_ 528 LoadDistributionFuncSelected 120;
BA_REL_ "GenSigFirstTimeoutTime" BU_SG_REL_ VCM SG_ 528 HeightAdjustmentAllowed 3000;
BA_REL_ "GenSigTimeoutTime" BU_SG_REL_ VCM SG_ 528 HeightAdjustmentAllowed 120;
BA_REL_ "GenSigFirstTimeoutTime" BU_SG_REL_ VCM SG_ 528 KneelingInformation 3000;
BA_REL_ "GenSigTimeoutTime" BU_SG_REL_ VCM SG_ 528 KneelingInformation 120;
BA_REL_ "GenSigFirstTimeoutTime" BU_SG_REL_ VCM SG_ 528 KneelingStatusHMI 3000;
BA_REL_ "GenSigTimeoutTime" BU_SG_REL_ VCM SG_ 528 KneelingStatusHMI 120;
BA_REL_ "GenSigFirstTimeoutTime" BU_SG_REL_ CCIOM SG_ 528 LiftAxle1PositionStatus 3000;
BA_REL_ "GenSigTimeoutTime" BU_SG_REL_ CCIOM SG_ 528 LiftAxle1PositionStatus 120;
BA_REL_ "GenSigFirstTimeoutTime" BU_SG_REL_ VCM SG_ 528 LiftAxle1PositionStatus 3000;
BA_REL_ "GenSigTimeoutTime" BU_SG_REL_ VCM SG_ 528 LiftAxle1PositionStatus 120;
BA_REL_ "GenSigFirstTimeoutTime" BU_SG_REL_ CCIOM SG_ 528 VehicleDynamicSuspProhibitStat 3000;
BA_REL_ "GenSigTimeoutTime" BU_SG_REL_ CCIOM SG_ 528 VehicleDynamicSuspProhibitStat 120;
BA_REL_ "GenSigFirstTimeoutTime" BU_SG_REL_ VCM SG_ 528 VehicleDynamicSuspProhibitStat 3000;
BA_REL_ "GenSigTimeoutTime" BU_SG_REL_ VCM SG_ 528 VehicleDynamicSuspProhibitStat 120;
BA_REL_ "GenSigFirstTimeoutTime" BU_SG_REL_ VCM SG_ 528 LiftAxle2PositionStatus 3000;
BA_REL_ "GenSigTimeoutTime" BU_SG_REL_ VCM SG_ 528 LiftAxle2PositionStatus 120;
BA_REL_ "GenSigFirstTimeoutTime" BU_SG_REL_ VCM SG_ 528 RideHeightStatus 3000;
BA_REL_ "GenSigTimeoutTime" BU_SG_REL_ VCM SG_ 528 RideHeightStatus 120;
BA_REL_ "GenSigFirstTimeoutTime" BU_SG_REL_ VCM SG_ 528 DirInd_Rear_Status 3000;
BA_REL_ "GenSigTimeoutTime" BU_SG_REL_ VCM SG_ 528 DirInd_Rear_Status 120;
BA_REL_ "GenSigFirstTimeoutTime" BU_SG_REL_ CCIOM SG_ 517 FrontProhibitControlRequest 3000;
BA_REL_ "GenSigTimeoutTime" BU_SG_REL_ CCIOM SG_ 517 FrontProhibitControlRequest 120;
BA_REL_ "GenSigFirstTimeoutTime" BU_SG_REL_ VCM SG_ 517 FrontProhibitControlRequest 3000;
BA_REL_ "GenSigTimeoutTime" BU_SG_REL_ VCM SG_ 517 FrontProhibitControlRequest 120;
BA_REL_ "GenSigFirstTimeoutTime" BU_SG_REL_ VCM SG_ 517 RampLevelStorageAck 3000;
BA_REL_ "GenSigTimeoutTime" BU_SG_REL_ VCM SG_ 517 RampLevelStorageAck 120;
BA_REL_ "GenSigFirstTimeoutTime" BU_SG_REL_ VCM SG_ 517 FrontLimpHomeCmd 3000;
BA_REL_ "GenSigTimeoutTime" BU_SG_REL_ VCM SG_ 517 FrontLimpHomeCmd 120;
BA_REL_ "GenSigFirstTimeoutTime" BU_SG_REL_ CCIOM SG_ 517 FrontLimpHomeCmd 3000;
BA_REL_ "GenSigTimeoutTime" BU_SG_REL_ CCIOM SG_ 517 FrontLimpHomeCmd 120;
BA_REL_ "GenSigFirstTimeoutTime" BU_SG_REL_ VCM SG_ 517 LiftingControlModeRearAxle 3000;
BA_REL_ "GenSigTimeoutTime" BU_SG_REL_ VCM SG_ 517 LiftingControlModeRearAxle 120;
BA_REL_ "GenSigFirstTimeoutTime" BU_SG_REL_ VCM SG_ 517 LoadDistributionChangeACK 3000;
BA_REL_ "GenSigTimeoutTime" BU_SG_REL_ VCM SG_ 517 LoadDistributionChangeACK 120;
BA_REL_ "GenSigFirstTimeoutTime" BU_SG_REL_ VCM SG_ 517 ECSStandbyAllowed 3000;
BA_REL_ "GenSigTimeoutTime" BU_SG_REL_ VCM SG_ 517 ECSStandbyAllowed 120;
BA_REL_ "GenSigFirstTimeoutTime" BU_SG_REL_ VCM SG_ 517 LiftAxle2LiftFuncSelected 3000;
BA_REL_ "GenSigTimeoutTime" BU_SG_REL_ VCM SG_ 517 LiftAxle2LiftFuncSelected 120;
BA_REL_ "GenSigFirstTimeoutTime" BU_SG_REL_ VCM SG_ 517 LiftAxle2UpRequestACK 3000;
BA_REL_ "GenSigTimeoutTime" BU_SG_REL_ VCM SG_ 517 LiftAxle2UpRequestACK 120;
BA_REL_ "GenSigFirstTimeoutTime" BU_SG_REL_ VCM SG_ 517 ProhibitControlStatus 3000;
BA_REL_ "GenSigTimeoutTime" BU_SG_REL_ VCM SG_ 517 ProhibitControlStatus 120;
BA_REL_ "GenSigFirstTimeoutTime" BU_SG_REL_ VCM SG_ 517 RampLevelStatus 3000;
BA_REL_ "GenSigTimeoutTime" BU_SG_REL_ VCM SG_ 517 RampLevelStatus 120;
BA_REL_ "GenSigFirstTimeoutTime" BU_SG_REL_ VCM SG_ 517 StopLevelChangeAck 3000;
BA_REL_ "GenSigTimeoutTime" BU_SG_REL_ VCM SG_ 517 StopLevelChangeAck 120;
BA_REL_ "GenSigFirstTimeoutTime" BU_SG_REL_ VCM SG_ 517 LiftAxle2LowerACK 3000;
BA_REL_ "GenSigTimeoutTime" BU_SG_REL_ VCM SG_ 517 LiftAxle2LowerACK 120;
BA_REL_ "GenSigFirstTimeoutTime" BU_SG_REL_ VCM SG_ 517 RideHeightStorageAck 3000;
BA_REL_ "GenSigTimeoutTime" BU_SG_REL_ VCM SG_ 517 RideHeightStorageAck 120;
BA_REL_ "GenSigFirstTimeoutTime" BU_SG_REL_ VCM SG_ 517 FrontParkBrakeOverrideCommand 3000;
BA_REL_ "GenSigTimeoutTime" BU_SG_REL_ VCM SG_ 517 FrontParkBrakeOverrideCommand 120;
BA_REL_ "GenSigFirstTimeoutTime" BU_SG_REL_ VCM SG_ 517 RideHeightOutsideTargetRange 3000;
BA_REL_ "GenSigTimeoutTime" BU_SG_REL_ VCM SG_ 517 RideHeightOutsideTargetRange 120;
BA_REL_ "GenSigFirstTimeoutTime" BU_SG_REL_ VCM SG_ 517 DisableMechFaultDctnFr_rqst 3000;
BA_REL_ "GenSigTimeoutTime" BU_SG_REL_ VCM SG_ 517 DisableMechFaultDctnFr_rqst 120;
BA_REL_ "GenSigFirstTimeoutTime" BU_SG_REL_ CCIOM SG_ 517 DisableMechFaultDctnFr_rqst 3000;
BA_REL_ "GenSigTimeoutTime" BU_SG_REL_ CCIOM SG_ 517 DisableMechFaultDctnFr_rqst 120;
BA_REL_ "GenSigFirstTimeoutTime" BU_SG_REL_ VCM SG_ 517 BrakePressureSensorDemand 3000;
BA_REL_ "GenSigTimeoutTime" BU_SG_REL_ VCM SG_ 517 BrakePressureSensorDemand 500;
BA_REL_ "GenSigFirstTimeoutTime" BU_SG_REL_ VCM SG_ 517 FogLamp_Rear_Status 3000;
BA_REL_ "GenSigTimeoutTime" BU_SG_REL_ VCM SG_ 517 FogLamp_Rear_Status 120;
BA_REL_ "GenSigFirstTimeoutTime" BU_SG_REL_ VCM SG_ 517 LiftingControlModeFrontAxle 3000;
BA_REL_ "GenSigTimeoutTime" BU_SG_REL_ VCM SG_ 517 LiftingControlModeFrontAxle 120;
BA_REL_ "GenSigFirstTimeoutTime" BU_SG_REL_ VCM SG_ 517 LiftAxle1UpRequestACK 3000;
BA_REL_ "GenSigTimeoutTime" BU_SG_REL_ VCM SG_ 517 LiftAxle1UpRequestACK 120;
BA_REL_ "GenSigFirstTimeoutTime" BU_SG_REL_ VCM SG_ 517 LiftAxle1LiftFuncSelected 3000;
BA_REL_ "GenSigTimeoutTime" BU_SG_REL_ VCM SG_ 517 LiftAxle1LiftFuncSelected 120;
BA_REL_ "GenSigFirstTimeoutTime" BU_SG_REL_ VCM SG_ 517 RearAxleInBumperRange 3000;
BA_REL_ "GenSigTimeoutTime" BU_SG_REL_ VCM SG_ 517 RearAxleInBumperRange 500;
BA_REL_ "GenSigFirstTimeoutTime" BU_SG_REL_ VCM SG_ 1339 HeadlampFan_stat 6000;
BA_REL_ "GenSigTimeoutTime" BU_SG_REL_ VCM SG_ 1339 HeadlampFan_stat 1500;
BA_REL_ "GenSigFirstTimeoutTime" BU_SG_REL_ VCM SG_ 1339 FrontConspicLamp_stat_HiRight 6000;
BA_REL_ "GenSigTimeoutTime" BU_SG_REL_ VCM SG_ 1339 FrontConspicLamp_stat_HiRight 1500;
BA_REL_ "GenSigFirstTimeoutTime" BU_SG_REL_ VCM SG_ 1339 AmbientAirTemperature2 6000;
BA_REL_ "GenSigTimeoutTime" BU_SG_REL_ VCM SG_ 1339 AmbientAirTemperature2 1500;
BA_REL_ "GenSigFirstTimeoutTime" BU_SG_REL_ VCM SG_ 1339 FrontConspicLamp_stat_LoRight 6000;
BA_REL_ "GenSigTimeoutTime" BU_SG_REL_ VCM SG_ 1339 FrontConspicLamp_stat_LoRight 1500;
BA_REL_ "GenSigFirstTimeoutTime" BU_SG_REL_ VCM SG_ 1339 FrontConspicLamp_stat_HiLeft 6000;
BA_REL_ "GenSigTimeoutTime" BU_SG_REL_ VCM SG_ 1339 FrontConspicLamp_stat_HiLeft 1500;
BA_REL_ "GenSigFirstTimeoutTime" BU_SG_REL_ VCM SG_ 1339 FrontConspicLamp_stat_LoLeft 6000;
BA_REL_ "GenSigTimeoutTime" BU_SG_REL_ VCM SG_ 1339 FrontConspicLamp_stat_LoLeft 1500;
BA_REL_ "GenSigFirstTimeoutTime" BU_SG_REL_ VCM SG_ 1243 MainBeamLEDStatusRight 3000;
BA_REL_ "GenSigTimeoutTime" BU_SG_REL_ VCM SG_ 1243 MainBeamLEDStatusRight 600;
BA_REL_ "GenSigFirstTimeoutTime" BU_SG_REL_ VCM SG_ 1243 DeicingBulb_Stat 3000;
BA_REL_ "GenSigTimeoutTime" BU_SG_REL_ VCM SG_ 1243 DeicingBulb_Stat 600;
BA_REL_ "GenSigFirstTimeoutTime" BU_SG_REL_ VCM SG_ 1243 DeicingFunction_Stat 3000;
BA_REL_ "GenSigTimeoutTime" BU_SG_REL_ VCM SG_ 1243 DeicingFunction_Stat 600;
BA_REL_ "GenSigFirstTimeoutTime" BU_SG_REL_ VCM SG_ 1243 MainBeamLEDStatusLeft 3000;
BA_REL_ "GenSigTimeoutTime" BU_SG_REL_ VCM SG_ 1243 MainBeamLEDStatusLeft 600;
BA_REL_ "GenSigFirstTimeoutTime" BU_SG_REL_ VCM SG_ 952 DRLLamp_stat 3000;
BA_REL_ "GenSigTimeoutTime" BU_SG_REL_ VCM SG_ 952 DRLLamp_stat 300;
BA_REL_ "GenSigFirstTimeoutTime" BU_SG_REL_ VCM SG_ 952 FogLamp_Front_Status 3000;
BA_REL_ "GenSigTimeoutTime" BU_SG_REL_ VCM SG_ 952 FogLamp_Front_Status 300;
BA_REL_ "GenSigFirstTimeoutTime" BU_SG_REL_ VCM SG_ 952 DirIndSideLamp1_stat 3000;
BA_REL_ "GenSigTimeoutTime" BU_SG_REL_ VCM SG_ 952 DirIndSideLamp1_stat 300;
BA_REL_ "GenSigFirstTimeoutTime" BU_SG_REL_ VCM SG_ 952 PositionLightLamp_stat 3000;
BA_REL_ "GenSigTimeoutTime" BU_SG_REL_ VCM SG_ 952 PositionLightLamp_stat 300;
BA_REL_ "GenSigFirstTimeoutTime" BU_SG_REL_ VCM SG_ 952 DippedBeamLamp_stat 3000;
BA_REL_ "GenSigTimeoutTime" BU_SG_REL_ VCM SG_ 952 DippedBeamLamp_stat 300;
BA_REL_ "GenSigFirstTimeoutTime" BU_SG_REL_ VCM SG_ 952 MainBeamLamp_stat 3000;
BA_REL_ "GenSigTimeoutTime" BU_SG_REL_ VCM SG_ 952 MainBeamLamp_stat 300;
BA_REL_ "GenSigFirstTimeoutTime" BU_SG_REL_ VCM SG_ 952 StaticCornerLightLamp_stat 3000;
BA_REL_ "GenSigTimeoutTime" BU_SG_REL_ VCM SG_ 952 StaticCornerLightLamp_stat 300;
BA_REL_ "GenSigFirstTimeoutTime" BU_SG_REL_ VCM SG_ 952 AuxLamp_Front_Status 3000;
BA_REL_ "GenSigTimeoutTime" BU_SG_REL_ VCM SG_ 952 AuxLamp_Front_Status 300;
BA_REL_ "GenSigFirstTimeoutTime" BU_SG_REL_ VCM SG_ 952 AuxFogLightLamp_stat 3000;
BA_REL_ "GenSigTimeoutTime" BU_SG_REL_ VCM SG_ 952 AuxFogLightLamp_stat 300;
BA_REL_ "GenSigFirstTimeoutTime" BU_SG_REL_ VCM SG_ 952 ExtraMainBeamLamp_stat 3000;
BA_REL_ "GenSigTimeoutTime" BU_SG_REL_ VCM SG_ 952 ExtraMainBeamLamp_stat 300;
BA_REL_ "GenSigFirstTimeoutTime" BU_SG_REL_ VCM SG_ 952 AmbientAirTemperature1 3000;
BA_REL_ "GenSigTimeoutTime" BU_SG_REL_ VCM SG_ 952 AmbientAirTemperature1 300;
BA_REL_ "GenSigFirstTimeoutTime" BU_SG_REL_ VCM SG_ 952 FogLightFrontLamp_stat 3000;
BA_REL_ "GenSigTimeoutTime" BU_SG_REL_ VCM SG_ 952 FogLightFrontLamp_stat 300;
BA_REL_ "GenSigFirstTimeoutTime" BU_SG_REL_ VCM SG_ 952 DirInd_Front_Status 3000;
BA_REL_ "GenSigTimeoutTime" BU_SG_REL_ VCM SG_ 952 DirInd_Front_Status 300;
BA_REL_ "GenSigFirstTimeoutTime" BU_SG_REL_ VCM SG_ 952 ChassiInstepLightsLamp_stat 3000;
BA_REL_ "GenSigTimeoutTime" BU_SG_REL_ VCM SG_ 952 ChassiInstepLightsLamp_stat 300;
BA_REL_ "GenSigFirstTimeoutTime" BU_SG_REL_ VCM SG_ 952 WasherFluidLevel 3000;
BA_REL_ "GenSigTimeoutTime" BU_SG_REL_ VCM SG_ 952 WasherFluidLevel 300;
BA_REL_ "GenSigFirstTimeoutTime" BU_SG_REL_ RCIOM SG_ 1232 TrailerCommunicationType 3000;
BA_REL_ "GenSigTimeoutTime" BU_SG_REL_ RCIOM SG_ 1232 TrailerCommunicationType 600;
BA_REL_ "GenSigFirstTimeoutTime" BU_SG_REL_ RCIOM SG_ 396 ThrdRrDriveAxLeftWheelSpeed 3000;
BA_REL_ "GenSigTimeoutTime" BU_SG_REL_ RCIOM SG_ 396 ThrdRrDriveAxLeftWheelSpeed 60;
BA_REL_ "GenSigFirstTimeoutTime" BU_SG_REL_ RCIOM SG_ 396 ThrdRrDriveAxRightWheelSpeed 3000;
BA_REL_ "GenSigTimeoutTime" BU_SG_REL_ RCIOM SG_ 396 ThrdRrDriveAxRightWheelSpeed 60;
BA_REL_ "GenSigFirstTimeoutTime" BU_SG_REL_ RCIOM SG_ 395 SteeringWheelAngle 3000;
BA_REL_ "GenSigTimeoutTime" BU_SG_REL_ RCIOM SG_ 395 SteeringWheelAngle 500;
BA_REL_ "GenSigFirstTimeoutTime" BU_SG_REL_ CCIOM SG_ 394 ScndRrDriveAxleLeftWheelSpeed 3000;
BA_REL_ "GenSigTimeoutTime" BU_SG_REL_ CCIOM SG_ 394 ScndRrDriveAxleLeftWheelSpeed 60;
BA_REL_ "GenSigFirstTimeoutTime" BU_SG_REL_ RCIOM SG_ 394 ScndRrDriveAxleLeftWheelSpeed 3000;
BA_REL_ "GenSigTimeoutTime" BU_SG_REL_ RCIOM SG_ 394 ScndRrDriveAxleLeftWheelSpeed 60;
BA_REL_ "GenSigFirstTimeoutTime" BU_SG_REL_ RCIOM SG_ 394 ScndRrDriveAxleRightWheelSpeed 3000;
BA_REL_ "GenSigTimeoutTime" BU_SG_REL_ RCIOM SG_ 394 ScndRrDriveAxleRightWheelSpeed 60;
BA_REL_ "GenSigFirstTimeoutTime" BU_SG_REL_ CCIOM SG_ 394 ScndRrDriveAxleRightWheelSpeed 3000;
BA_REL_ "GenSigTimeoutTime" BU_SG_REL_ CCIOM SG_ 394 ScndRrDriveAxleRightWheelSpeed 60;
BA_REL_ "GenSigFirstTimeoutTime" BU_SG_REL_ RCIOM SG_ 386 LateralAcceleration 3000;
BA_REL_ "GenSigTimeoutTime" BU_SG_REL_ RCIOM SG_ 386 LateralAcceleration 60;
BA_REL_ "GenSigFirstTimeoutTime" BU_SG_REL_ RCIOM SG_ 386 VDCBrakeLightRequest 3000;
BA_REL_ "GenSigTimeoutTime" BU_SG_REL_ RCIOM SG_ 386 VDCBrakeLightRequest 60;
BA_REL_ "GenSigFirstTimeoutTime" BU_SG_REL_ RCIOM SG_ 386 EBSBrakeSwitch 3000;
BA_REL_ "GenSigTimeoutTime" BU_SG_REL_ RCIOM SG_ 386 EBSBrakeSwitch 60;
BA_REL_ "GenSigFirstTimeoutTime" BU_SG_REL_ RCIOM SG_ 386 BrakeLightActivationRequest 3000;
BA_REL_ "GenSigTimeoutTime" BU_SG_REL_ RCIOM SG_ 386 BrakeLightActivationRequest 60;
BA_REL_ "GenSigFirstTimeoutTime" BU_SG_REL_ RCIOM SG_ 386 LongitudinalAcceleration 3000;
BA_REL_ "GenSigTimeoutTime" BU_SG_REL_ RCIOM SG_ 386 LongitudinalAcceleration 60;
BA_REL_ "GenSigFirstTimeoutTime" BU_SG_REL_ RCIOM SG_ 824 Trailer1TractionHelp 3000;
BA_REL_ "GenSigTimeoutTime" BU_SG_REL_ RCIOM SG_ 824 Trailer1TractionHelp 180;
BA_REL_ "GenSigFirstTimeoutTime" BU_SG_REL_ RCIOM SG_ 824 TrailerBrake_Stat 3000;
BA_REL_ "GenSigTimeoutTime" BU_SG_REL_ RCIOM SG_ 824 TrailerBrake_Stat 180;
BA_REL_ "GenSigFirstTimeoutTime" BU_SG_REL_ CCIOM SG_ 824 SplitBoxDiffLockActvnFuncReq 3000;
BA_REL_ "GenSigTimeoutTime" BU_SG_REL_ CCIOM SG_ 824 SplitBoxDiffLockActvnFuncReq 180;
BA_REL_ "GenSigFirstTimeoutTime" BU_SG_REL_ CCIOM SG_ 824 BrakingSystemPressureLim_rqst 3000;
BA_REL_ "GenSigTimeoutTime" BU_SG_REL_ CCIOM SG_ 824 BrakingSystemPressureLim_rqst 180;
BA_REL_ "GenSigFirstTimeoutTime" BU_SG_REL_ RCIOM SG_ 824 TagLiftAxleLoweringInhibit 3000;
BA_REL_ "GenSigTimeoutTime" BU_SG_REL_ RCIOM SG_ 824 TagLiftAxleLoweringInhibit 180;
BA_REL_ "GenSigFirstTimeoutTime" BU_SG_REL_ RCIOM SG_ 824 ScndRrAxlDiffLckActvnFuncReq 3000;
BA_REL_ "GenSigTimeoutTime" BU_SG_REL_ RCIOM SG_ 824 ScndRrAxlDiffLckActvnFuncReq 180;
BA_REL_ "GenSigFirstTimeoutTime" BU_SG_REL_ RCIOM SG_ 824 Trailer1LiftAxle1Pos 3000;
BA_REL_ "GenSigTimeoutTime" BU_SG_REL_ RCIOM SG_ 824 Trailer1LiftAxle1Pos 180;
BA_REL_ "GenSigFirstTimeoutTime" BU_SG_REL_ RCIOM SG_ 824 PusherLiftAxleLoweringInhibit 3000;
BA_REL_ "GenSigTimeoutTime" BU_SG_REL_ RCIOM SG_ 824 PusherLiftAxleLoweringInhibit 180;
BA_REL_ "GenSigFirstTimeoutTime" BU_SG_REL_ RCIOM SG_ 824 StretchBrake_Stat 3000;
BA_REL_ "GenSigTimeoutTime" BU_SG_REL_ RCIOM SG_ 824 StretchBrake_Stat 180;
BA_REL_ "GenSigFirstTimeoutTime" BU_SG_REL_ RCIOM SG_ 824 TrailersConnected 3000;
BA_REL_ "GenSigTimeoutTime" BU_SG_REL_ RCIOM SG_ 824 TrailersConnected 180;
BA_REL_ "GenSigFirstTimeoutTime" BU_SG_REL_ RCIOM SG_ 824 Trailer1LiftAxle2Pos 3000;
BA_REL_ "GenSigTimeoutTime" BU_SG_REL_ RCIOM SG_ 824 Trailer1LiftAxle2Pos 180;
BA_REL_ "GenSigFirstTimeoutTime" BU_SG_REL_ RCIOM SG_ 824 TrailerEBSAmberWarning 3000;
BA_REL_ "GenSigTimeoutTime" BU_SG_REL_ RCIOM SG_ 824 TrailerEBSAmberWarning 180;
BA_REL_ "GenSigFirstTimeoutTime" BU_SG_REL_ RCIOM SG_ 824 FrontParkBrakeOverrideStatus 3000;
BA_REL_ "GenSigTimeoutTime" BU_SG_REL_ RCIOM SG_ 824 FrontParkBrakeOverrideStatus 180;
BA_REL_ "GenSigFirstTimeoutTime" BU_SG_REL_ RCIOM SG_ 516 EASPusherLiftAxleLoweringInhib 3000;
BA_REL_ "GenSigTimeoutTime" BU_SG_REL_ RCIOM SG_ 516 EASPusherLiftAxleLoweringInhib 120;
BA_REL_ "GenSigFirstTimeoutTime" BU_SG_REL_ VCM SG_ 1372 OpLevelItem11 12000;
BA_REL_ "GenSigTimeoutTime" BU_SG_REL_ VCM SG_ 1372 OpLevelItem11 3000;
BA_REL_ "GenSigFirstTimeoutTime" BU_SG_REL_ VCM SG_ 1372 OpLevelItem14 12000;
BA_REL_ "GenSigTimeoutTime" BU_SG_REL_ VCM SG_ 1372 OpLevelItem14 3000;
BA_REL_ "GenSigFirstTimeoutTime" BU_SG_REL_ VCM SG_ 1372 OpLevelItem12 12000;
BA_REL_ "GenSigTimeoutTime" BU_SG_REL_ VCM SG_ 1372 OpLevelItem12 3000;
BA_REL_ "GenSigFirstTimeoutTime" BU_SG_REL_ VCM SG_ 1372 OpLevelItem15 12000;
BA_REL_ "GenSigTimeoutTime" BU_SG_REL_ VCM SG_ 1372 OpLevelItem15 3000;
BA_REL_ "GenSigFirstTimeoutTime" BU_SG_REL_ VCM SG_ 1372 OpLevelItem13 12000;
BA_REL_ "GenSigTimeoutTime" BU_SG_REL_ VCM SG_ 1372 OpLevelItem13 3000;
BA_REL_ "GenSigFirstTimeoutTime" BU_SG_REL_ VCM SG_ 1371 OpLevelItem1 12000;
BA_REL_ "GenSigTimeoutTime" BU_SG_REL_ VCM SG_ 1371 OpLevelItem1 3000;
BA_REL_ "GenSigFirstTimeoutTime" BU_SG_REL_ VCM SG_ 1371 OpLevelItem8 12000;
BA_REL_ "GenSigTimeoutTime" BU_SG_REL_ VCM SG_ 1371 OpLevelItem8 3000;
BA_REL_ "GenSigFirstTimeoutTime" BU_SG_REL_ VCM SG_ 1371 OpLevelItem5 12000;
BA_REL_ "GenSigTimeoutTime" BU_SG_REL_ VCM SG_ 1371 OpLevelItem5 3000;
BA_REL_ "GenSigFirstTimeoutTime" BU_SG_REL_ VCM SG_ 1371 OpLevelItem6 12000;
BA_REL_ "GenSigTimeoutTime" BU_SG_REL_ VCM SG_ 1371 OpLevelItem6 3000;
BA_REL_ "GenSigFirstTimeoutTime" BU_SG_REL_ VCM SG_ 1371 OpLevelItem10 12000;
BA_REL_ "GenSigTimeoutTime" BU_SG_REL_ VCM SG_ 1371 OpLevelItem10 3000;
BA_REL_ "GenSigFirstTimeoutTime" BU_SG_REL_ VCM SG_ 1371 OpLevelItem7 12000;
BA_REL_ "GenSigTimeoutTime" BU_SG_REL_ VCM SG_ 1371 OpLevelItem7 3000;
BA_REL_ "GenSigFirstTimeoutTime" BU_SG_REL_ VCM SG_ 1371 OpLevelItem9 12000;
BA_REL_ "GenSigTimeoutTime" BU_SG_REL_ VCM SG_ 1371 OpLevelItem9 3000;
BA_REL_ "GenSigFirstTimeoutTime" BU_SG_REL_ VCM SG_ 1371 OpLevelItem4 12000;
BA_REL_ "GenSigTimeoutTime" BU_SG_REL_ VCM SG_ 1371 OpLevelItem4 3000;
BA_REL_ "GenSigFirstTimeoutTime" BU_SG_REL_ VCM SG_ 1362 Cur_EnergySetting 12000;
BA_REL_ "GenSigTimeoutTime" BU_SG_REL_ VCM SG_ 1362 Cur_EnergySetting 3000;
BA_REL_ "GenSigFirstTimeoutTime" BU_SG_REL_ VCM SG_ 1362 Cur_LG5CutoffValue 12000;
BA_REL_ "GenSigTimeoutTime" BU_SG_REL_ VCM SG_ 1362 Cur_LG5CutoffValue 3000;
BA_REL_ "GenSigFirstTimeoutTime" BU_SG_REL_ VCM SG_ 1362 Cur_LG6CutoffValue 12000;
BA_REL_ "GenSigTimeoutTime" BU_SG_REL_ VCM SG_ 1362 Cur_LG6CutoffValue 3000;
BA_REL_ "GenSigFirstTimeoutTime" BU_SG_REL_ VCM SG_ 1362 Cur_LG2CutoffValue 12000;
BA_REL_ "GenSigTimeoutTime" BU_SG_REL_ VCM SG_ 1362 Cur_LG2CutoffValue 3000;
BA_REL_ "GenSigFirstTimeoutTime" BU_SG_REL_ VCM SG_ 1362 Cur_LG1CutoffValue 12000;
BA_REL_ "GenSigTimeoutTime" BU_SG_REL_ VCM SG_ 1362 Cur_LG1CutoffValue 3000;
BA_REL_ "GenSigFirstTimeoutTime" BU_SG_REL_ VCM SG_ 1362 Cur_LG4CutoffValue 12000;
BA_REL_ "GenSigTimeoutTime" BU_SG_REL_ VCM SG_ 1362 Cur_LG4CutoffValue 3000;
BA_REL_ "GenSigFirstTimeoutTime" BU_SG_REL_ VCM SG_ 1362 Cur_LG3CutoffValue 12000;
BA_REL_ "GenSigTimeoutTime" BU_SG_REL_ VCM SG_ 1362 Cur_LG3CutoffValue 3000;
BA_REL_ "GenSigFirstTimeoutTime" BU_SG_REL_ VCM SG_ 1444 CrankDiagInfo4_1 24000;
BA_REL_ "GenSigTimeoutTime" BU_SG_REL_ VCM SG_ 1444 CrankDiagInfo4_1 6000;
BA_REL_ "GenSigFirstTimeoutTime" BU_SG_REL_ VCM SG_ 1444 CrankDiagInfo3_1 24000;
BA_REL_ "GenSigTimeoutTime" BU_SG_REL_ VCM SG_ 1444 CrankDiagInfo3_1 6000;
BA_REL_ "GenSigFirstTimeoutTime" BU_SG_REL_ VCM SG_ 1444 BatteryCapacityGrpAck_Pos3 24000;
BA_REL_ "GenSigTimeoutTime" BU_SG_REL_ VCM SG_ 1444 BatteryCapacityGrpAck_Pos3 6000;
BA_REL_ "GenSigFirstTimeoutTime" BU_SG_REL_ VCM SG_ 1444 CrankDiagInfo2_1 24000;
BA_REL_ "GenSigTimeoutTime" BU_SG_REL_ VCM SG_ 1444 CrankDiagInfo2_1 6000;
BA_REL_ "GenSigFirstTimeoutTime" BU_SG_REL_ VCM SG_ 1444 BatteryCapacityGrpAck_Pos2 24000;
BA_REL_ "GenSigTimeoutTime" BU_SG_REL_ VCM SG_ 1444 BatteryCapacityGrpAck_Pos2 6000;
BA_REL_ "GenSigFirstTimeoutTime" BU_SG_REL_ VCM SG_ 1444 BatteryCapacityGrpAck_Pos1 24000;
BA_REL_ "GenSigTimeoutTime" BU_SG_REL_ VCM SG_ 1444 BatteryCapacityGrpAck_Pos1 6000;
BA_REL_ "GenSigFirstTimeoutTime" BU_SG_REL_ VCM SG_ 1444 CrankDiagInfo1_1 24000;
BA_REL_ "GenSigTimeoutTime" BU_SG_REL_ VCM SG_ 1444 CrankDiagInfo1_1 6000;
BA_REL_ "GenSigFirstTimeoutTime" BU_SG_REL_ VCM SG_ 1471 BatterySOHCapa1_1 24000;
BA_REL_ "GenSigTimeoutTime" BU_SG_REL_ VCM SG_ 1471 BatterySOHCapa1_1 6000;
BA_REL_ "GenSigFirstTimeoutTime" BU_SG_REL_ VCM SG_ 1471 BatterySOCTrustLevel_stat1_1 24000;
BA_REL_ "GenSigTimeoutTime" BU_SG_REL_ VCM SG_ 1471 BatterySOCTrustLevel_stat1_1 6000;
BA_REL_ "GenSigFirstTimeoutTime" BU_SG_REL_ VCM SG_ 1471 EndOfDischargeStatus1_1 24000;
BA_REL_ "GenSigTimeoutTime" BU_SG_REL_ VCM SG_ 1471 EndOfDischargeStatus1_1 6000;
BA_REL_ "GenSigFirstTimeoutTime" BU_SG_REL_ VCM SG_ 1471 DeepDischargestatus_1 24000;
BA_REL_ "GenSigTimeoutTime" BU_SG_REL_ VCM SG_ 1471 DeepDischargestatus_1 6000;
BA_REL_ "GenSigFirstTimeoutTime" BU_SG_REL_ VCM SG_ 1471 BatteryEndOfCharge 24000;
BA_REL_ "GenSigTimeoutTime" BU_SG_REL_ VCM SG_ 1471 BatteryEndOfCharge 6000;
BA_REL_ "GenSigFirstTimeoutTime" BU_SG_REL_ VCM SG_ 1471 BatteryExchangeDetect_1 24000;
BA_REL_ "GenSigTimeoutTime" BU_SG_REL_ VCM SG_ 1471 BatteryExchangeDetect_1 6000;
BA_REL_ "GenSigFirstTimeoutTime" BU_SG_REL_ VCM SG_ 1471 BatterySOHTrustLevel_stat1_1 24000;
BA_REL_ "GenSigTimeoutTime" BU_SG_REL_ VCM SG_ 1471 BatterySOHTrustLevel_stat1_1 6000;
BA_REL_ "GenSigFirstTimeoutTime" BU_SG_REL_ VCM SG_ 1471 Endofchargestatus1_1 24000;
BA_REL_ "GenSigTimeoutTime" BU_SG_REL_ VCM SG_ 1471 Endofchargestatus1_1 6000;
BA_REL_ "GenSigFirstTimeoutTime" BU_SG_REL_ VCM SG_ 1471 BatterySOHPowerTrustLevel1_1 24000;
BA_REL_ "GenSigTimeoutTime" BU_SG_REL_ VCM SG_ 1471 BatterySOHPowerTrustLevel1_1 6000;
BA_REL_ "GenSigFirstTimeoutTime" BU_SG_REL_ VCM SG_ 1471 BatteryTempCo_1 24000;
BA_REL_ "GenSigTimeoutTime" BU_SG_REL_ VCM SG_ 1471 BatteryTempCo_1 6000;
BA_REL_ "GenSigFirstTimeoutTime" BU_SG_REL_ VCM SG_ 1471 BatterySOHPower1_1 24000;
BA_REL_ "GenSigTimeoutTime" BU_SG_REL_ VCM SG_ 1471 BatterySOHPower1_1 6000;
BA_REL_ "GenSigFirstTimeoutTime" BU_SG_REL_ VCM SG_ 1471 BatteryReconnectionDetect_1 24000;
BA_REL_ "GenSigTimeoutTime" BU_SG_REL_ VCM SG_ 1471 BatteryReconnectionDetect_1 6000;
BA_REL_ "GenSigFirstTimeoutTime" BU_SG_REL_ VCM SG_ 1471 BatterySoCcrankLimit1_1 24000;
BA_REL_ "GenSigTimeoutTime" BU_SG_REL_ VCM SG_ 1471 BatterySoCcrankLimit1_1 6000;
BA_REL_ "GenSigFirstTimeoutTime" BU_SG_REL_ VCM SG_ 1469 WhCounterCharge_1 24000;
BA_REL_ "GenSigTimeoutTime" BU_SG_REL_ VCM SG_ 1469 WhCounterCharge_1 6000;
BA_REL_ "GenSigFirstTimeoutTime" BU_SG_REL_ VCM SG_ 1469 HighCurrentIR1_1 24000;
BA_REL_ "GenSigTimeoutTime" BU_SG_REL_ VCM SG_ 1469 HighCurrentIR1_1 6000;
BA_REL_ "GenSigFirstTimeoutTime" BU_SG_REL_ VCM SG_ 1469 WhCounterDischarge_1 24000;
BA_REL_ "GenSigTimeoutTime" BU_SG_REL_ VCM SG_ 1469 WhCounterDischarge_1 6000;
BA_REL_ "GenSigFirstTimeoutTime" BU_SG_REL_ VCM SG_ 1467 WhCounterCharge_1A 24000;
BA_REL_ "GenSigTimeoutTime" BU_SG_REL_ VCM SG_ 1467 WhCounterCharge_1A 6000;
BA_REL_ "GenSigFirstTimeoutTime" BU_SG_REL_ VCM SG_ 1467 HighCurrentIR1_1A 24000;
BA_REL_ "GenSigTimeoutTime" BU_SG_REL_ VCM SG_ 1467 HighCurrentIR1_1A 6000;
BA_REL_ "GenSigFirstTimeoutTime" BU_SG_REL_ VCM SG_ 1467 WhCounterDischarge_1A 24000;
BA_REL_ "GenSigTimeoutTime" BU_SG_REL_ VCM SG_ 1467 WhCounterDischarge_1A 6000;
BA_REL_ "GenSigFirstTimeoutTime" BU_SG_REL_ VCM SG_ 1465 HighCurrentIR1_1B 24000;
BA_REL_ "GenSigTimeoutTime" BU_SG_REL_ VCM SG_ 1465 HighCurrentIR1_1B 6000;
BA_REL_ "GenSigFirstTimeoutTime" BU_SG_REL_ VCM SG_ 1465 WhCounterCharge_1B 24000;
BA_REL_ "GenSigTimeoutTime" BU_SG_REL_ VCM SG_ 1465 WhCounterCharge_1B 6000;
BA_REL_ "GenSigFirstTimeoutTime" BU_SG_REL_ VCM SG_ 1465 WhCounterDischarge_1B 24000;
BA_REL_ "GenSigTimeoutTime" BU_SG_REL_ VCM SG_ 1465 WhCounterDischarge_1B 6000;
BA_REL_ "GenSigFirstTimeoutTime" BU_SG_REL_ VCM SG_ 1463 WhCounterDischarge_2A 24000;
BA_REL_ "GenSigTimeoutTime" BU_SG_REL_ VCM SG_ 1463 WhCounterDischarge_2A 6000;
BA_REL_ "GenSigFirstTimeoutTime" BU_SG_REL_ VCM SG_ 1463 HighCurrentIR1_2A 24000;
BA_REL_ "GenSigTimeoutTime" BU_SG_REL_ VCM SG_ 1463 HighCurrentIR1_2A 6000;
BA_REL_ "GenSigFirstTimeoutTime" BU_SG_REL_ VCM SG_ 1463 WhCounterCharge_2A 24000;
BA_REL_ "GenSigTimeoutTime" BU_SG_REL_ VCM SG_ 1463 WhCounterCharge_2A 6000;
BA_REL_ "GenSigFirstTimeoutTime" BU_SG_REL_ VCM SG_ 1461 HighCurrentIR1_2B 24000;
BA_REL_ "GenSigTimeoutTime" BU_SG_REL_ VCM SG_ 1461 HighCurrentIR1_2B 6000;
BA_REL_ "GenSigFirstTimeoutTime" BU_SG_REL_ VCM SG_ 1461 WhCounterCharge_2B 24000;
BA_REL_ "GenSigTimeoutTime" BU_SG_REL_ VCM SG_ 1461 WhCounterCharge_2B 6000;
BA_REL_ "GenSigFirstTimeoutTime" BU_SG_REL_ VCM SG_ 1461 WhCounterDischarge_2B 24000;
BA_REL_ "GenSigTimeoutTime" BU_SG_REL_ VCM SG_ 1461 WhCounterDischarge_2B 6000;
VAL_ 1343 TrailerDirIndLeftOutputStat 7 "TrailerLightOutputStat_NotAvailable" 6 "TrailerLightOutputStat_Error" 5 "TrailerLightOutputStat_OutputActiveStatusUncertain" 4 "TrailerLightOutputStat_OutputActiveLightDetectedOnActivation" 3 "TrailerLightOutputStat_OutputActiveLightDetected" 2 "TrailerLightOutputStat_OutputActiveNoLightDetected" 1 "TrailerLightOutputStat_OutputActiveDetectionOngoing" 0 "TrailerLightOutputStat_OutputInactive" ;
VAL_ 1343 TrailerBrakeLightOutputStat 7 "TrailerLightOutputStat_NotAvailable" 6 "TrailerLightOutputStat_Error" 5 "TrailerLightOutputStat_OutputActiveStatusUncertain" 4 "TrailerLightOutputStat_OutputActiveLightDetectedOnActivation" 3 "TrailerLightOutputStat_OutputActiveLightDetected" 2 "TrailerLightOutputStat_OutputActiveNoLightDetected" 1 "TrailerLightOutputStat_OutputActiveDetectionOngoing" 0 "TrailerLightOutputStat_OutputInactive" ;
VAL_ 1343 TrailerPosLightRightOutputStat 7 "TrailerLightOutputStat_NotAvailable" 6 "TrailerLightOutputStat_Error" 5 "TrailerLightOutputStat_OutputActiveStatusUncertain" 4 "TrailerLightOutputStat_OutputActiveLightDetectedOnActivation" 3 "TrailerLightOutputStat_OutputActiveLightDetected" 2 "TrailerLightOutputStat_OutputActiveNoLightDetected" 1 "TrailerLightOutputStat_OutputActiveDetectionOngoing" 0 "TrailerLightOutputStat_OutputInactive" ;
VAL_ 1343 TrailerPosLightLeftOutputStat 7 "TrailerLightOutputStat_NotAvailable" 6 "TrailerLightOutputStat_Error" 5 "TrailerLightOutputStat_OutputActiveStatusUncertain" 4 "TrailerLightOutputStat_OutputActiveLightDetectedOnActivation" 3 "TrailerLightOutputStat_OutputActiveLightDetected" 2 "TrailerLightOutputStat_OutputActiveNoLightDetected" 1 "TrailerLightOutputStat_OutputActiveDetectionOngoing" 0 "TrailerLightOutputStat_OutputInactive" ;
VAL_ 1343 LoadDistributionSelected2 15 "LoadDistributionSelected2_NotAvailable" 14 "LoadDistributionSelected2_Error" 13 "LoadDistributionSelected2_Reserved_01" 12 "LoadDistributionSelected2_TractionHelp2InterDiff" 11 "LoadDistributionSelected2_StartingHelp2InterDiff" 10 "LoadDistributionSelected2_TractionHelp2" 9 "LoadDistributionSelected2_StartingHelp2" 8 "LoadDistributionSelected2_VariableAxleLoad" 7 "LoadDistributionSelected2_NoLoadDistribution" 6 "LoadDistributionSelected2_TractionHelpInterDiff" 5 "LoadDistributionSelected2_StartingHelpInterDiff" 4 "LoadDistributionSelected2_AlternativeLoad" 3 "LoadDistributionSelected2_TractionHelp" 2 "LoadDistributionSelected2_StartingHelp" 1 "LoadDistributionSelected2_OptimisedTraction" 0 "LoadDistributionSelected2_NormalLoad" ;
VAL_ 1343 TrailerDirIndRightOutputStat 7 "TrailerLightOutputStat_NotAvailable" 6 "TrailerLightOutputStat_Error" 5 "TrailerLightOutputStat_OutputActiveStatusUncertain" 4 "TrailerLightOutputStat_OutputActiveLightDetectedOnActivation" 3 "TrailerLightOutputStat_OutputActiveLightDetected" 2 "TrailerLightOutputStat_OutputActiveNoLightDetected" 1 "TrailerLightOutputStat_OutputActiveDetectionOngoing" 0 "TrailerLightOutputStat_OutputInactive" ;
VAL_ 1343 ExtECSPressureUpdateAck 7 "ExtECSPressureUpdateAck_NotAvailable" 6 "ExtECSPressureUpdateAck_Error" 5 "ExtECSPressureUpdateAck_Spare4" 4 "ExtECSPressureUpdateAck_Spare3" 3 "ExtECSPressureUpdateAck_Spare2" 2 "ExtECSPressureUpdateAck_Spare1" 1 "ExtECSPressureUpdateAck_InProgress" 0 "ExtECSPressureUpdateAck_NoRequest" ;
VAL_ 825 RevLightLamp_stat 7 "LampCheckLeftRight_stat_NotAvailable" 6 "LampCheckLeftRight_stat_Error" 5 "LampCheckLeftRight_stat_Spare" 4 "LampCheckLeftRight_stat_TestedLeftAndRightLampNOK" 3 "LampCheckLeftRight_stat_TestedRightLampNOK" 2 "LampCheckLeftRight_stat_TestedLeftLampNOK" 1 "LampCheckLeftRight_stat_TestedLampOK" 0 "LampCheckLeftRight_stat_NotTested" ;
VAL_ 825 FirstAxleLowerPrioSelected 7 "FirstAxleLowerPrio_NotAvailable" 6 "FirstAxleLowerPrio_Error" 5 "FirstAxleLowerPrio_Reserved_03" 4 "FirstAxleLowerPrio_Reserved_02" 3 "FirstAxleLowerPrio_Reserved_01" 2 "FirstAxleLowerPrio_Reserved" 1 "FirstAxleLowerPrio_LowerPusher" 0 "FirstAxleLowerPrio_LowerTag" ;
VAL_ 825 FrontParkBrakeOverrideInd 3 "FrontParkBrakeOverrideInd_NotAvailable" 2 "FrontParkBrakeOverrideInd_Error" 1 "FrontParkBrakeOverrideInd_FailedToOverride" 0 "FrontParkBrakeOverrideInd_OK" ;
VAL_ 825 ECSLimpHomeNotification 7 "ECSLimpHomeNotification_NotAvailable" 6 "ECSLimpHomeNotification_Error" 5 "ECSLimpHomeNotification_LimpHomeMode5" 4 "ECSLimpHomeNotification_LimpHomeMode4" 3 "ECSLimpHomeNotification_LimpHomeMode3" 2 "ECSLimpHomeNotification_LimpHomeMode2" 1 "ECSLimpHomeNotification_LimpHomeMode1" 0 "ECSLimpHomeNotification_NoLimpHomeMode" ;
VAL_ 825 ECSValveActivationAllowed 3 "FalseTrue_NotAvaiable" 2 "FalseTrue_Error" 1 "FalseTrue_True" 0 "FalseTrue_False" ;
VAL_ 825 UnevenLoadWarning 3 "Warning_NotAvailable" 2 "Warning_Error" 1 "Warning_Warning" 0 "Warning_NoWarning" ;
VAL_ 825 RampLevelRequestACK 3 "ChangeRequest2Bit_NotAvailable" 2 "ChangeRequest2Bit_Error" 1 "ChangeRequest2Bit_Change" 0 "ChangeRequest2Bit_TakeNoAction" ;
VAL_ 825 LoadDistributionSelected 15 "LoadDistributionSelected_NotAvailable" 14 "LoadDistributionSelected_Error" 13 "LoadDistributionSelected_Reserved_05" 12 "LoadDistributionSelected_Reserved_04" 11 "LoadDistributionSelected_Reserved_03" 10 "LoadDistributionSelected_TractionHelp2" 9 "LoadDistributionSelected_StartingHelp2" 8 "LoadDistributionSelected_VariableAxleLoad" 7 "LoadDistributionSelected_NoLoadDistribution" 6 "LoadDistributionSelected_TractionHelpInterDiff" 5 "LoadDistributionSelected_StartingHelpInterDiff" 4 "LoadDistributionSelected_AlternativeLoad" 3 "LoadDistributionSelected_TractionHelp" 2 "LoadDistributionSelected_StartingHelp" 1 "LoadDistributionSelected_OptimisedTraction" 0 "LoadDistributionSelected_NormalLoad" ;
VAL_ 825 TrailerABSStatus 3 "TrailerABSStatus_NotAvailable" 2 "TrailerABSStatus_ErrorIndicator" 1 "TrailerABSStatus_OK" 0 "TrailerABSStatus_Error" ;
VAL_ 825 RevLight_cmd 3 "InactiveActive_NotAvailable" 2 "InactiveActive_Error" 1 "InactiveActive_Active" 0 "InactiveActive_Inactive" ;
VAL_ 825 LoadDistributionALDChangeACK 7 "LoadDistributionALDChangeACK_NotAvailable" 6 "LoadDistributionALDChangeACK_Error" 5 "LoadDistributionALDChangeACK_SystemDeniedVersatile" 4 "LoadDistributionALDChangeACK_Spare_01" 3 "LoadDistributionALDChangeACK_Spare" 2 "LoadDistributionALDChangeACK_LoadShiftDeniedOverspeed" 1 "LoadDistributionALDChangeACK_ChangeAcknowledged" 0 "LoadDistributionALDChangeACK_NoAction" ;
VAL_ 825 FogLightRearLamp_stat 7 "LampCheck_stat_NotAvailable" 6 "LampCheck_stat_Error" 5 "LampCheck_stat_Spare_02" 4 "LampCheck_stat_Spare_01" 3 "LampCheck_stat_Spare" 2 "LampCheck_stat_TestedLampNOK" 1 "LampCheck_stat_TestedLampOK" 0 "LampCheck_stat_NotTested" ;
VAL_ 825 PositionLightRearLamp_stat 7 "LampCheckLeftRight_stat_NotAvailable" 6 "LampCheckLeftRight_stat_Error" 5 "LampCheckLeftRight_stat_Spare" 4 "LampCheckLeftRight_stat_TestedLeftAndRightLampNOK" 3 "LampCheckLeftRight_stat_TestedRightLampNOK" 2 "LampCheckLeftRight_stat_TestedLeftLampNOK" 1 "LampCheckLeftRight_stat_TestedLampOK" 0 "LampCheckLeftRight_stat_NotTested" ;
VAL_ 825 FerryFunctionSwitchChangeACK 3 "Ack2Bit_NotAvailable" 2 "Ack2Bit_Error" 1 "Ack2Bit_ChangeAcknowledged" 0 "Ack2Bit_NoAction" ;
VAL_ 825 BrakeLight_rqst 7 "BrakeLight_rqst_NotAvailable" 6 "BrakeLight_rqst_SpareValue_03" 5 "BrakeLight_rqst_SpareValue_02" 4 "BrakeLight_rqst_SpareValue_01" 3 "BrakeLight_rqst_SpareValue" 2 "BrakeLight_rqst_EmergencyBrakeLightOn" 1 "BrakeLight_rqst_BrakeLightOn" 0 "BrakeLight_rqst_BrakeLightAndEmergencyBrakeLightOff" ;
VAL_ 825 BrakeLightConvoy_rqst 3 "OffOn_NotAvailable" 2 "OffOn_Error" 1 "OffOn_On" 0 "OffOn_Off" ;
VAL_ 825 LiftAxle1AutoLiftSelected 3 "FalseTrue_NotAvaiable" 2 "FalseTrue_Error" 1 "FalseTrue_True" 0 "FalseTrue_False" ;
VAL_ 825 BrakeLightLamp_stat 7 "LampCheckLeftRight_stat_NotAvailable" 6 "LampCheckLeftRight_stat_Error" 5 "LampCheckLeftRight_stat_Spare" 4 "LampCheckLeftRight_stat_TestedLeftAndRightLampNOK" 3 "LampCheckLeftRight_stat_TestedRightLampNOK" 2 "LampCheckLeftRight_stat_TestedLeftLampNOK" 1 "LampCheckLeftRight_stat_TestedLampOK" 0 "LampCheckLeftRight_stat_NotTested" ;
VAL_ 825 LiftAxle2AutoLiftSelected 3 "FalseTrue_NotAvaiable" 2 "FalseTrue_Error" 1 "FalseTrue_True" 0 "FalseTrue_False" ;
VAL_ 825 StartupProhibitStatus 3 "InactiveActive_NotAvailable" 2 "InactiveActive_Error" 1 "InactiveActive_Active" 0 "InactiveActive_Inactive" ;
VAL_ 825 LiftAxle1LowerACK 7 "LiftAxle1LowerACK_NotAvailable" 6 "LiftAxle1LowerACK_Error" 5 "LiftAxle1LowerACK_SystemDeniedVersatile" 4 "LiftAxle1LowerACK_Spare_01" 3 "LiftAxle1LowerACK_Spare" 2 "LiftAxle1LowerACK_LowerDeniedRAS_EC" 1 "LiftAxle1LowerACK_ChangeAcknowledged" 0 "LiftAxle1LowerACK_NoAction" ;
VAL_ 825 TrailerDirInd_status 7 "DirIndFaultStatus_NotAvailable" 6 "DirIndFaultStatus_Error" 5 "DirIndFaultStatus_SpareValue_01" 4 "DirIndFaultStatus_SpareValue" 3 "DirIndFaultStatus_BothLeftAndRightDirectionIndicatorsFault" 2 "DirIndFaultStatus_RightDirectionIndicatorLampFault" 1 "DirIndFaultStatus_LeftDirectionIndicatorLampFault" 0 "DirIndFaultStatus_NoError" ;
VAL_ 825 DriveLevelPosUserInteraction 7 "DriveLevelPosUserInteraction_NotAvailable" 6 "DriveLevelPosUserInteraction_Error" 5 "DriveLevelPosUserInteraction_Spare3" 4 "DriveLevelPosUserInteraction_Spare2" 3 "DriveLevelPosUserInteraction_Spare1" 2 "DriveLevelPosUserInteraction_WarningDriveLevelPosNotSelected" 1 "DriveLevelPosUserInteraction_DriveLevelPositionNotSelected" 0 "DriveLevelPosUserInteraction_DriveLevelPositionSelected" ;
VAL_ 948 FrontEndPositionStatus 7 "EndPositionStatus_NotAvailable" 6 "EndPositionStatus_Error" 5 "EndPositionStatus_Reserved_01" 4 "EndPositionStatus_Reserved" 3 "EndPositionStatus_LiftingAndLoweringNotAllowed" 2 "EndPositionStatus_MinEndLevelReached" 1 "EndPositionStatus_MaxEndLevelReached" 0 "EndPositionStatus_NoEndLevelReached" ;
VAL_ 948 DirIndRearLamp_Stat 7 "LampCheckLeftRight_stat_NotAvailable" 6 "LampCheckLeftRight_stat_Error" 5 "LampCheckLeftRight_stat_Spare" 4 "LampCheckLeftRight_stat_TestedLeftAndRightLampNOK" 3 "LampCheckLeftRight_stat_TestedRightLampNOK" 2 "LampCheckLeftRight_stat_TestedLeftLampNOK" 1 "LampCheckLeftRight_stat_TestedLampOK" 0 "LampCheckLeftRight_stat_NotTested" ;
VAL_ 948 FrontAxleInBumperRange 3 "AxleInBumperRange_NotAvailable" 2 "AxleInBumperRange_ErrorIndicator" 1 "AxleInBumperRange_ActualLevelWithinBumperRange" 0 "AxleInBumperRange_ActualLevelOutOfBumperRange" ;
VAL_ 948 LoadDistributionRequestedACK 7 "LoadDistributionRequestedACK_NotAvailable" 6 "LoadDistributionRequestedACK_Error" 5 "LoadDistributionRequestedACK_SystemDeniedVersatile" 4 "LoadDistributionRequestedACK_Reserved2" 3 "LoadDistributionRequestedACK_DeniedDueToDisengagedDifflock" 2 "LoadDistributionRequestedACK_LoadShiftDeniedFALIMOverload" 1 "LoadDistributionRequestedACK_ChangeAcknowledged" 0 "LoadDistributionRequestedACK_NoAction" ;
VAL_ 948 Rear1ClutchStatus 3 "DisengageEngage_NotAvailable" 2 "DisengageEngage_Error" 1 "DisengageEngage_Engage" 0 "DisengageEngage_Disengage" ;
VAL_ 947 FPBRMMIStat_FPBRChangeAck 3 "Ack2Bit_NotAvailable" 2 "Ack2Bit_Error" 1 "Ack2Bit_ChangeAcknowledged" 0 "Ack2Bit_NoAction" ;
VAL_ 947 FPBRMMIStat_FPBRStatusInd 3 "FPBRStatusInd_NotAvailable" 2 "FPBRStatusInd_Changing" 1 "FPBRStatusInd_On" 0 "FPBRStatusInd_Off" ;
VAL_ 947 LiftAxle1LiftAllowed_Stat 7 "LiftAxleLiftAllowed_NotAvailable" 6 "LiftAxleLiftAllowed_Error" 5 "LiftAxleLiftAllowed_Spare2" 4 "LiftAxleLiftAllowed_Spare1" 3 "LiftAxleLiftAllowed_Stat_SystemDeniedVersatile" 2 "LiftAxleLiftAllowed_Stat_LiftDeniedRearOverload" 1 "LiftAxleLiftAllowed_Stat_LiftDeniedFrontOverload" 0 "LiftAxleLiftAllowed_Stat_LiftAllowed" ;
VAL_ 530 AirDumpStatus 7 "AirDumpStatus_NotAvailable" 6 "AirDumpStatus_Error" 5 "AirDumpStatus_Spare2" 4 "AirDumpStatus_Spare1" 3 "AirDumpStatus_Denied" 2 "AirDumpStatus_ActiveReached" 1 "AirDumpStatus_ActiveNotReached" 0 "AirDumpStatus_Inactive" ;
VAL_ 530 RearAxle2DiffLock_stat 3 "OffOn_NotAvailable" 2 "OffOn_Error" 1 "OffOn_On" 0 "OffOn_Off" ;
VAL_ 530 SWBrakeSwitch 3 "BrakeSwitch_NotAvailable" 2 "BrakeSwitch_Error" 1 "BrakeSwitch_BrakePedalDepressed" 0 "BrakeSwitch_BrakePedalReleased" ;
VAL_ 530 RearAxle1DiffLock_stat 3 "OffOn_NotAvailable" 2 "OffOn_Error" 1 "OffOn_On" 0 "OffOn_Off" ;
VAL_ 530 BackToDriveReqACK 3 "BackToDriveReqACK_NotAvailable" 2 "BackToDriveReqACK_Error" 1 "BackToDriveReqACK_ChangeAcknowledged" 0 "BackToDriveReqACK_TakNoAction" ;
VAL_ 530 TrailerWithoutABS 3 "TrailerWithoutABS_NotAvailableOrNotInstalled" 2 "TrailerWithoutABS_ErrorIndicator" 1 "TrailerWithoutABS_YesTrailerWithoutABS" 0 "TrailerWithoutABS_NoNoTrailerPresentOraTrailerWithABS" ;
VAL_ 530 TrailerConnected 3 "NoYes_NotAvailable" 2 "NoYes_Error" 1 "NoYes_Yes" 0 "NoYes_No" ;
VAL_ 530 CentralRearDiffLock_stat 3 "DisengageEngage_NotAvailable" 2 "DisengageEngage_Error" 1 "DisengageEngage_Engage" 0 "DisengageEngage_Disengage" ;
VAL_ 528 RollEndPositionStatus 7 "RollEndPositionStatus_NotAvailable" 6 "RollEndPositionStatus_Error" 5 "RollEndPositionStatus_Reserved_01" 4 "RollEndPositionStatus_Reserved" 3 "RollEndPositionStatus_NoRollingAllowed" 2 "RollEndPositionStatus_CounterClockwiseEndLevelReached" 1 "RollEndPositionStatus_ClockwiseEndLevelReached" 0 "RollEndPositionStatus_NoEndLevelReached" ;
VAL_ 528 FrontFerryFunctionCmd 7 "FerryFunctionCmd_NotAvailable" 6 "FerryFunctionCmd_Error" 5 "FerryFunctionCmd_Spare2" 4 "FerryFunctionCmd_Spare1" 3 "FerryFunctionCmd_Spare0" 2 "FerryFunctionCmd_Drain" 1 "FerryFunctionCmd_CloseValves" 0 "FerryFunctionCmd_Inactive" ;
VAL_ 528 RideHeightFunctionStatus 15 "RideHeightFunction_NotAvailable" 14 "RideHeightFunction_ErrorIndicator" 13 "RideHeightFunction_NotDefined_05" 12 "RideHeightFunction_NotDefined_04" 11 "RideHeightFunction_NotDefined_03" 10 "RideHeightFunction_NotDefined_02" 9 "RideHeightFunction_NotDefined_01" 8 "RideHeightFunction_NotDefined" 7 "RideHeightFunction_AlternativeDrivePosition2" 6 "RideHeightFunction_AlternativeDrivePosition1" 5 "RideHeightFunction_LowDrivePosition" 4 "RideHeightFunction_HighDrivePosition" 3 "RideHeightFunction_SpeedDependentDrivePosition" 2 "RideHeightFunction_AlternativeDrivePosition" 1 "RideHeightFunction_StandardDrivePosition" 0 "RideHeightFunction_Inactive" ;
VAL_ 528 HeightControlMode 15 "HeightControlMode_NotAvailable" 14 "HeightControlMode_ErrorIndicator" 13 "HeightControlMode_DumpFunction" 12 "HeightControlMode_FactorySupportMode" 11 "HeightControlMode_Calibration" 10 "HeightControlMode_Prohibit" 9 "HeightControlMode_FunctionTest" 8 "HeightControlMode_Stop" 7 "HeightControlMode_LimpHome" 6 "HeightControlMode_FerryFunction" 5 "HeightControlMode_KneelingHeight" 4 "HeightControlMode_DriveHeight" 3 "HeightControlMode_DockingRampHeight" 2 "HeightControlMode_HeightAdjustment" 1 "HeightControlMode_StartUpHeight" 0 "HeightControlMode_TakeNoAction" ;
VAL_ 528 ECSShutdownCmd 3 "FalseTrue_NotAvaiable" 2 "FalseTrue_Error" 1 "FalseTrue_True" 0 "FalseTrue_False" ;
VAL_ 528 FerryFunctionStatus 7 "FerryFunctionStatus_NotAvailable" 6 "FerryFunctionStatus_Error" 5 "FerryFunctionStatus_Spare_03" 4 "FerryFunctionStatus_Spare_02" 3 "FerryFunctionStatus_Spare_01" 2 "FerryFunctionStatus_FerryFunctionActiveLeveNotlReached" 1 "FerryFunctionStatus_FerryFunctionActiveLevelReached" 0 "FerryFunctionStatus_FerryFunctionNotActive" ;
VAL_ 528 LevelControlInformation 15 "LevelControlInformation_NotAvailable" 14 "LevelControlInformation_Error" 13 "LevelControlInformation_Reserved_06" 12 "LevelControlInformation_Reserved_05" 11 "LevelControlInformation_Reserved_04" 10 "LevelControlInformation_Reserved_03" 9 "LevelControlInformation_Reserved_02" 8 "LevelControlInformation_Reserved_01" 7 "LevelControlInformation_Reserved" 6 "LevelControlInformation_LimpHome" 5 "LevelControlInformation_FerryFunction" 4 "LevelControlInformation_KneelingHeight" 3 "LevelControlInformation_DriveHeight" 2 "LevelControlInformation_DockingHeight" 1 "LevelControlInformation_HeightAdjustment" 0 "LevelControlInformation_Prohibit" ;
VAL_ 528 ChangeKneelACK 3 "ChangeKneelACK_NotAvailable" 2 "ChangeKneelACK_Error" 1 "ChangeKneelACK_ChangeAcknowledged" 0 "ChangeKneelACK_NoAction" ;
VAL_ 528 RearEndPositionStatus 7 "EndPositionStatus_NotAvailable" 6 "EndPositionStatus_Error" 5 "EndPositionStatus_Reserved_01" 4 "EndPositionStatus_Reserved" 3 "EndPositionStatus_LiftingAndLoweringNotAllowed" 2 "EndPositionStatus_MinEndLevelReached" 1 "EndPositionStatus_MaxEndLevelReached" 0 "EndPositionStatus_NoEndLevelReached" ;
VAL_ 528 RampHeightOutsideTargetRange 7 "HeightOutsideTargetRange_NotAvailable" 6 "HeightOutsideTargetRange_Error" 5 "HeightOutsideTargetRange_NotDefined_02" 4 "HeightOutsideTargetRange_NotDefined_01" 3 "HeightOutsideTargetRange_NotDefined" 2 "HeightOutsideTargetRange_ToHigh" 1 "HeightOutsideTargetRange_ToLow" 0 "HeightOutsideTargetRange_Inactive" ;
VAL_ 528 LoadDistributionFuncSelected 15 "LoadDistributionFuncSelected_NotAvaiable" 14 "LoadDistributionFuncSelected_ErrorIndicator" 13 "LoadDistributionFuncSelected_SpareValue_08" 12 "LoadDistributionFuncSelected_SpareValue_07" 11 "LoadDistributionFuncSelected_SpareValue_06" 10 "LoadDistributionFuncSelected_SpareValue_05" 9 "LoadDistributionFuncSelected_SpareValue_04" 8 "LoadDistributionFuncSelected_SpareValue_03" 7 "LoadDistributionFuncSelected_SpareValue_02" 6 "LoadDistributionFuncSelected_MaximumTractionStartingHelp" 5 "LoadDistributionFuncSelected_VariableAxleLoad" 4 "LoadDistributionFuncSelected_NoLoadDistribution" 3 "LoadDistributionFuncSelected_AlternativeLoad" 2 "LoadDistributionFuncSelected_MaximumTractionTractionHelp" 1 "LoadDistributionFuncSelected_OptimisedTraction" 0 "LoadDistributionFuncSelected_NormalLoad" ;
VAL_ 528 HeightAdjustmentAllowed 3 "FalseTrue_NotAvaiable" 2 "FalseTrue_Error" 1 "FalseTrue_True" 0 "FalseTrue_False" ;
VAL_ 528 KneelingInformation 15 "KneelingInformation_NotAvailable" 14 "KneelingInformation_ErrorIndicator" 13 "KneelingInformation_NotDefined_08" 12 "KneelingInformation_NotDefined_07" 11 "KneelingInformation_NotDefined_06" 10 "KneelingInformation_NotDefined_05" 9 "KneelingInformation_NotDefined_04" 8 "KneelingInformation_NotDefined_03" 7 "KneelingInformation_NotDefined_02" 6 "KneelingInformation_NotDefined_01" 5 "KneelingInformation_NotDefined" 4 "KneelingInformation_KneelingAborted" 3 "KneelingInformation_LiftingActiveVehicleIsLiftedDueToRcvrReq" 2 "KneelingInformation_KneelLevelReachedVehicleIsAtFixeKneelLvl" 1 "KneelingInformation_LoweringActiveTheVehIsLoweredDueToKneelReq" 0 "KneelingInformation_NotActiveTheKneelingFunctionIsNotActive" ;
VAL_ 528 KneelingStatusHMI 3 "KneelingStatusHMI_NotAvailable" 2 "KneelingStatusHMI_Error" 1 "KneelingStatusHMI_Active" 0 "KneelingStatusHMI_Inactive" ;
VAL_ 528 LiftAxle1PositionStatus 7 "LiftAxlePositionStatus_NotAvailable" 6 "LiftAxlePositionStatus_Error" 5 "LiftAxlePositionStatus_Reserved_01" 4 "LiftAxlePositionStatus_Reserved" 3 "LiftAxlePositionStatus_Lifting" 2 "LiftAxlePositionStatus_Lowering" 1 "LiftAxlePositionStatus_Lifted" 0 "LiftAxlePositionStatus_Lowered" ;
VAL_ 528 VehicleDynamicSuspProhibitStat 3 "InactiveActive_NotAvailable" 2 "InactiveActive_Error" 1 "InactiveActive_Active" 0 "InactiveActive_Inactive" ;
VAL_ 528 LiftAxle2PositionStatus 7 "LiftAxlePositionStatus_NotAvailable" 6 "LiftAxlePositionStatus_Error" 5 "LiftAxlePositionStatus_Reserved_01" 4 "LiftAxlePositionStatus_Reserved" 3 "LiftAxlePositionStatus_Lifting" 2 "LiftAxlePositionStatus_Lowering" 1 "LiftAxlePositionStatus_Lifted" 0 "LiftAxlePositionStatus_Lowered" ;
VAL_ 528 RideHeightStatus 15 "RideHeightStatus_NotAvailable" 14 "RideHeightStatus_ErrorIndicator" 13 "RideHeightStatus_NotDefined_03" 12 "RideHeightStatus_NotDefined_02" 11 "RideHeightStatus_NotDefined_01" 10 "RideHeightStatus_NotDefined" 9 "RideHeightStatus_AlternativeDrivePosition2" 8 "RideHeightStatus_AlternativeDrivePosition1" 7 "RideHeightStatus_AlternativeDrivePosition" 6 "RideHeightStatus_HighDrivePosition" 5 "RideHeightStatus_LowDrivePosition" 4 "RideHeightStatus_SpeedDependentDrivePositionHighSpeed" 3 "RideHeightStatus_SpeedDependentDrivePositionLowSpeed" 2 "RideHeightStatus_StandardUserDrivePosition" 1 "RideHeightStatus_StandardFactoryDrivePosition" 0 "RideHeightStatus_Inactive" ;
VAL_ 528 DirInd_Rear_Status 7 "DirIndFaultStatus_NotAvailable" 6 "DirIndFaultStatus_Error" 5 "DirIndFaultStatus_SpareValue_01" 4 "DirIndFaultStatus_SpareValue" 3 "DirIndFaultStatus_BothLeftAndRightDirectionIndicatorsFault" 2 "DirIndFaultStatus_RightDirectionIndicatorLampFault" 1 "DirIndFaultStatus_LeftDirectionIndicatorLampFault" 0 "DirIndFaultStatus_NoError" ;
VAL_ 517 FrontProhibitControlRequest 3 "Request_NotAvailable" 2 "Request_Error" 1 "Request_RequestActive" 0 "Request_NotRequested" ;
VAL_ 517 RampLevelStorageAck 3 "StorageAck_NotAvaiable" 2 "StorageAck_Error" 1 "StorageAck_ChangeAcknowledged" 0 "StorageAck_TakeNoAction" ;
VAL_ 517 FrontLimpHomeCmd 7 "LimpHomeCmd_NotAvailable" 6 "LimpHomeCmd_Error" 5 "LimpHomeCmd_Spare_01" 4 "LimpHomeCmd_Spare" 3 "LimpHomeCmd_Fill" 2 "LimpHomeCmd_Drain" 1 "LimpHomeCmd_CloseValves" 0 "LimpHomeCmd_Inactive" ;
VAL_ 517 LiftingControlModeRearAxle 3 "InactiveActive_NotAvailable" 2 "InactiveActive_Error" 1 "InactiveActive_Active" 0 "InactiveActive_Inactive" ;
VAL_ 517 LoadDistributionChangeACK 7 "LoadDistributionChangeACK_NotAvailable" 6 "LoadDistributionChangeACK_Error" 5 "LoadDistributionChangeACK_SystemDeniedVersatile" 4 "LoadDistributionChangeACK_Reserved_2" 3 "LoadDistributionChangeACK_DeniedDueToDisengagedDifflock" 2 "LoadDistributionChangeACK_LoadShiftDeniedFALIMOverload" 1 "LoadDistributionChangeACK_ChangeAcknowledged" 0 "LoadDistributionChangeACK_NoAction" ;
VAL_ 517 ECSStandbyAllowed 3 "FalseTrue_NotAvaiable" 2 "FalseTrue_Error" 1 "FalseTrue_True" 0 "FalseTrue_False" ;
VAL_ 517 LiftAxle2LiftFuncSelected 7 "LiftAxleLiftAutoFuncSelected_NotAvailable" 6 "LiftAxleLiftAutoFuncSelected_Error" 5 "LiftAxleLiftAutoFuncSelected_Reserved" 4 "LiftAxleLiftAutoFuncSelected_UnlimitedLift" 3 "LiftAxleLiftAutoFuncSelected_LiftOverload" 2 "LiftAxleLiftAutoFuncSelected_LiftPlus30" 1 "LiftAxleLiftAutoFuncSelected_Lift" 0 "LiftAxleLiftAutoFuncSelected_NoLift" ;
VAL_ 517 LiftAxle2UpRequestACK 7 "LiftAxleUpRequestACK_NotAvailable" 6 "LiftAxleUpRequestACK_Error" 5 "LiftAxleUpRequestACK_SystemDeniedVersatile" 4 "LiftAxleUpRequestACK_LiftDeniedPBrakeActive" 3 "LiftAxleUpRequestACK_LiftDeniedRearOverload" 2 "LiftAxleUpRequestACK_LiftDeniedFrontOverload" 1 "LiftAxleUpRequestACK_ChangeAcknowledged" 0 "LiftAxleUpRequestACK_NoAction" ;
VAL_ 517 ProhibitControlStatus 3 "InactiveActive_NotAvailable" 2 "InactiveActive_Error" 1 "InactiveActive_Active" 0 "InactiveActive_Inactive" ;
VAL_ 517 RampLevelStatus 15 "RampLevelStatus_NotAvaiable" 14 "RampLevelStatus_ErrorIndicator" 13 "RampLevelStatus_NotDefined_05" 12 "RampLevelStatus_NotDefined_04" 11 "RampLevelStatus_NotDefined_03" 10 "RampLevelStatus_NotDefined_02" 9 "RampLevelStatus_NotDefined_01" 8 "RampLevelStatus_NotDefined" 7 "RampLevelStatus_RampLevelM7" 6 "RampLevelStatus_RampLevelM6" 5 "RampLevelStatus_RampLevelM5" 4 "RampLevelStatus_RampLevelM4" 3 "RampLevelStatus_RampLevelM3" 2 "RampLevelStatus_RampLevelM2" 1 "RampLevelStatus_RampLevelM1" 0 "RampLevelStatus_Inactive" ;
VAL_ 517 StopLevelChangeAck 3 "StopLevelChangeStatus_NotAvailable" 2 "StopLevelChangeStatus_ErrorIndicator" 1 "StopLevelChangeStatus_LevelChangedStopped" 0 "StopLevelChangeStatus_NoStopRequest" ;
VAL_ 517 LiftAxle2LowerACK 7 "LiftAxle2LowerACK_NotAvailable" 6 "LiftAxle2LowerACK_Error" 5 "LiftAxle2LowerACK_SystemDeniedVersatile" 4 "LiftAxle2LowerACK_Spare_01" 3 "LiftAxle2LowerACK_Spare" 2 "LiftAxle2LowerACK_LowerDeniedRAS_EC" 1 "LiftAxle2LowerACK_ChangeAcknowledged" 0 "LiftAxle2LowerACK_NoAction" ;
VAL_ 517 RideHeightStorageAck 3 "StorageAck_NotAvaiable" 2 "StorageAck_Error" 1 "StorageAck_ChangeAcknowledged" 0 "StorageAck_TakeNoAction" ;
VAL_ 517 FrontParkBrakeOverrideCommand 3 "FrontParkBrakeOverrideCommand_NotAvailable" 2 "FrontParkBrakeOverrideCommand_ErrorIndicator" 1 "FrontParkBrakeOverrideCommand_FrontParkBrakeOverrideCommand" 0 "FrontParkBrakeOverrideCommand_NoCommand" ;
VAL_ 517 RideHeightOutsideTargetRange 7 "HeightOutsideTargetRange_NotAvailable" 6 "HeightOutsideTargetRange_Error" 5 "HeightOutsideTargetRange_NotDefined_02" 4 "HeightOutsideTargetRange_NotDefined_01" 3 "HeightOutsideTargetRange_NotDefined" 2 "HeightOutsideTargetRange_ToHigh" 1 "HeightOutsideTargetRange_ToLow" 0 "HeightOutsideTargetRange_Inactive" ;
VAL_ 517 DisableMechFaultDctnFr_rqst 3 "FalseTrue_NotAvaiable" 2 "FalseTrue_Error" 1 "FalseTrue_True" 0 "FalseTrue_False" ;
VAL_ 517 FogLamp_Rear_Status 3 "InactiveActive_NotAvailable" 2 "InactiveActive_Error" 1 "InactiveActive_Active" 0 "InactiveActive_Inactive" ;
VAL_ 517 LiftingControlModeFrontAxle 3 "InactiveActive_NotAvailable" 2 "InactiveActive_Error" 1 "InactiveActive_Active" 0 "InactiveActive_Inactive" ;
VAL_ 517 LiftAxle1UpRequestACK 7 "LiftAxleUpRequestACK_NotAvailable" 6 "LiftAxleUpRequestACK_Error" 5 "LiftAxleUpRequestACK_SystemDeniedVersatile" 4 "LiftAxleUpRequestACK_LiftDeniedPBrakeActive" 3 "LiftAxleUpRequestACK_LiftDeniedRearOverload" 2 "LiftAxleUpRequestACK_LiftDeniedFrontOverload" 1 "LiftAxleUpRequestACK_ChangeAcknowledged" 0 "LiftAxleUpRequestACK_NoAction" ;
VAL_ 517 LiftAxle1LiftFuncSelected 7 "LiftAxleLiftAutoFuncSelected_NotAvailable" 6 "LiftAxleLiftAutoFuncSelected_Error" 5 "LiftAxleLiftAutoFuncSelected_Reserved" 4 "LiftAxleLiftAutoFuncSelected_UnlimitedLift" 3 "LiftAxleLiftAutoFuncSelected_LiftOverload" 2 "LiftAxleLiftAutoFuncSelected_LiftPlus30" 1 "LiftAxleLiftAutoFuncSelected_Lift" 0 "LiftAxleLiftAutoFuncSelected_NoLift" ;
VAL_ 517 RearAxleInBumperRange 3 "AxleInBumperRange_NotAvailable" 2 "AxleInBumperRange_ErrorIndicator" 1 "AxleInBumperRange_ActualLevelWithinBumperRange" 0 "AxleInBumperRange_ActualLevelOutOfBumperRange" ;
VAL_ 1339 HeadlampFan_stat 7 "LampFanTestStat_NotAvailable" 6 "LampFanTestStat_Error" 5 "LampFanTestStat_Spare3" 4 "LampFanTestStat_Spare2" 3 "LampFanTestStat_Spare1" 2 "LampFanTestStat_FanTestedNOK" 1 "LampFanTestStat_FanTestedOK" 0 "LampFanTestStat_NotTested" ;
VAL_ 1339 FrontConspicLamp_stat_HiRight 7 "LampCheck_stat_NotAvailable" 6 "LampCheck_stat_Error" 5 "LampCheck_stat_Spare_02" 4 "LampCheck_stat_Spare_01" 3 "LampCheck_stat_Spare" 2 "LampCheck_stat_TestedLampNOK" 1 "LampCheck_stat_TestedLampOK" 0 "LampCheck_stat_NotTested" ;
VAL_ 1339 FrontConspicLamp_stat_LoRight 7 "LampCheck_stat_NotAvailable" 6 "LampCheck_stat_Error" 5 "LampCheck_stat_Spare_02" 4 "LampCheck_stat_Spare_01" 3 "LampCheck_stat_Spare" 2 "LampCheck_stat_TestedLampNOK" 1 "LampCheck_stat_TestedLampOK" 0 "LampCheck_stat_NotTested" ;
VAL_ 1339 FrontConspicLamp_stat_HiLeft 7 "LampCheck_stat_NotAvailable" 6 "LampCheck_stat_Error" 5 "LampCheck_stat_Spare_02" 4 "LampCheck_stat_Spare_01" 3 "LampCheck_stat_Spare" 2 "LampCheck_stat_TestedLampNOK" 1 "LampCheck_stat_TestedLampOK" 0 "LampCheck_stat_NotTested" ;
VAL_ 1339 FrontConspicLamp_stat_LoLeft 7 "LampCheck_stat_NotAvailable" 6 "LampCheck_stat_Error" 5 "LampCheck_stat_Spare_02" 4 "LampCheck_stat_Spare_01" 3 "LampCheck_stat_Spare" 2 "LampCheck_stat_TestedLampNOK" 1 "LampCheck_stat_TestedLampOK" 0 "LampCheck_stat_NotTested" ;
VAL_ 1243 MainBeamLEDStatusRight 7 "LampCheck_stat_NotAvailable" 6 "LampCheck_stat_Error" 5 "LampCheck_stat_Spare_02" 4 "LampCheck_stat_Spare_01" 3 "LampCheck_stat_Spare" 2 "LampCheck_stat_TestedLampNOK" 1 "LampCheck_stat_TestedLampOK" 0 "LampCheck_stat_NotTested" ;
VAL_ 1243 DeicingBulb_Stat 7 "DeicingBulb_Stat_NotAvailable" 6 "DeicingBulb_Stat_Error" 5 "DeicingBulb_Stat_Spare2" 4 "DeicingBulb_Stat_Spare1" 3 "DeicingBulb_Stat_BothLampsNOK" 2 "DeicingBulb_Stat_AtleastOneLampOK" 1 "DeicingBulb_Stat_BothLampsOK" 0 "DeicingBulb_Stat_NotTested" ;
VAL_ 1243 DeicingFunction_Stat 7 "DeicingFunction_Stat_NotAvailable" 6 "DeicingFunction_Stat_Spare2" 5 "DeicingFunction_Stat_Spare1" 4 "DeicingFunction_Stat_Fault" 3 "DeicingFunction_Stat_Deactivated" 2 "DeicingFunction_Stat_Ongoing" 1 "DeicingFunction_Stat_Activated" 0 "DeicingFunction_Stat_NotTested" ;
VAL_ 1243 MainBeamLEDStatusLeft 7 "LampCheck_stat_NotAvailable" 6 "LampCheck_stat_Error" 5 "LampCheck_stat_Spare_02" 4 "LampCheck_stat_Spare_01" 3 "LampCheck_stat_Spare" 2 "LampCheck_stat_TestedLampNOK" 1 "LampCheck_stat_TestedLampOK" 0 "LampCheck_stat_NotTested" ;
VAL_ 952 DRLLamp_stat 7 "LampCheckLeftRight_stat_NotAvailable" 6 "LampCheckLeftRight_stat_Error" 5 "LampCheckLeftRight_stat_Spare" 4 "LampCheckLeftRight_stat_TestedLeftAndRightLampNOK" 3 "LampCheckLeftRight_stat_TestedRightLampNOK" 2 "LampCheckLeftRight_stat_TestedLeftLampNOK" 1 "LampCheckLeftRight_stat_TestedLampOK" 0 "LampCheckLeftRight_stat_NotTested" ;
VAL_ 952 FogLamp_Front_Status 3 "InactiveActive_NotAvailable" 2 "InactiveActive_Error" 1 "InactiveActive_Active" 0 "InactiveActive_Inactive" ;
VAL_ 952 DirIndSideLamp1_stat 7 "LampCheckLeftRight_stat_NotAvailable" 6 "LampCheckLeftRight_stat_Error" 5 "LampCheckLeftRight_stat_Spare" 4 "LampCheckLeftRight_stat_TestedLeftAndRightLampNOK" 3 "LampCheckLeftRight_stat_TestedRightLampNOK" 2 "LampCheckLeftRight_stat_TestedLeftLampNOK" 1 "LampCheckLeftRight_stat_TestedLampOK" 0 "LampCheckLeftRight_stat_NotTested" ;
VAL_ 952 PositionLightLamp_stat 7 "LampCheckLeftRight_stat_NotAvailable" 6 "LampCheckLeftRight_stat_Error" 5 "LampCheckLeftRight_stat_Spare" 4 "LampCheckLeftRight_stat_TestedLeftAndRightLampNOK" 3 "LampCheckLeftRight_stat_TestedRightLampNOK" 2 "LampCheckLeftRight_stat_TestedLeftLampNOK" 1 "LampCheckLeftRight_stat_TestedLampOK" 0 "LampCheckLeftRight_stat_NotTested" ;
VAL_ 952 DippedBeamLamp_stat 7 "LampCheckLeftRight_stat_NotAvailable" 6 "LampCheckLeftRight_stat_Error" 5 "LampCheckLeftRight_stat_Spare" 4 "LampCheckLeftRight_stat_TestedLeftAndRightLampNOK" 3 "LampCheckLeftRight_stat_TestedRightLampNOK" 2 "LampCheckLeftRight_stat_TestedLeftLampNOK" 1 "LampCheckLeftRight_stat_TestedLampOK" 0 "LampCheckLeftRight_stat_NotTested" ;
VAL_ 952 MainBeamLamp_stat 7 "LampCheckLeftRight_stat_NotAvailable" 6 "LampCheckLeftRight_stat_Error" 5 "LampCheckLeftRight_stat_Spare" 4 "LampCheckLeftRight_stat_TestedLeftAndRightLampNOK" 3 "LampCheckLeftRight_stat_TestedRightLampNOK" 2 "LampCheckLeftRight_stat_TestedLeftLampNOK" 1 "LampCheckLeftRight_stat_TestedLampOK" 0 "LampCheckLeftRight_stat_NotTested" ;
VAL_ 952 StaticCornerLightLamp_stat 7 "LampCheckLeftRight_stat_NotAvailable" 6 "LampCheckLeftRight_stat_Error" 5 "LampCheckLeftRight_stat_Spare" 4 "LampCheckLeftRight_stat_TestedLeftAndRightLampNOK" 3 "LampCheckLeftRight_stat_TestedRightLampNOK" 2 "LampCheckLeftRight_stat_TestedLeftLampNOK" 1 "LampCheckLeftRight_stat_TestedLampOK" 0 "LampCheckLeftRight_stat_NotTested" ;
VAL_ 952 AuxLamp_Front_Status 3 "InactiveActive_NotAvailable" 2 "InactiveActive_Error" 1 "InactiveActive_Active" 0 "InactiveActive_Inactive" ;
VAL_ 952 AuxFogLightLamp_stat 7 "LampCheckLeftRight_stat_NotAvailable" 6 "LampCheckLeftRight_stat_Error" 5 "LampCheckLeftRight_stat_Spare" 4 "LampCheckLeftRight_stat_TestedLeftAndRightLampNOK" 3 "LampCheckLeftRight_stat_TestedRightLampNOK" 2 "LampCheckLeftRight_stat_TestedLeftLampNOK" 1 "LampCheckLeftRight_stat_TestedLampOK" 0 "LampCheckLeftRight_stat_NotTested" ;
VAL_ 952 ExtraMainBeamLamp_stat 7 "LampCheckLeftRight_stat_NotAvailable" 6 "LampCheckLeftRight_stat_Error" 5 "LampCheckLeftRight_stat_Spare" 4 "LampCheckLeftRight_stat_TestedLeftAndRightLampNOK" 3 "LampCheckLeftRight_stat_TestedRightLampNOK" 2 "LampCheckLeftRight_stat_TestedLeftLampNOK" 1 "LampCheckLeftRight_stat_TestedLampOK" 0 "LampCheckLeftRight_stat_NotTested" ;
VAL_ 952 FogLightFrontLamp_stat 7 "LampCheck_stat_NotAvailable" 6 "LampCheck_stat_Error" 5 "LampCheck_stat_Spare_02" 4 "LampCheck_stat_Spare_01" 3 "LampCheck_stat_Spare" 2 "LampCheck_stat_TestedLampNOK" 1 "LampCheck_stat_TestedLampOK" 0 "LampCheck_stat_NotTested" ;
VAL_ 952 DirInd_Front_Status 7 "DirIndFaultStatus_NotAvailable" 6 "DirIndFaultStatus_Error" 5 "DirIndFaultStatus_SpareValue_01" 4 "DirIndFaultStatus_SpareValue" 3 "DirIndFaultStatus_BothLeftAndRightDirectionIndicatorsFault" 2 "DirIndFaultStatus_RightDirectionIndicatorLampFault" 1 "DirIndFaultStatus_LeftDirectionIndicatorLampFault" 0 "DirIndFaultStatus_NoError" ;
VAL_ 952 ChassiInstepLightsLamp_stat 7 "LampCheck_stat_NotAvailable" 6 "LampCheck_stat_Error" 5 "LampCheck_stat_Spare_02" 4 "LampCheck_stat_Spare_01" 3 "LampCheck_stat_Spare" 2 "LampCheck_stat_TestedLampNOK" 1 "LampCheck_stat_TestedLampOK" 0 "LampCheck_stat_NotTested" ;
VAL_ 952 WasherFluidLevel 7 "WasherFluidLevel_NotAvailable" 6 "WasherFluidLevel_ErrorIndicator" 5 "WasherFluidLevel_Spare_02" 4 "WasherFluidLevel_Spare_01" 3 "WasherFluidLevel_Spare" 2 "WasherFluidLevel_Level2" 1 "WasherFluidLevel_Level1" 0 "WasherFluidLevel_Level0" ;
VAL_ 1232 TrailerCommunicationType 7 "TrailerCommunicationType_NotAvailable" 6 "TrailerCommunicationType_Error" 5 "TrailerCommunicationType_Spare3" 4 "TrailerCommunicationType_Spare2" 3 "TrailerCommunicationType_Spare1" 2 "TrailerCommunicationType_SAE_J2497_Communication" 1 "TrailerCommunicationType_ISO_11992_2_Communication" 0 "TrailerCommunicationType_NoCommunication" ;
VAL_ 386 VDCBrakeLightRequest 3 "VDCBrakeLightRequest_DontCareTakeNoAction" 2 "VDCBrakeLightRequest_Reserved" 1 "VDCBrakeLightRequest_TurnBrakeLightON" 0 "VDCBrakeLightRequest_TurnBrakeLightOFF" ;
VAL_ 386 EBSBrakeSwitch 3 "EBSBrakeSwitch_NotAvailable" 2 "EBSBrakeSwitch_Error" 1 "EBSBrakeSwitch_BrakePedalDepressed" 0 "EBSBrakeSwitch_BrakePedalReleased" ;
VAL_ 386 BrakeLightActivationRequest 3 "OffOn_NotAvailable" 2 "OffOn_Error" 1 "OffOn_On" 0 "OffOn_Off" ;
VAL_ 824 Trailer1TractionHelp 3 "InactiveActive_NotAvailable" 2 "InactiveActive_Error" 1 "InactiveActive_Active" 0 "InactiveActive_Inactive" ;
VAL_ 824 TrailerBrake_Stat 3 "InactiveActive_NotAvailable" 2 "InactiveActive_Error" 1 "InactiveActive_Active" 0 "InactiveActive_Inactive" ;
VAL_ 824 SplitBoxDiffLockActvnFuncReq 3 "DisengageEngage_NotAvailable" 2 "DisengageEngage_Error" 1 "DisengageEngage_Engage" 0 "DisengageEngage_Disengage" ;
VAL_ 824 BrakingSystemPressureLim_rqst 3 "Request_NotAvailable" 2 "Request_Error" 1 "Request_RequestActive" 0 "Request_NotRequested" ;
VAL_ 824 TagLiftAxleLoweringInhibit 3 "InhibitStatus_NotAvailable" 2 "InhibitStatus_Reserved" 1 "InhibitStatus_Inhibited" 0 "InhibitStatus_NotInhibited" ;
VAL_ 824 ScndRrAxlDiffLckActvnFuncReq 3 "RearAxleDiffLockActvnFuncReq_TakeNoAction" 2 "RearAxleDiffLockActvnFuncReq_Reserved" 1 "RearAxleDiffLockActvnFuncReq_DisengageDifferentialLock" 0 "RearAxleDiffLockActvnFuncReq_EngageDifferentialLock" ;
VAL_ 824 Trailer1LiftAxle1Pos 3 "TrailerLiftAxlePos_NotAvailable" 2 "TrailerLiftAxlePos_Error" 1 "TrailerLiftAxlePos_AxleLifted" 0 "TrailerLiftAxlePos_AxleDown" ;
VAL_ 824 PusherLiftAxleLoweringInhibit 3 "InhibitStatus_NotAvailable" 2 "InhibitStatus_Reserved" 1 "InhibitStatus_Inhibited" 0 "InhibitStatus_NotInhibited" ;
VAL_ 824 StretchBrake_Stat 7 "StretchBrake_Stat_NotAvailable" 6 "StretchBrake_Stat_Error" 5 "StretchBrake_Stat_Spare_02" 4 "StretchBrake_Stat_Spare_01" 3 "StretchBrake_Stat_Spare" 2 "StretchBrake_Stat_Active" 1 "StretchBrake_Stat_Enabled" 0 "StretchBrake_Stat_Disabled" ;
VAL_ 824 Trailer1LiftAxle2Pos 3 "TrailerLiftAxlePos_NotAvailable" 2 "TrailerLiftAxlePos_Error" 1 "TrailerLiftAxlePos_AxleLifted" 0 "TrailerLiftAxlePos_AxleDown" ;
VAL_ 824 TrailerEBSAmberWarning 3 "OffOn_NotAvailable" 2 "OffOn_Error" 1 "OffOn_On" 0 "OffOn_Off" ;
VAL_ 824 FrontParkBrakeOverrideStatus 3 "InactiveActive_NotAvailable" 2 "InactiveActive_Error" 1 "InactiveActive_Active" 0 "InactiveActive_Inactive" ;
VAL_ 516 EASPusherLiftAxleLoweringInhib 3 "InhibitStatus_NotAvailable" 2 "InhibitStatus_Reserved" 1 "InhibitStatus_Inhibited" 0 "InhibitStatus_NotInhibited" ;
VAL_ 1362 Cur_EnergySetting 7 "EnergySetting_NotAvailable" 6 "EnergySetting_Error" 5 "EnergySetting_Spare2" 4 "EnergySetting_Spare1" 3 "EnergySetting_Customise" 2 "EnergySetting_PresetLevel2_HighEnergySaving" 1 "EnergySetting_PresetLevel1_EnergySaving" 0 "EnergySetting_OFF" ;
VAL_ 1444 BatteryCapacityGrpAck_Pos3 3 "NokOk_NotAvailable" 2 "NokOk_Error" 1 "NokOk_OK" 0 "NokOk_NOK" ;
VAL_ 1444 BatteryCapacityGrpAck_Pos2 3 "NokOk_NotAvailable" 2 "NokOk_Error" 1 "NokOk_OK" 0 "NokOk_NOK" ;
VAL_ 1444 BatteryCapacityGrpAck_Pos1 3 "NokOk_NotAvailable" 2 "NokOk_Error" 1 "NokOk_OK" 0 "NokOk_NOK" ;
VAL_ 1471 BatterySOCTrustLevel_stat1_1 15 "BatteryTrustLevel_NotAvailable" 14 "BatteryTrustLevel_Error" 13 "BatteryTrustLevel_Spare9" 12 "BatteryTrustLevel_Spare8" 11 "BatteryTrustLevel_Spare7" 10 "BatteryTrustLevel_Spare6" 9 "BatteryTrustLevel_Spare5" 8 "BatteryTrustLevel_Spare4" 7 "BatteryTrustLevel_Spare3" 6 "BatteryTrustLevel_Spare2" 5 "BatteryTrustLevel_Spare1" 4 "BatteryTrustLevel_NominalPlus15PercentAndAbove" 3 "BatteryTrustLevel_NominalPlus10Percent" 2 "BatteryTrustLevel_NominalPlus5Percent" 1 "BatteryTrustLevel_NominalAccuracy" 0 "BatteryTrustLevel_NotInitialized" ;
VAL_ 1471 BatteryEndOfCharge 3 "FalseTrue_NotAvaiable" 2 "FalseTrue_Error" 1 "FalseTrue_True" 0 "FalseTrue_False" ;
VAL_ 1471 BatteryExchangeDetect_1 7 "BatteryExchangeDetectionStat_NotAvailable" 6 "BatteryExchangeDetectionStat_Error" 5 "BatteryExchangeDetectionStat_Spare2" 4 "BatteryExchangeDetectionStat_Spare1" 3 "BatteryExchangeDetectionStat_ExchangeNotDetected" 2 "BatteryExchangeDetectionStat_ExchangeDetected" 1 "BatteryExchangeDetectionStat_AlgorithmRunning" 0 "BatteryExchangeDetectionStat_AlgorithmNotRunning" ;
VAL_ 1471 BatterySOHTrustLevel_stat1_1 15 "BatteryTrustLevel_NotAvailable" 14 "BatteryTrustLevel_Error" 13 "BatteryTrustLevel_Spare9" 12 "BatteryTrustLevel_Spare8" 11 "BatteryTrustLevel_Spare7" 10 "BatteryTrustLevel_Spare6" 9 "BatteryTrustLevel_Spare5" 8 "BatteryTrustLevel_Spare4" 7 "BatteryTrustLevel_Spare3" 6 "BatteryTrustLevel_Spare2" 5 "BatteryTrustLevel_Spare1" 4 "BatteryTrustLevel_NominalPlus15PercentAndAbove" 3 "BatteryTrustLevel_NominalPlus10Percent" 2 "BatteryTrustLevel_NominalPlus5Percent" 1 "BatteryTrustLevel_NominalAccuracy" 0 "BatteryTrustLevel_NotInitialized" ;
VAL_ 1471 BatterySOHPowerTrustLevel1_1 15 "BatteryTrustLevel_NotAvailable" 14 "BatteryTrustLevel_Error" 13 "BatteryTrustLevel_Spare9" 12 "BatteryTrustLevel_Spare8" 11 "BatteryTrustLevel_Spare7" 10 "BatteryTrustLevel_Spare6" 9 "BatteryTrustLevel_Spare5" 8 "BatteryTrustLevel_Spare4" 7 "BatteryTrustLevel_Spare3" 6 "BatteryTrustLevel_Spare2" 5 "BatteryTrustLevel_Spare1" 4 "BatteryTrustLevel_NominalPlus15PercentAndAbove" 3 "BatteryTrustLevel_NominalPlus10Percent" 2 "BatteryTrustLevel_NominalPlus5Percent" 1 "BatteryTrustLevel_NominalAccuracy" 0 "BatteryTrustLevel_NotInitialized" ;
SIG_GROUP_ 947 FrontLevRefCtrl_sg 1 : FrontLevRefCtrl_ShortPushCnt FrontLevRefCtrl_LevelRef;
SIG_GROUP_ 947 FPBRMMIStat_sg 1 : FPBRMMIStat_FPBRChangeAck FPBRMMIStat_FPBRStatusInd;
SIG_GROUP_ 1339 FrontConspicLamp_stat_sg 1 : FrontConspicLamp_stat_HiRight FrontConspicLamp_stat_LoRight FrontConspicLamp_stat_HiLeft FrontConspicLamp_stat_LoLeft;
SIG_GROUP_ 1500 DiagFaultStat_RCIOM_sg 1 : DiagFaultStat_RCIOM_DtcIdB DiagFaultStat_RCIOM_FailTA DiagFaultStat_RCIOM_FailTB DiagFaultStat_RCIOM_DtcIdA DiagFaultStat_RCIOM_EcuAdr;
SIG_GROUP_ 1497 DiagFaultStat_GFHCM2_sg 1 : DiagFaultStat_GFHCM2_DtcIdA DiagFaultStat_GFHCM2_FailTB DiagFaultStat_GFHCM2_DtcIdB DiagFaultStat_GFHCM2_EcuAdr DiagFaultStat_GFHCM2_FailTA;
SIG_GROUP_ 1496 DiagFaultStat_GFHCM1_sg 1 : DiagFaultStat_GFHCM1_EcuAdr DiagFaultStat_GFHCM1_DtcIdB DiagFaultStat_GFHCM1_FailTB DiagFaultStat_GFHCM1_FailTA DiagFaultStat_GFHCM1_DtcIdA;
SIG_GROUP_ 1499 DiagFaultStat_FCIOM_sg 1 : DiagFaultStat_FCIOM_DtcIdA DiagFaultStat_FCIOM_FailTA DiagFaultStat_FCIOM_FailTB DiagFaultStat_FCIOM_DtcIdB DiagFaultStat_FCIOM_EcuAdr;
SIG_GROUP_ 1490 DiagFaultStat_CCIOM_sg 1 : DiagFaultStat_CCIOM_EcuAdr DiagFaultStat_CCIOM_FailTA DiagFaultStat_CCIOM_DtcIdB DiagFaultStat_CCIOM_FailTB DiagFaultStat_CCIOM_DtcIdA;
SIG_GROUP_ 1444 BatteryCapacityGrpAck_sg 1 : BatteryCapacityGrpAck_Pos3 BatteryCapacityGrpAck_Pos2 BatteryCapacityGrpAck_Pos1;
